VERSION ""

NS_ :

BS_:

BU_: EOCM2B_IMX6_HS EOCM2A_IMX6_HS EOCM2B_K2_HS EOCM2A_K2_HS TTPM_HS AMM_HS EBOOST_OBD_HS CGM_HS BSM_HS HCP_B_HS AVM_HS PFAF_HS LVMPC_HS DCDC_HS DEFC_HS VPM_HS IPC_HS V2V_HS TCP_HS CSM_HS EOCM2B_K1_HS EOCM2A_K1_HS TRCM_HS ESCM_SP_HS ICCM_B_HS AMP_HS FICM_HS ARS_HS MCP_B_HS MCP_A_HS ICCM_OBD_HS SAS_HS ACCM_HS VLBS_HS EBCM_OBD_HS HCP_T_HS EDI_HS PLCM_HS VITM_OBD_HS VICM_HS HCP_HS APPS_HS ICCM_HS EOCM_F_HS GPCM_HS VCM_HS HMIM_HS VES_HS Dummy_HS MCP_C_HS ONSTAR_HS EPS_HS TestTool_HS MCP_HS BCP_HS ALC_HS AHL_AFL_HS SADS_HS EPB_HS FCM_HS TCCM_HS RDCM_HS PTO_HS EBCM_HS ACC_HS BCM_HS TCM_HS ECM_HS

BO_ 1323 Tire_Temperature_Sensors_HS: 4 BCM_HS
 SG_ TireLRTmpV : 31|1@0+ (1,0) [0|1] ""  CGM_HS,LVMPC_HS,EDI_HS,EBCM_OBD_HS,EBCM_HS,ICCM_B_HS,ICCM_OBD_HS,ICCM_HS,RDCM_HS
 SG_ TireLRTmp : 30|7@0+ (1,-20) [-20|107] "deg C"  CGM_HS,LVMPC_HS,EDI_HS,EBCM_OBD_HS,EBCM_HS,ICCM_B_HS,ICCM_OBD_HS,ICCM_HS,RDCM_HS
 SG_ TireLFTmpV : 23|1@0+ (1,0) [0|1] ""  CGM_HS,LVMPC_HS,EDI_HS,EBCM_OBD_HS,EBCM_HS,ICCM_B_HS,ICCM_OBD_HS,ICCM_HS,RDCM_HS
 SG_ TireLFTmp : 22|7@0+ (1,-20) [-20|107] "deg C"  CGM_HS,LVMPC_HS,EDI_HS,EBCM_OBD_HS,EBCM_HS,ICCM_B_HS,ICCM_OBD_HS,ICCM_HS,RDCM_HS
 SG_ TireRRTmpV : 15|1@0+ (1,0) [0|1] ""  CGM_HS,LVMPC_HS,EDI_HS,EBCM_OBD_HS,EBCM_HS,ICCM_B_HS,ICCM_OBD_HS,ICCM_HS,RDCM_HS
 SG_ TireRRTmp : 14|7@0+ (1,-20) [-20|107] "deg C"  CGM_HS,LVMPC_HS,EDI_HS,EBCM_OBD_HS,EBCM_HS,ICCM_B_HS,ICCM_OBD_HS,ICCM_HS,RDCM_HS
 SG_ TireRFTmpV : 7|1@0+ (1,0) [0|1] ""  CGM_HS,LVMPC_HS,EDI_HS,EBCM_OBD_HS,EBCM_HS,ICCM_B_HS,ICCM_OBD_HS,ICCM_HS,RDCM_HS
 SG_ TireRFTmp : 6|7@0+ (1,-20) [-20|107] "deg C"  CGM_HS,LVMPC_HS,EDI_HS,EBCM_OBD_HS,EBCM_HS,ICCM_B_HS,ICCM_OBD_HS,ICCM_HS,RDCM_HS

BO_ 1247 PPEI_Chassis_Sys_General_Stat_2: 2 ICCM_HS
 SG_ RrPTCoolFanStatV : 7|1@0+ (1,0) [0|1] ""  CGM_HS,TCM_HS
 SG_ RrPTCoolFanStat : 6|1@0+ (1,0) [0|1] ""  CGM_HS,TCM_HS
 SG_ RrPTCoolFanSpPctCmd : 15|8@0+ (0.392157,0) [0|100.000035] "%"  CGM_HS,TCM_HS

BO_ 723 Prfrmnc_Trctn_Cntrl_Eng_Stat_HS: 4 ECM_HS
 SG_ TachEngSpd : 20|13@0+ (1,0) [0|8191] "rpm"  CGM_HS,BCM_HS
 SG_ PerfTrcEngSpdRqStat : 10|3@0+ (1,0) [0|7] ""  CGM_HS,EBCM_OBD_HS,EBCM_HS
 SG_ PerfTrcEngSpdLmtStat : 12|2@0+ (1,0) [0|3] ""  CGM_HS,EBCM_OBD_HS,EBCM_HS
 SG_ PerfTrcTrqRqStat : 2|3@0+ (1,0) [0|7] ""  CGM_HS,EBCM_OBD_HS,EBCM_HS
 SG_ PerfTrcTrqLmtStat : 4|2@0+ (1,0) [0|3] ""  CGM_HS,EBCM_OBD_HS,EBCM_HS

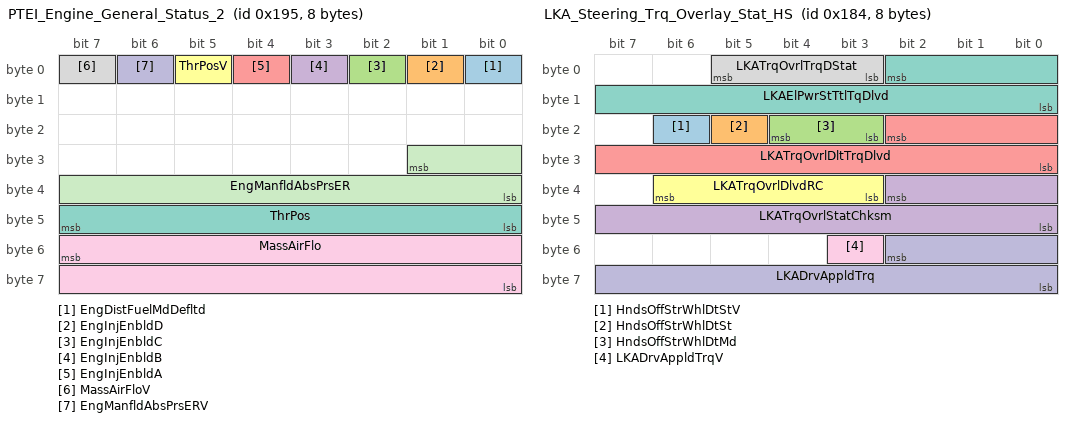
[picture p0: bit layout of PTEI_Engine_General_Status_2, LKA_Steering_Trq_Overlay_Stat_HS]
BO_ 405 PTEI_Engine_General_Status_2: 8 ECM_HS
 SG_ EngDistFuelMdDefltd : 0|1@0+ (1,0) [0|1] ""  CGM_HS,FICM_HS
 SG_ EngInjEnbldD : 1|1@0+ (1,0) [0|1] ""  CGM_HS,FICM_HS
 SG_ EngInjEnbldC : 2|1@0+ (1,0) [0|1] ""  CGM_HS,FICM_HS
 SG_ EngInjEnbldB : 3|1@0+ (1,0) [0|1] ""  CGM_HS,FICM_HS
 SG_ EngInjEnbldA : 4|1@0+ (1,0) [0|1] ""  CGM_HS,FICM_HS
 SG_ ThrPosV : 5|1@0+ (1,0) [0|1] ""  CGM_HS,FICM_HS
 SG_ ThrPos : 47|8@0+ (0.392157,0) [0|100.000035] "%"  CGM_HS,FICM_HS
 SG_ MassAirFloV : 7|1@0+ (1,0) [0|1] ""  CGM_HS,VCM_HS,FICM_HS
 SG_ MassAirFlo : 55|16@0+ (0.01,0) [0|655.35] "grams/s"  CGM_HS,VCM_HS,FICM_HS
 SG_ EngManfldAbsPrsERV : 6|1@0+ (1,0) [0|1] ""  CGM_HS,FICM_HS
 SG_ EngManfldAbsPrsER : 25|10@0+ (0.5,0) [0|511.5] "kPa"  CGM_HS,FICM_HS

BO_ 419 PTEI_Engine_Common_Use_1: 1 ECM_HS
 SG_ ClrCGMLgsDgInf : 6|1@0+ (1,0) [0|1] ""  CGM_HS
 SG_ EngRunng : 7|1@0+ (1,0) [0|1] ""  CGM_HS,TCP_HS,ONSTAR_HS,HCP_B_HS,HCP_T_HS,BCM_HS,DCDC_HS,TCCM_HS,EBCM_OBD_HS,EBCM_HS,MCP_C_HS,MCP_B_HS,MCP_A_HS,FICM_HS,TCM_HS,HCP_HS,BCP_HS

BO_ 289 ADASIS_RawData_Multiplexed_HS: 8 HMIM_HS
 SG_ ARDM_RawData : 4|61@0+ (1,0) [0|2.3058430092e+18] ""  CGM_HS,FCM_HS,EOCM_F_HS,V2V_HS
 SG_ ARDM_MsgType : 7|3@0+ (1,0) [0|7] ""  CGM_HS,FCM_HS,EOCM_F_HS,V2V_HS

BO_ 1268 PPEI_Engine_General_Status_9: 2 ECM_HS
 SG_ EngAirFltLfRmn : 14|7@0+ (1,0) [0|127] "%"  CGM_HS,BCM_HS
 SG_ EngAirFltMonSt : 2|3@0+ (1,0) [0|7] ""  CGM_HS,BCM_HS

BO_ 800 CIB_Autonomous_Braking_Req_HS: 6 FCM_HS
 SG_ FCACtrlBrkSysCmdPrtVl : 27|20@0+ (1,0) [0|1048575] ""  EOCM2A_K1_HS,EBCM_OBD_HS,EBCM_HS
 SG_ FCACBSC_CtrlAcc : 11|12@0- (0.01,0) [-20.48|20.47] "m/s^2"  EOCM2A_K1_HS,EBCM_OBD_HS,EBCM_HS
 SG_ FCACBSC_AutBrkRpRt : 14|3@0+ (1,0) [0|7] ""  EOCM2A_K1_HS,EBCM_OBD_HS,EBCM_HS
 SG_ FCACBSC_AutBrkRqTp : 2|4@0+ (1,0) [0|15] ""  EOCM2A_K1_HS,EBCM_OBD_HS,EBCM_HS
 SG_ FCACBSC_AutBrkRqd : 3|1@0+ (1,0) [0|1] ""  EOCM2A_K1_HS,EBCM_OBD_HS,EBCM_HS
 SG_ FCACtrlBrkSysCmdRC : 5|2@0+ (1,0) [0|3] ""  EBCM_OBD_HS,EBCM_HS,EOCM2A_K1_HS

BO_ 388 LKA_Steering_Trq_Overlay_Stat_HS: 8 EPS_HS
 SG_ HndsOffStrWhlDtStV : 22|1@0+ (1,0) [0|1] ""  CGM_HS,EOCM_F_HS,FCM_HS
 SG_ HndsOffStrWhlDtSt : 21|1@0+ (1,0) [0|1] ""  CGM_HS,EOCM_F_HS,FCM_HS
 SG_ HndsOffStrWhlDtMd : 20|2@0+ (1,0) [0|3] ""  CGM_HS,EOCM_F_HS,FCM_HS
 SG_ LKATrqOvrlStatChksm : 34|11@0+ (1,0) [0|2047] ""  CGM_HS,EOCM_F_HS,FCM_HS
 SG_ LKATrqOvrlDltTrqDlvd : 18|11@0- (0.01,0) [-10.24|10.23] "Nm"  CGM_HS,EOCM_F_HS,FCM_HS
 SG_ LKATrqOvrlDlvdRC : 38|4@0+ (1,0) [0|15] ""  CGM_HS,EOCM_F_HS,FCM_HS
 SG_ LKAElPwrStTtlTqDlvd : 2|11@0- (0.01,0) [-10.24|10.23] "Nm"  CGM_HS,EOCM_F_HS,FCM_HS
 SG_ LKATrqOvrlTrqDStat : 5|3@0+ (1,0) [0|7] ""  CGM_HS,EOCM_F_HS,FCM_HS
 SG_ LKADrvAppldTrqV : 51|1@0+ (1,0) [0|1] ""  CGM_HS,EOCM_F_HS,FCM_HS
 SG_ LKADrvAppldTrq : 50|11@0- (0.01,0) [-10.24|10.23] "Nm"  CGM_HS,EOCM_F_HS,FCM_HS

BO_ 384 LKA_Steering_Torque_Cmd_HS: 4 FCM_HS
 SG_ LKATqOvrDltCmdPrtVl : 19|12@0+ (1,0) [0|4095] ""  EPS_HS
 SG_ LKATqOvrDltCmdRC : 5|2@0+ (1,0) [0|3] ""  EPS_HS
 SG_ LKATODC_TrqVl : 2|11@0- (0.01,0) [-10.24|10.23] "Nm"  BCM_HS,EPS_HS
 SG_ LKATODC_TrqRqAct : 3|1@0+ (1,0) [0|1] ""  BCM_HS,EPS_HS

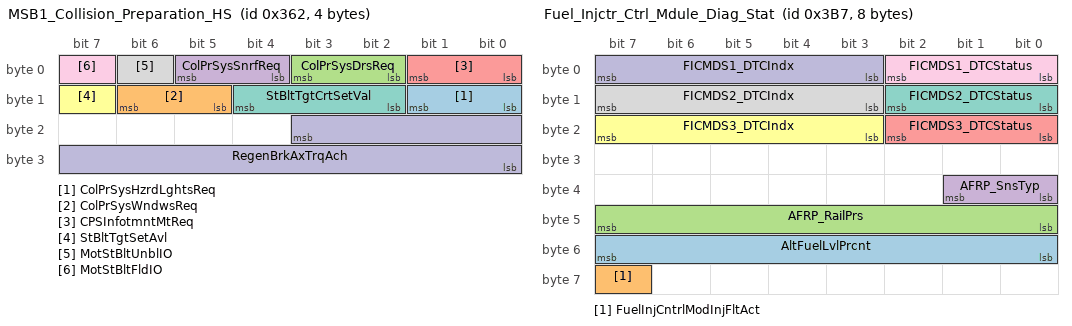
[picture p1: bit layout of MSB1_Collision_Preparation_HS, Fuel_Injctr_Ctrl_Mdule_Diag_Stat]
BO_ 866 MSB1_Collision_Preparation_HS: 4 EBCM_HS
 SG_ ColPrSysHzrdLghtsReq : 9|2@0+ (1,0) [0|3] ""  CGM_HS,BCM_HS
 SG_ ColPrSysWndwsReq : 14|2@0+ (1,0) [0|3] ""  CGM_HS,BCM_HS
 SG_ ColPrSysDrsReq : 3|2@0+ (1,0) [0|3] ""  CGM_HS,BCM_HS
 SG_ ColPrSysSnrfReq : 5|2@0+ (1,0) [0|3] ""  CGM_HS,BCM_HS
 SG_ CPSInfotmntMtReq : 1|2@0+ (1,0) [0|3] ""  CGM_HS,BCM_HS
 SG_ StBltTgtSetAvl : 15|1@0+ (1,0) [0|1] ""  CGM_HS,BCM_HS
 SG_ StBltTgtCrtSetVal : 12|3@0+ (1,0) [0|7] ""  CGM_HS,BCM_HS
 SG_ MotStBltUnblIO : 6|1@0+ (1,0) [0|1] ""  CGM_HS,BCM_HS
 SG_ MotStBltFldIO : 7|1@0+ (1,0) [0|1] ""  CGM_HS,BCM_HS
 SG_ RegenBrkAxTrqAch : 19|12@0+ (2,0) [0|8190] "Nm"  CGM_HS,BSM_HS,VICM_HS

BO_ 951 Fuel_Injctr_Ctrl_Mdule_Diag_Stat: 8 FICM_HS
 SG_ AltFuelLvlPrcnt : 55|8@0+ (0.392157,0) [0|100.000035] "%"  CGM_HS,ECM_HS
 SG_ FuelInjCntrlModInjFltAct : 63|1@0+ (1,0) [0|1] ""  CGM_HS,ECM_HS
 SG_ AFRP_RailPrs : 47|8@0+ (3,0) [0|765] "kPa"  CGM_HS,ECM_HS
 SG_ AFRP_SnsTyp : 33|2@0+ (1,0) [0|3] ""  CGM_HS,ECM_HS
 SG_ FICMDS3_DTCStatus : 18|3@0+ (1,0) [0|7] ""  CGM_HS,ECM_HS
 SG_ FICMDS3_DTCIndx : 23|5@0+ (1,0) [0|31] ""  CGM_HS,ECM_HS
 SG_ FICMDS2_DTCStatus : 10|3@0+ (1,0) [0|7] ""  CGM_HS,ECM_HS
 SG_ FICMDS2_DTCIndx : 15|5@0+ (1,0) [0|31] ""  CGM_HS,ECM_HS
 SG_ FICMDS1_DTCStatus : 2|3@0+ (1,0) [0|7] ""  CGM_HS,ECM_HS
 SG_ FICMDS1_DTCIndx : 7|5@0+ (1,0) [0|31] ""  CGM_HS,ECM_HS

BO_ 949 FICM_BiFuel_Control_Requests: 8 FICM_HS
 SG_ AltFuelRFuelTrmLmtOff : 61|6@0- (0.01,0) [-0.32|0.31] ""  CGM_HS,ECM_HS
 SG_ AltFuelLnFuelTrmLmtOff : 53|6@0- (0.01,0) [-0.32|0.31] ""  CGM_HS,ECM_HS
 SG_ AltFuelInjMinPlsOffst : 39|8@0- (0.0313725,0) [-4.01568|3.9843075] "grams/s"  CGM_HS,ECM_HS
 SG_ AltFuelInjOpnOffst : 31|8@0- (0.0313725,0) [-4.01568|3.9843075] "grams/s"  CGM_HS,ECM_HS
 SG_ AltFuelInjFlwOffst : 23|8@0- (0.0313725,0) [-4.01568|3.9843075] "grams/s"  CGM_HS,ECM_HS
 SG_ AltFuelEqvlntRatBsOffst : 15|8@0- (0.000392157,0) [-0.050196096|0.049803939] ""  CGM_HS,ECM_HS
 SG_ AltFuelPst02BsOffst : 7|8@0- (4,0) [-512|508] "mVolts"  CGM_HS,ECM_HS

BO_ 1223 PPEI_Propulsion_Sys_Gen_Status: 3 ECM_HS
 SG_ PropSysOffTmeV : 5|1@0+ (1,0) [0|1] ""  CGM_HS,HCP_B_HS,HCP_T_HS,EBCM_OBD_HS,EBCM_HS,MCP_C_HS,TCM_HS,HCP_HS,BCP_HS,MCP_B_HS,MCP_A_HS,BSM_HS,VICM_HS
 SG_ PropSysOffTmeM : 4|1@0+ (1,0) [0|1] ""  CGM_HS,HCP_B_HS,BSM_HS,HCP_T_HS,EBCM_OBD_HS,EBCM_HS,MCP_C_HS,TCM_HS,HCP_HS,BCP_HS,MCP_B_HS,MCP_A_HS,VICM_HS
 SG_ PropSysOffTme : 3|12@0+ (0.5,0) [0|2047.5] "min"  CGM_HS,HCP_B_HS,BSM_HS,HCP_T_HS,EBCM_OBD_HS,EBCM_HS,MCP_C_HS,TCM_HS,HCP_HS,BCP_HS,MCP_B_HS,MCP_A_HS,VICM_HS

BO_ 1227 PPEI_Charging_System_Gen_Status: 4 VICM_HS
 SG_ BattThrmlCondOffTmeV : 21|1@0+ (1,0) [0|1] ""  CGM_HS,HCP_T_HS,TCM_HS,HCP_HS,ECM_HS
 SG_ BattThrmlCondOffTmeM : 20|1@0+ (1,0) [0|1] ""  CGM_HS,HCP_T_HS,TCM_HS,HCP_HS,ECM_HS
 SG_ BattThrmlCondOffTme : 19|12@0+ (0.5,0) [0|2047.5] "min"  CGM_HS,HCP_T_HS,TCM_HS,HCP_HS,ECM_HS
 SG_ OffBrdChrgOffTmeV : 5|1@0+ (1,0) [0|1] ""  CGM_HS,HCP_T_HS,TCM_HS,HCP_HS,ECM_HS
 SG_ OffBrdChrgOffTmeM : 4|1@0+ (1,0) [0|1] ""  CGM_HS,HCP_T_HS,TCM_HS,HCP_HS,ECM_HS
 SG_ OffBrdChrgOffTme : 3|12@0+ (0.5,0) [0|2047.5] "min"  CGM_HS,HCP_T_HS,TCM_HS,HCP_HS,ECM_HS

BO_ 543 PTO_Customization_Request_HS: 3 BCM_HS
 SG_ HdStV : 3|1@0+ (1,0) [0|1] ""  CGM_HS,PTO_HS
 SG_ HdSt : 5|2@0+ (1,0) [0|3] ""  CGM_HS,PTO_HS
 SG_ PTOTpStpSpdCsStReq : 2|3@0+ (1,0) [0|7] ""  CGM_HS,PTO_HS
 SG_ PTOStdbySpdCsStReq : 14|3@0+ (1,0) [0|7] ""  CGM_HS,PTO_HS
 SG_ PTOEngRnTmrCsStRq : 11|4@0+ (1,0) [0|15] ""  CGM_HS,PTO_HS
 SG_ PTOSet2SpdCsStReq : 23|4@0+ (1,0) [0|15] ""  CGM_HS,PTO_HS
 SG_ PTOSet1SpdCsStReq : 19|4@0+ (1,0) [0|15] ""  CGM_HS,PTO_HS

BO_ 544 PTO_Status_HS: 5 PTO_HS
 SG_ PTOMobModTrnsInGrIO : 31|1@0+ (1,0) [0|1] ""  CGM_HS,BCM_HS
 SG_ PTOManTransInGrIO : 21|1@0+ (1,0) [0|1] ""  CGM_HS,BCM_HS
 SG_ PTOServIndOn : 20|1@0+ (1,0) [0|1] ""  CGM_HS,BCM_HS
 SG_ PTOEngUpnBrkRelIO : 23|1@0+ (1,0) [0|1] ""  CGM_HS,BCM_HS
 SG_ PTOAccelUpnBrkRelIO : 22|1@0+ (1,0) [0|1] ""  CGM_HS,BCM_HS
 SG_ PTOAudExtAlertReq : 19|1@0+ (1,0) [0|1] ""  CGM_HS,BCM_HS
 SG_ PTOTransInGearIO : 13|1@0+ (1,0) [0|1] ""  CGM_HS,BCM_HS
 SG_ PTOTpStpSpdCsStAvl : 10|1@0+ (1,0) [0|1] ""  CGM_HS,BCM_HS
 SG_ PTOTpStSpdCsCrStVal : 26|3@0+ (1,0) [0|7] ""  CGM_HS,BCM_HS
 SG_ PTOStdbySpdCsStAvl : 12|1@0+ (1,0) [0|1] ""  CGM_HS,BCM_HS
 SG_ PTOStdbSpdCsCrStVal : 18|3@0+ (1,0) [0|7] ""  CGM_HS,BCM_HS
 SG_ PTOSetPrkBrkIO : 14|1@0+ (1,0) [0|1] ""  CGM_HS,BCM_HS
 SG_ PTOSet2SpdCsStAvl : 9|1@0+ (1,0) [0|1] ""  CGM_HS,BCM_HS
 SG_ PTOSet2SpdCsCrStVal : 39|4@0+ (1,0) [0|15] ""  CGM_HS,BCM_HS
 SG_ PTOSet1SpdCsStAvl : 8|1@0+ (1,0) [0|1] ""  CGM_HS,BCM_HS
 SG_ PTOSet1SpdCsCrStVal : 35|4@0+ (1,0) [0|15] ""  CGM_HS,BCM_HS
 SG_ PTORelCltPedIO : 15|1@0+ (1,0) [0|1] ""  CGM_HS,BCM_HS
 SG_ PTORelBrkPedIO : 0|1@0+ (1,0) [0|1] ""  CGM_HS,BCM_HS
 SG_ PTORelAccPedIO : 1|1@0+ (1,0) [0|1] ""  CGM_HS,BCM_HS
 SG_ PTORedEngSpdIO : 2|1@0+ (1,0) [0|1] ""  CGM_HS,BCM_HS
 SG_ PTOPrsRelCltPedIO : 3|1@0+ (1,0) [0|1] ""  CGM_HS,BCM_HS
 SG_ PTOPrsRelBrkPedIO : 4|1@0+ (1,0) [0|1] ""  CGM_HS,BCM_HS
 SG_ PTOEngRnTmrCsStAvl : 11|1@0+ (1,0) [0|1] ""  CGM_HS,BCM_HS
 SG_ PTOEnRnTmCsCrStVal : 30|4@0+ (1,0) [0|15] ""  CGM_HS,BCM_HS
 SG_ PTOEngmntStatInd : 6|2@0+ (1,0) [0|3] ""  CGM_HS,BCM_HS
 SG_ PTODisengCrsCntlIO : 7|1@0+ (1,0) [0|1] ""  CGM_HS,BCM_HS

BO_ 901 PTEI_Hybrid_Trans_Status_3: 3 TCM_HS
 SG_ TrnsMtrBCoolFlwEst : 15|8@0+ (0.05,0) [0|12.75] "l/min"  CGM_HS,HCP_HS
 SG_ TrnsMtrACoolFlwEst : 7|8@0+ (0.05,0) [0|12.75] "l/min"  CGM_HS,HCP_HS
 SG_ TrnsLubeFlwEst : 23|8@0+ (0.0625,0) [0|15.9375] "l/min"  CGM_HS,HCP_HS

BO_ 1032 LGT_ControlHighBeamGlare_HS: 2 FCM_HS
 SG_ RdTyp : 5|3@0+ (1,0) [0|7] ""  CGM_HS,EOCM2B_K1_HS,AHL_AFL_HS
 SG_ FwdCamSysOpStat : 10|3@0+ (1,0) [0|7] ""  CGM_HS,EOCM2B_K1_HS,AHL_AFL_HS
 SG_ EnvIllum : 2|3@0+ (1,0) [0|7] ""  CGM_HS,EOCM2B_K1_HS,AHL_AFL_HS
 SG_ AutoHgBmSts : 7|2@0+ (1,0) [0|3] ""  CGM_HS,EOCM2B_K1_HS,AHL_AFL_HS

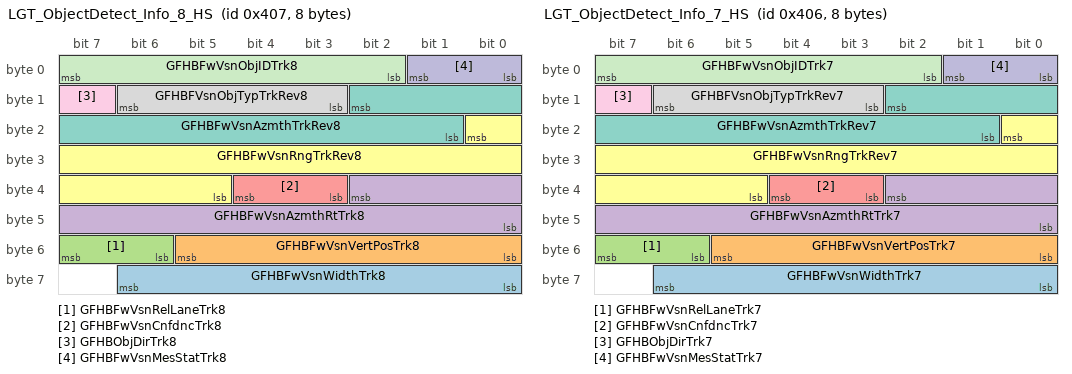
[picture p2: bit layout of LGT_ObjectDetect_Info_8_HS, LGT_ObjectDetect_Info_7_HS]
BO_ 1031 LGT_ObjectDetect_Info_8_HS: 8 EOCM_F_HS
 SG_ GFHBFwVsnWidthTrk8 : 62|7@0+ (0.1,0) [0|12.7] "deg"  CGM_HS,EOCM2B_K1_HS,AHL_AFL_HS
 SG_ GFHBFwVsnVertPosTrk8 : 53|6@0+ (0.25,-3) [-3|12.75] "deg"  CGM_HS,EOCM2B_K1_HS,AHL_AFL_HS
 SG_ GFHBFwVsnRelLaneTrk8 : 55|2@0+ (1,0) [0|3] ""  CGM_HS,EOCM2B_K1_HS,AHL_AFL_HS
 SG_ GFHBFwVsnAzmthRtTrk8 : 34|11@0- (0.125,0) [-128|127.875] "deg/s"  CGM_HS,EOCM2B_K1_HS,AHL_AFL_HS
 SG_ GFHBFwVsnCnfdncTrk8 : 36|2@0+ (1,0) [0|3] ""  CGM_HS,EOCM2B_K1_HS,AHL_AFL_HS
 SG_ GFHBFwVsnRngTrkRev8 : 16|12@0+ (0.2,0) [0|819] "m"  CGM_HS,EOCM2B_K1_HS,AHL_AFL_HS
 SG_ GFHBFwVsnAzmthTrkRev8 : 10|10@0- (0.05,0) [-25.6|25.55] "deg"  CGM_HS,EOCM2B_K1_HS,AHL_AFL_HS
 SG_ GFHBFVsnObjTypTrkRev8 : 14|4@0+ (1,0) [0|15] ""  CGM_HS,EOCM2B_K1_HS,AHL_AFL_HS
 SG_ GFHBObjDirTrk8 : 15|1@0+ (1,0) [0|1] ""  CGM_HS,EOCM2B_K1_HS,AHL_AFL_HS
 SG_ GFHBFwVsnMesStatTrk8 : 1|2@0+ (1,0) [0|3] ""  CGM_HS,EOCM2B_K1_HS,AHL_AFL_HS
 SG_ GFHBFwVsnObjIDTrk8 : 7|6@0+ (1,0) [0|63] ""  CGM_HS,EOCM2B_K1_HS,AHL_AFL_HS

BO_ 1030 LGT_ObjectDetect_Info_7_HS: 8 EOCM_F_HS
 SG_ GFHBFwVsnWidthTrk7 : 62|7@0+ (0.1,0) [0|12.7] "deg"  CGM_HS,EOCM2B_K1_HS,AHL_AFL_HS
 SG_ GFHBFwVsnVertPosTrk7 : 53|6@0+ (0.25,-3) [-3|12.75] "deg"  CGM_HS,EOCM2B_K1_HS,AHL_AFL_HS
 SG_ GFHBFwVsnRelLaneTrk7 : 55|2@0+ (1,0) [0|3] ""  CGM_HS,EOCM2B_K1_HS,AHL_AFL_HS
 SG_ GFHBFwVsnAzmthRtTrk7 : 34|11@0- (0.125,0) [-128|127.875] "deg/s"  CGM_HS,EOCM2B_K1_HS,AHL_AFL_HS
 SG_ GFHBFwVsnCnfdncTrk7 : 36|2@0+ (1,0) [0|3] ""  CGM_HS,EOCM2B_K1_HS,AHL_AFL_HS
 SG_ GFHBFwVsnRngTrkRev7 : 16|12@0+ (0.2,0) [0|819] "m"  CGM_HS,EOCM2B_K1_HS,AHL_AFL_HS
 SG_ GFHBFwVsnAzmthTrkRev7 : 10|10@0- (0.05,0) [-25.6|25.55] "deg"  CGM_HS,EOCM2B_K1_HS,AHL_AFL_HS
 SG_ GFHBFVsnObjTypTrkRev7 : 14|4@0+ (1,0) [0|15] ""  CGM_HS,EOCM2B_K1_HS,AHL_AFL_HS
 SG_ GFHBObjDirTrk7 : 15|1@0+ (1,0) [0|1] ""  CGM_HS,EOCM2B_K1_HS,AHL_AFL_HS
 SG_ GFHBFwVsnMesStatTrk7 : 1|2@0+ (1,0) [0|3] ""  CGM_HS,EOCM2B_K1_HS,AHL_AFL_HS
 SG_ GFHBFwVsnObjIDTrk7 : 7|6@0+ (1,0) [0|63] ""  CGM_HS,EOCM2B_K1_HS,AHL_AFL_HS

BO_ 479 PPEI_Propulsion_Gen_Stat_1_HS: 3 HCP_HS
 SG_ PTAVHEnbld : 4|1@0+ (1,0) [0|1] ""  CGM_HS,EBCM_OBD_HS,EBCM_HS
 SG_ PTAVHActv : 3|1@0+ (1,0) [0|1] ""  CGM_HS,EBCM_OBD_HS,EBCM_HS
 SG_ EngAutoStpNotProb : 2|1@0+ (1,0) [0|1] ""  CGM_HS,TCM_HS,ECM_HS,BCM_HS
 SG_ EASSI_UnsdRsrvd2 : 8|1@0+ (1,0) [0|1] ""  TCP_HS,ONSTAR_HS,FCM_HS,EOCM_F_HS,ESCM_SP_HS,CGM_HS,TCM_HS,ECM_HS,BCM_HS,EBCM_OBD_HS,EBCM_HS,TCCM_HS
 SG_ EASSI_StlDetd : 10|1@0+ (1,0) [0|1] ""  TCP_HS,ONSTAR_HS,FCM_HS,EOCM_F_HS,ESCM_SP_HS,CGM_HS,TCM_HS,ECM_HS,BCM_HS,EBCM_OBD_HS,EBCM_HS,TCCM_HS
 SG_ EASSI_TrqDetd : 11|1@0+ (1,0) [0|1] ""  TCP_HS,ONSTAR_HS,FCM_HS,EOCM_F_HS,ESCM_SP_HS,CGM_HS,TCM_HS,ECM_HS,BCM_HS,EBCM_OBD_HS,EBCM_HS,TCCM_HS
 SG_ EASSI_FuelReqOn : 12|1@0+ (1,0) [0|1] ""  TCP_HS,ONSTAR_HS,FCM_HS,EOCM_F_HS,ESCM_SP_HS,CGM_HS,TCM_HS,ECM_HS,BCM_HS,EBCM_OBD_HS,EBCM_HS,TCCM_HS
 SG_ EASSI_StrtTyp : 15|3@0+ (1,0) [0|7] ""  TCP_HS,ONSTAR_HS,FCM_HS,EOCM_F_HS,ESCM_SP_HS,CGM_HS,TCM_HS,ECM_HS,BCM_HS,EBCM_OBD_HS,EBCM_HS,TCCM_HS
 SG_ EASSI_StrtStpSt : 1|2@0+ (1,0) [0|3] ""  TCP_HS,ONSTAR_HS,FCM_HS,EOCM_F_HS,ESCM_SP_HS,CGM_HS,TCM_HS,ECM_HS,BCM_HS,EBCM_OBD_HS,EBCM_HS,TCCM_HS
 SG_ EASSI_TorqDetdIndet : 9|1@0+ (1,0) [0|1] ""  TCP_HS,ONSTAR_HS,FCM_HS,EOCM_F_HS,ESCM_SP_HS,CGM_HS,TCM_HS,ECM_HS,BCM_HS,EBCM_OBD_HS,EBCM_HS,TCCM_HS
 SG_ ASIRI_Indication08 : 16|1@0+ (1,0) [0|1] ""  CGM_HS,BCM_HS
 SG_ ASIRI_Indication07 : 17|1@0+ (1,0) [0|1] ""  CGM_HS,BCM_HS
 SG_ ASIRI_Indication06 : 18|1@0+ (1,0) [0|1] ""  CGM_HS,BCM_HS
 SG_ ASIRI_Indication05 : 19|1@0+ (1,0) [0|1] ""  CGM_HS,BCM_HS
 SG_ ASIRI_Indication04 : 20|1@0+ (1,0) [0|1] ""  CGM_HS,BCM_HS
 SG_ ASIRI_Indication03 : 21|1@0+ (1,0) [0|1] ""  CGM_HS,BCM_HS
 SG_ ASIRI_Indication02 : 22|1@0+ (1,0) [0|1] ""  CGM_HS,BCM_HS
 SG_ ASIRI_Indication01 : 23|1@0+ (1,0) [0|1] ""  CGM_HS,BCM_HS
 SG_ PTWrmgWtToShftIO : 5|1@0+ (1,0) [0|1] ""  CGM_HS,BCM_HS
 SG_ PrplsnSysAtv : 7|1@0+ (1,0) [0|1] ""  TCP_HS,ONSTAR_HS,RDCM_HS,FCM_HS,EOCM_F_HS,V2V_HS,ESCM_SP_HS,EBOOST_OBD_HS,CGM_HS,HCP_T_HS,TRCM_HS,EPB_HS,TCM_HS,ECM_HS,TCCM_HS,BSM_HS,VICM_HS,ICCM_B_HS,ICCM_OBD_HS,ICCM_HS,EBCM_OBD_HS,EBCM_HS,VITM_OBD_HS
 SG_ PTShftLvrLckRqd : 6|1@0+ (1,0) [0|1] ""  CGM_HS,BCM_HS

BO_ 211 PPEI_Hybrid_General_Status_3_HS: 2 HCP_HS
 SG_ ActAxleTrqV : 7|1@0+ (1,0) [0|1] ""  EOCM2B_K2_HS,EOCM2B_K1_HS,EOCM2A_K2_HS,EOCM2A_K1_HS,CSM_HS,HMIM_HS,AMP_HS,CGM_HS,HCP_T_HS,FCM_HS,SADS_HS,ICCM_B_HS,ICCM_OBD_HS,ICCM_HS,TCM_HS,ECM_HS,EPS_HS,EBCM_OBD_HS,EBCM_HS,BCP_HS,BSM_HS,VICM_HS,TCCM_HS,ACC_HS
 SG_ ActAxleTrq : 6|15@0+ (2,-22534) [-22534|43000] "Nm"  EOCM2B_K2_HS,EOCM2B_K1_HS,EOCM2A_K2_HS,EOCM2A_K1_HS,CSM_HS,HMIM_HS,AMP_HS,CGM_HS,HCP_T_HS,FCM_HS,SADS_HS,ICCM_B_HS,ICCM_OBD_HS,ICCM_HS,EBCM_OBD_HS,EBCM_HS,TCM_HS,ECM_HS,BCP_HS,EPS_HS,TCCM_HS,BSM_HS,VICM_HS,ACC_HS

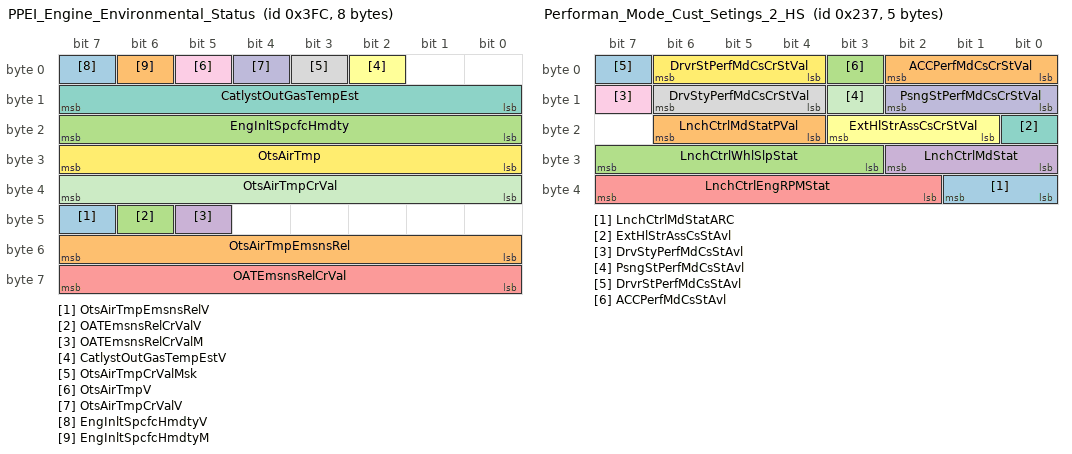
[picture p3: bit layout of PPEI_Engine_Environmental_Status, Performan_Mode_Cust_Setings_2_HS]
BO_ 1020 PPEI_Engine_Environmental_Status: 8 ECM_HS
 SG_ OtsAirTmpEmsnsRelV : 47|1@0+ (1,0) [0|1] ""  CGM_HS,BSM_HS,VICM_HS,HCP_B_HS
 SG_ OtsAirTmpEmsnsRel : 55|8@0+ (0.5,-40) [-40|87.5] "deg C"  CGM_HS,BSM_HS,VICM_HS,HCP_B_HS
 SG_ OATEmsnsRelCrValV : 46|1@0+ (1,0) [0|1] ""  CGM_HS,BSM_HS,VICM_HS,HCP_B_HS
 SG_ OATEmsnsRelCrValM : 45|1@0+ (1,0) [0|1] ""  CGM_HS,BSM_HS,VICM_HS,HCP_B_HS
 SG_ OATEmsnsRelCrVal : 63|8@0+ (0.5,-40) [-40|87.5] "deg C"  CGM_HS,BSM_HS,VICM_HS,HCP_B_HS
 SG_ CatlystOutGasTempEstV : 2|1@0+ (1,0) [0|1] ""  CGM_HS,BSM_HS,VICM_HS
 SG_ CatlystOutGasTempEst : 15|8@0+ (5,-40) [-40|1235] "deg C"  CGM_HS,BSM_HS,VICM_HS
 SG_ OtsAirTmpCrValMsk : 3|1@0+ (1,0) [0|1] ""  EOCM2A_K1_HS,V2V_HS,TCM_HS,EPB_HS,BSM_HS,VICM_HS,BCM_HS
 SG_ OtsAirTmpV : 5|1@0+ (1,0) [0|1] ""  EOCM2A_K1_HS,CGM_HS,EPB_HS,BSM_HS,VICM_HS,PFAF_HS,BCM_HS
 SG_ OtsAirTmpCrValV : 4|1@0+ (1,0) [0|1] ""  EOCM2A_K1_HS,V2V_HS,TCM_HS,EPB_HS,BSM_HS,VICM_HS,BCM_HS
 SG_ OtsAirTmpCrVal : 39|8@0+ (0.5,-40) [-40|87.5] "deg C"  EOCM2A_K1_HS,V2V_HS,TCM_HS,EPB_HS,BSM_HS,VICM_HS,BCM_HS
 SG_ OtsAirTmp : 31|8@0+ (0.5,-40) [-40|87.5] "deg C"  EOCM2A_K1_HS,CGM_HS,EPB_HS,BSM_HS,VICM_HS,PFAF_HS,BCM_HS
 SG_ EngInltSpcfcHmdtyV : 7|1@0+ (1,0) [0|1] ""  CGM_HS,BSM_HS,VICM_HS,BCM_HS,EBCM_OBD_HS,EBCM_HS
 SG_ EngInltSpcfcHmdtyM : 6|1@0+ (1,0) [0|1] ""  CGM_HS,BSM_HS,VICM_HS,BCM_HS,EBCM_OBD_HS,EBCM_HS
 SG_ EngInltSpcfcHmdty : 23|8@0+ (0.0196078,0) [0|4.999989] "% water"  CGM_HS,BSM_HS,VICM_HS,BCM_HS,EBCM_OBD_HS,EBCM_HS

BO_ 567 Performan_Mode_Cust_Setings_2_HS: 5 EBCM_HS
 SG_ LnchCtrlMdStatARC : 33|2@0+ (1,0) [0|3] ""  CGM_HS,ECM_HS
 SG_ LnchCtrlMdStatPVal : 22|3@0+ (1,0) [0|7] ""  CGM_HS,ECM_HS
 SG_ LnchCtrlWhlSlpStat : 31|5@0+ (1,0) [0|31] ""  CGM_HS,BCM_HS
 SG_ LnchCtrlMdStat : 26|3@0+ (1,0) [0|7] ""  CGM_HS,ECM_HS,BCM_HS
 SG_ LnchCtrlEngRPMStat : 39|6@0+ (1,0) [0|63] ""  CGM_HS,BCM_HS
 SG_ ExtHlStrAssCsCrStVal : 19|3@0+ (1,0) [0|7] ""  CGM_HS,BCM_HS
 SG_ ExtHlStrAssCsStAvl : 16|1@0+ (1,0) [0|1] ""  CGM_HS,BCM_HS
 SG_ DrvStyPerfMdCsCrStVal : 14|3@0+ (1,0) [0|7] ""  CGM_HS,BCM_HS
 SG_ DrvStyPerfMdCsStAvl : 15|1@0+ (1,0) [0|1] ""  CGM_HS,BCM_HS
 SG_ PsngStPerfMdCsCrStVal : 10|3@0+ (1,0) [0|7] ""  CGM_HS,BCM_HS
 SG_ PsngStPerfMdCsStAvl : 11|1@0+ (1,0) [0|1] ""  CGM_HS,BCM_HS
 SG_ DrvrStPerfMdCsCrStVal : 6|3@0+ (1,0) [0|7] ""  CGM_HS,BCM_HS
 SG_ DrvrStPerfMdCsStAvl : 7|1@0+ (1,0) [0|1] ""  CGM_HS,BCM_HS
 SG_ ACCPerfMdCsCrStVal : 2|3@0+ (1,0) [0|7] ""  CGM_HS,BCM_HS
 SG_ ACCPerfMdCsStAvl : 3|1@0+ (1,0) [0|1] ""  CGM_HS,BCM_HS

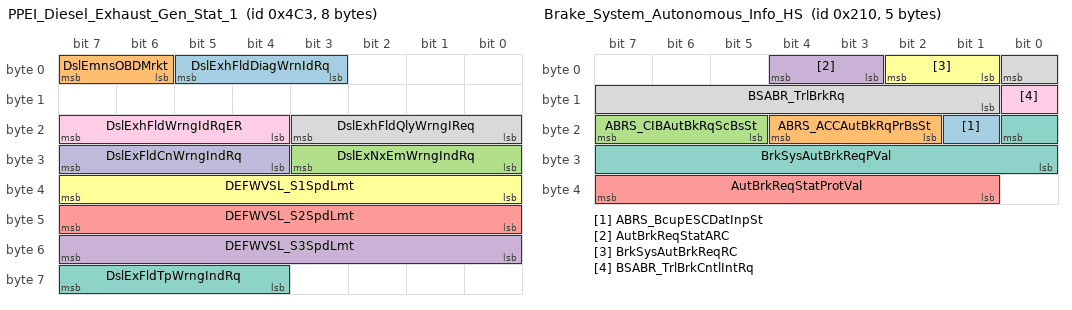
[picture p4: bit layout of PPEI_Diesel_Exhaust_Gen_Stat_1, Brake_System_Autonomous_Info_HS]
BO_ 1219 PPEI_Diesel_Exhaust_Gen_Stat_1: 8 ECM_HS
 SG_ DslExhFldDiagWrnIdRq : 5|3@0+ (1,0) [0|7] ""  CGM_HS,BCM_HS
 SG_ DslEmnsOBDMrkt : 7|2@0+ (1,0) [0|3] ""  CGM_HS,BCM_HS
 SG_ DslExNxEmWrngIndRq : 27|4@0+ (1,0) [0|15] ""  CGM_HS,BCM_HS
 SG_ DEFWVSL_S3SpdLmt : 55|8@0+ (1,0) [0|255] "km / h"  CGM_HS,BCM_HS
 SG_ DEFWVSL_S2SpdLmt : 47|8@0+ (1,0) [0|255] "km / h"  CGM_HS,BCM_HS
 SG_ DEFWVSL_S1SpdLmt : 39|8@0+ (1,0) [0|255] "km / h"  CGM_HS,BCM_HS
 SG_ DslExFldTpWrngIndRq : 63|4@0+ (1,0) [0|15] ""  CGM_HS,BCM_HS
 SG_ DslExhFldQlyWrngIReq : 19|4@0+ (1,0) [0|15] ""  CGM_HS,BCM_HS
 SG_ DslExhFldWrngIdRqER : 23|4@0+ (1,0) [0|15] ""  CGM_HS,BCM_HS,TCP_HS,ONSTAR_HS
 SG_ DslExFldCnWrngIndRq : 31|4@0+ (1,0) [0|15] ""  CGM_HS,BCM_HS

BO_ 372 Active_Rear_Steer_Fail_Indctn_HS: 5 EBCM_HS
 SG_ ARSOpStat : 5|3@0+ (1,0) [0|7] ""  CGM_HS,EOCM2B_K1_HS,EOCM2A_K1_HS,FCM_HS
 SG_ ARSAlgmtCmplt : 1|1@0+ (1,0) [0|1] ""  CGM_HS,FCM_HS,EOCM2B_K1_HS,EOCM2A_K1_HS
 SG_ ARSActAnglV : 2|1@0+ (1,0) [0|1] ""  CGM_HS,FCM_HS,EOCM2B_K1_HS,EOCM2A_K1_HS
 SG_ ARSActAngl : 10|11@0- (0.01,0) [-10.24|10.23] "deg"  CGM_HS,FCM_HS,EOCM2B_K1_HS,EOCM2A_K1_HS
 SG_ ARSActAngStsRegtChksm : 26|11@0+ (1,0) [0|2047] ""  CGM_HS,FCM_HS,EOCM2B_K1_HS,EOCM2A_K1_HS
 SG_ ARSActAngRegtARC : 7|2@0+ (1,0) [0|3] ""  CGM_HS,FCM_HS,EOCM2B_K1_HS,EOCM2A_K1_HS
 SG_ ARSFlrIO : 0|1@0+ (1,0) [0|1] ""  CGM_HS,EOCM2B_K1_HS,EOCM2A_K1_HS,FCM_HS,BCM_HS

BO_ 528 Brake_System_Autonomous_Info_HS: 5 EBCM_HS
 SG_ ABRS_BcupESCDatInpSt : 17|1@0+ (1,0) [0|1] ""  CGM_HS,EOCM2B_K1_HS,EOCM2A_K1_HS
 SG_ ABRS_ACCAutBkRqPrBsSt : 20|3@0+ (1,0) [0|7] ""  CGM_HS,EOCM2B_K1_HS,EOCM2A_K1_HS
 SG_ ABRS_CIBAutBkRqScBsSt : 23|3@0+ (1,0) [0|7] ""  CGM_HS,EOCM2B_K1_HS,EOCM2A_K1_HS
 SG_ AutBrkReqStatARC : 4|2@0+ (1,0) [0|3] ""  CGM_HS,EOCM2B_K1_HS,EOCM2A_K1_HS
 SG_ AutBrkReqStatProtVal : 39|7@0+ (1,0) [0|127] ""  CGM_HS,EOCM2B_K1_HS,EOCM2A_K1_HS
 SG_ BrkSysAutBrkReqRC : 2|2@0+ (1,0) [0|3] ""  CGM_HS,ICCM_B_HS,ICCM_OBD_HS,ICCM_HS
 SG_ BrkSysAutBrkReqPVal : 16|9@0+ (1,0) [0|511] ""  CGM_HS,ICCM_B_HS,ICCM_OBD_HS,ICCM_HS
 SG_ BSABR_TrlBrkRq : 0|8@0+ (0.392157,0) [0|100.000035] "%"  CGM_HS,ICCM_B_HS,ICCM_OBD_HS,ICCM_HS
 SG_ BSABR_TrlBrkCntlIntRq : 8|1@0+ (1,0) [0|1] ""  CGM_HS,ICCM_B_HS,ICCM_OBD_HS,ICCM_HS

BO_ 442 PTEI_Engine_Torque_Status_2: 8 ECM_HS
 SG_ CrksftTqMinImCapV : 5|1@0+ (1,0) [0|1] ""  CGM_HS,TCM_HS
 SG_ CrksftTqMinImCap : 27|12@0+ (0.5,-848) [-848|1199.5] "Nm"  CGM_HS,TCM_HS
 SG_ DrvIntndCrksftTrqRw : 3|12@0+ (0.5,-848) [-848|1199.5] "Nm"  CGM_HS,TCM_HS
 SG_ DrvIntndCrksftTrqMin : 23|12@0+ (0.5,-848) [-848|1199.5] "Nm"  CGM_HS,TCM_HS
 SG_ DrvIntndCrksftTrq : 47|12@0+ (0.5,-848) [-848|1199.5] "Nm"  CGM_HS,TCM_HS
 SG_ CrksftMaxTrqLmtV : 4|1@0+ (1,0) [0|1] ""  CGM_HS,TCM_HS
 SG_ CrksftMaxTrqLmt : 51|12@0+ (0.5,-848) [-848|1199.5] "Nm"  CGM_HS,TCM_HS

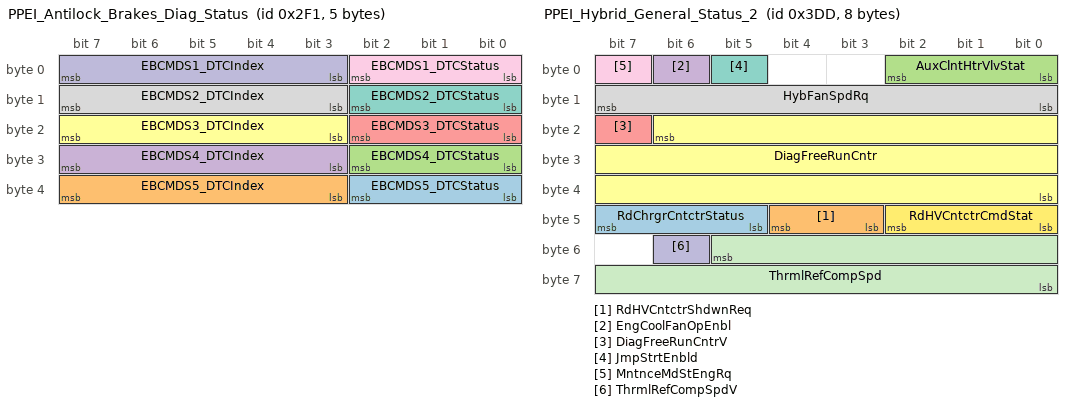
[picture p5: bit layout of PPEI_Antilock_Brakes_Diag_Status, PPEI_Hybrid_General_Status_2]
BO_ 753 PPEI_Antilock_Brakes_Diag_Status: 5 EBCM_HS
 SG_ EBCMDS5_DTCStatus : 34|3@0+ (1,0) [0|7] ""  CGM_HS,EOCM2B_K1_HS,EOCM2A_K1_HS,ECM_HS
 SG_ EBCMDS5_DTCIndex : 39|5@0+ (1,0) [0|31] ""  CGM_HS,EOCM2B_K1_HS,EOCM2A_K1_HS,ECM_HS
 SG_ EBCMDS4_DTCStatus : 26|3@0+ (1,0) [0|7] ""  CGM_HS,EOCM2B_K1_HS,EOCM2A_K1_HS,ECM_HS
 SG_ EBCMDS4_DTCIndex : 31|5@0+ (1,0) [0|31] ""  CGM_HS,EOCM2B_K1_HS,EOCM2A_K1_HS,ECM_HS
 SG_ EBCMDS3_DTCStatus : 18|3@0+ (1,0) [0|7] ""  CGM_HS,EOCM2B_K1_HS,EOCM2A_K1_HS,ECM_HS
 SG_ EBCMDS3_DTCIndex : 23|5@0+ (1,0) [0|31] ""  CGM_HS,EOCM2B_K1_HS,EOCM2A_K1_HS,ECM_HS
 SG_ EBCMDS2_DTCStatus : 10|3@0+ (1,0) [0|7] ""  CGM_HS,EOCM2B_K1_HS,EOCM2A_K1_HS,ECM_HS
 SG_ EBCMDS2_DTCIndex : 15|5@0+ (1,0) [0|31] ""  CGM_HS,EOCM2B_K1_HS,EOCM2A_K1_HS,ECM_HS
 SG_ EBCMDS1_DTCStatus : 2|3@0+ (1,0) [0|7] ""  CGM_HS,EOCM2B_K1_HS,EOCM2A_K1_HS,ECM_HS
 SG_ EBCMDS1_DTCIndex : 7|5@0+ (1,0) [0|31] ""  CGM_HS,EOCM2B_K1_HS,EOCM2A_K1_HS,ECM_HS

BO_ 989 PPEI_Hybrid_General_Status_2: 8 VICM_HS
 SG_ RdChrgrCntctrStatus : 47|3@0+ (1,0) [0|7] ""  CGM_HS,HCP_T_HS,HCP_HS
 SG_ RdHVCntctrShdwnReq : 44|2@0+ (1,0) [0|3] ""  CGM_HS,HCP_T_HS,HCP_HS,HCP_B_HS
 SG_ AuxClntHtrVlvStat : 2|3@0+ (1,0) [0|7] ""  CGM_HS,ECM_HS
 SG_ EngCoolFanOpEnbl : 6|1@0+ (1,0) [0|1] ""  CGM_HS,ECM_HS
 SG_ DiagFreeRunCntrV : 23|1@0+ (1,0) [0|1] ""  CGM_HS,ECM_HS
 SG_ DiagFreeRunCntr : 22|23@0+ (1,0) [0|8388607] "min"  CGM_HS,ECM_HS
 SG_ JmpStrtEnbld : 5|1@0+ (1,0) [0|1] ""  CGM_HS,HCP_B_HS
 SG_ HybFanSpdRq : 15|8@0+ (0.392157,0) [0|100.000035] "%"  CGM_HS,ECM_HS
 SG_ MntnceMdStEngRq : 7|1@0+ (1,0) [0|1] ""  CGM_HS,ECM_HS
 SG_ ThrmlRefCompSpdV : 54|1@0+ (1,0) [0|1] ""  CGM_HS,ECM_HS
 SG_ ThrmlRefCompSpd : 53|14@0+ (1,0) [0|16383] "rpm"  CGM_HS,ECM_HS
 SG_ RdHVCntctrCmdStat : 42|3@0+ (1,0) [0|7] ""  CGM_HS,HCP_T_HS,HCP_HS,HCP_B_HS

BO_ 550 Air_Cmpresor_Ctrl_Calib_Idnt_HS: 8 ACCM_HS
 SG_ ACCMCII_DtBtG : 63|8@0+ (1,0) [0|0] ""  CGM_HS,BSM_HS,VICM_HS
 SG_ ACCMCII_DtBtF : 55|8@0+ (1,0) [0|0] ""  CGM_HS,BSM_HS,VICM_HS
 SG_ ACCMCII_DtBtE : 47|8@0+ (1,0) [0|0] ""  CGM_HS,BSM_HS,VICM_HS
 SG_ ACCMCII_DtBtD : 39|8@0+ (1,0) [0|0] ""  CGM_HS,BSM_HS,VICM_HS
 SG_ ACCMCII_DtBtC : 31|8@0+ (1,0) [0|0] ""  CGM_HS,BSM_HS,VICM_HS
 SG_ ACCMCII_DtBtB : 23|8@0+ (1,0) [0|0] ""  CGM_HS,BSM_HS,VICM_HS
 SG_ ACCMCII_DtBtA : 15|8@0+ (1,0) [0|0] ""  CGM_HS,BSM_HS,VICM_HS
 SG_ ACCMCII_SeqNum : 1|2@0+ (1,0) [0|3] ""  CGM_HS,BSM_HS,VICM_HS
 SG_ ACCMCII_Index : 7|4@0+ (1,0) [0|15] ""  CGM_HS,BSM_HS,VICM_HS
 SG_ ACCMCII_DatStat : 3|2@0+ (1,0) [0|3] ""  CGM_HS,BSM_HS,VICM_HS

BO_ 988 PPEI_Powertrain_HVAC_PTC_Gen_Sta: 6 ECM_HS
 SG_ EGHRInhbtRqstd : 7|1@0+ (1,0) [0|1] ""  CGM_HS,BSM_HS
 SG_ AccPwrModMinCoolRq : 20|3@0+ (1,0) [0|7] ""  CGM_HS,BSM_HS,VICM_HS
 SG_ A6ERRAlrmTime : 31|24@0+ (1,0) [0|16777215] "min"  CGM_HS,BSM_HS,VICM_HS
 SG_ A6ERRAlrmReq : 17|2@0+ (1,0) [0|3] ""  CGM_HS,BSM_HS,VICM_HS
 SG_ EngMntncePrcntCpl : 15|8@0+ (0.392157,0) [0|100.000035] "%"  CGM_HS,VICM_HS
 SG_ MntnceMdDsplyRq : 4|4@0+ (1,0) [0|15] ""  CGM_HS,VICM_HS
 SG_ EngMntnceMdAct : 6|1@0+ (1,0) [0|1] ""  CGM_HS,VICM_HS
 SG_ HVPropChgrUnbl : 5|1@0+ (1,0) [0|1] ""  CGM_HS,HCP_T_HS,HCP_HS,BSM_HS,VICM_HS
 SG_ EngHtrValvBpasCmd : 0|1@0+ (1,0) [0|1] ""  CGM_HS,VICM_HS

BO_ 565 Performan_Mode_Cust_Setings_1_HS: 5 EBCM_HS
 SG_ PerfMdMainMenuType : 2|3@0+ (1,0) [0|7] ""  EOCM2B_K1_HS,CGM_HS,BCM_HS,EOCM2A_K1_HS
 SG_ PSPMCA_PsngStPrfMd6Avl : 24|1@0+ (1,0) [0|1] ""  EOCM2B_K1_HS,CGM_HS,BCM_HS,EOCM2A_K1_HS
 SG_ PSPMCA_PsngStPrfMd5Avl : 25|1@0+ (1,0) [0|1] ""  EOCM2B_K1_HS,CGM_HS,BCM_HS,EOCM2A_K1_HS
 SG_ PSPMCA_PsngStPrfMd4Avl : 26|1@0+ (1,0) [0|1] ""  EOCM2B_K1_HS,CGM_HS,BCM_HS,EOCM2A_K1_HS
 SG_ PSPMCA_PsngStPrfMd3Avl : 27|1@0+ (1,0) [0|1] ""  EOCM2B_K1_HS,CGM_HS,BCM_HS,EOCM2A_K1_HS
 SG_ PSPMCA_PsngStPrfMd2Avl : 28|1@0+ (1,0) [0|1] ""  EOCM2B_K1_HS,CGM_HS,BCM_HS,EOCM2A_K1_HS
 SG_ PSPMCA_PsngStPrfMd1Avl : 29|1@0+ (1,0) [0|1] ""  EOCM2B_K1_HS,CGM_HS,BCM_HS,EOCM2A_K1_HS
 SG_ DSPMCA_DrvStyPrfMd7Avl : 32|1@0+ (1,0) [0|1] ""  EOCM2B_K1_HS,CGM_HS,BCM_HS,EOCM2A_K1_HS
 SG_ DSPMCA_DrvStyPrfMd6Avl : 33|1@0+ (1,0) [0|1] ""  EOCM2B_K1_HS,CGM_HS,BCM_HS,EOCM2A_K1_HS
 SG_ DSPMCA_DrvStyPrfMd5Avl : 34|1@0+ (1,0) [0|1] ""  EOCM2B_K1_HS,CGM_HS,BCM_HS,EOCM2A_K1_HS
 SG_ DSPMCA_DrvStyPrfMd4Avl : 35|1@0+ (1,0) [0|1] ""  EOCM2B_K1_HS,CGM_HS,BCM_HS,EOCM2A_K1_HS
 SG_ DSPMCA_DrvStyPrfMd3Avl : 36|1@0+ (1,0) [0|1] ""  EOCM2B_K1_HS,CGM_HS,BCM_HS,EOCM2A_K1_HS
 SG_ DSPMCA_DrvStyPrfMd2Avl : 37|1@0+ (1,0) [0|1] ""  EOCM2B_K1_HS,CGM_HS,BCM_HS,EOCM2A_K1_HS
 SG_ DSPMCA_DrvStyPrfMd1Avl : 38|1@0+ (1,0) [0|1] ""  EOCM2B_K1_HS,CGM_HS,BCM_HS,EOCM2A_K1_HS
 SG_ DSPMCA_DrvrStPrfMd6Avl : 16|1@0+ (1,0) [0|1] ""  EOCM2B_K1_HS,CGM_HS,BCM_HS,EOCM2A_K1_HS
 SG_ DSPMCA_DrvrStPrfMd5Avl : 17|1@0+ (1,0) [0|1] ""  EOCM2B_K1_HS,CGM_HS,BCM_HS,EOCM2A_K1_HS
 SG_ DSPMCA_DrvrStPrfMd4Avl : 18|1@0+ (1,0) [0|1] ""  EOCM2B_K1_HS,CGM_HS,BCM_HS,EOCM2A_K1_HS
 SG_ DSPMCA_DrvrStPrfMd3Avl : 19|1@0+ (1,0) [0|1] ""  EOCM2B_K1_HS,CGM_HS,BCM_HS,EOCM2A_K1_HS
 SG_ DSPMCA_DrvrStPrfMd2Avl : 20|1@0+ (1,0) [0|1] ""  EOCM2B_K1_HS,CGM_HS,BCM_HS,EOCM2A_K1_HS
 SG_ DSPMCA_DrvrStPrfMd1Avl : 21|1@0+ (1,0) [0|1] ""  EOCM2B_K1_HS,CGM_HS,BCM_HS,EOCM2A_K1_HS
 SG_ ACCPMCA_ACCPrfMd6Avl : 8|1@0+ (1,0) [0|1] ""  EOCM2B_K1_HS,CGM_HS,BCM_HS,EOCM2A_K1_HS
 SG_ ACCPMCA_ACCPrfMd5Avl : 9|1@0+ (1,0) [0|1] ""  EOCM2B_K1_HS,CGM_HS,BCM_HS,EOCM2A_K1_HS
 SG_ ACCPMCA_ACCPrfMd4Avl : 10|1@0+ (1,0) [0|1] ""  EOCM2B_K1_HS,CGM_HS,BCM_HS,EOCM2A_K1_HS
 SG_ ACCPMCA_ACCPrfMd3Avl : 11|1@0+ (1,0) [0|1] ""  EOCM2B_K1_HS,CGM_HS,BCM_HS,EOCM2A_K1_HS
 SG_ ACCPMCA_ACCPrfMd2Avl : 12|1@0+ (1,0) [0|1] ""  EOCM2B_K1_HS,CGM_HS,BCM_HS,EOCM2A_K1_HS
 SG_ ACCPMCA_ACCPrfMd1Avl : 13|1@0+ (1,0) [0|1] ""  EOCM2B_K1_HS,CGM_HS,BCM_HS,EOCM2A_K1_HS

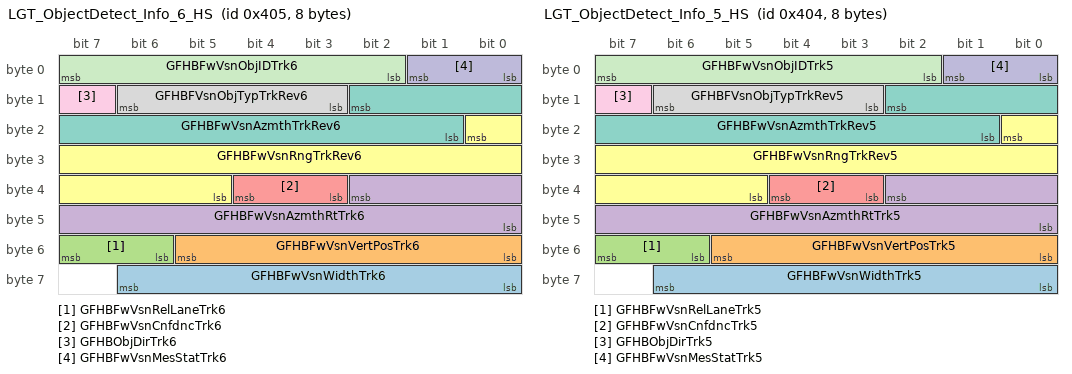
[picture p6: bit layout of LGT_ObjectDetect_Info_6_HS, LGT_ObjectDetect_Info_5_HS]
BO_ 1029 LGT_ObjectDetect_Info_6_HS: 8 EOCM_F_HS
 SG_ GFHBFwVsnWidthTrk6 : 62|7@0+ (0.1,0) [0|12.7] "deg"  CGM_HS,EOCM2B_K1_HS,AHL_AFL_HS
 SG_ GFHBFwVsnVertPosTrk6 : 53|6@0+ (0.25,-3) [-3|12.75] "deg"  CGM_HS,EOCM2B_K1_HS,AHL_AFL_HS
 SG_ GFHBFwVsnRelLaneTrk6 : 55|2@0+ (1,0) [0|3] ""  CGM_HS,EOCM2B_K1_HS,AHL_AFL_HS
 SG_ GFHBFwVsnAzmthRtTrk6 : 34|11@0- (0.125,0) [-128|127.875] "deg/s"  CGM_HS,EOCM2B_K1_HS,AHL_AFL_HS
 SG_ GFHBFwVsnCnfdncTrk6 : 36|2@0+ (1,0) [0|3] ""  CGM_HS,EOCM2B_K1_HS,AHL_AFL_HS
 SG_ GFHBFwVsnRngTrkRev6 : 16|12@0+ (0.2,0) [0|819] "m"  CGM_HS,EOCM2B_K1_HS,AHL_AFL_HS
 SG_ GFHBFwVsnAzmthTrkRev6 : 10|10@0- (0.05,0) [-25.6|25.55] "deg"  CGM_HS,EOCM2B_K1_HS,AHL_AFL_HS
 SG_ GFHBFVsnObjTypTrkRev6 : 14|4@0+ (1,0) [0|15] ""  CGM_HS,EOCM2B_K1_HS,AHL_AFL_HS
 SG_ GFHBObjDirTrk6 : 15|1@0+ (1,0) [0|1] ""  CGM_HS,EOCM2B_K1_HS,AHL_AFL_HS
 SG_ GFHBFwVsnMesStatTrk6 : 1|2@0+ (1,0) [0|3] ""  CGM_HS,EOCM2B_K1_HS,AHL_AFL_HS
 SG_ GFHBFwVsnObjIDTrk6 : 7|6@0+ (1,0) [0|63] ""  CGM_HS,EOCM2B_K1_HS,AHL_AFL_HS

BO_ 1028 LGT_ObjectDetect_Info_5_HS: 8 EOCM_F_HS
 SG_ GFHBFwVsnWidthTrk5 : 62|7@0+ (0.1,0) [0|12.7] "deg"  CGM_HS,EOCM2B_K1_HS,AHL_AFL_HS
 SG_ GFHBFwVsnVertPosTrk5 : 53|6@0+ (0.25,-3) [-3|12.75] "deg"  CGM_HS,EOCM2B_K1_HS,AHL_AFL_HS
 SG_ GFHBFwVsnRelLaneTrk5 : 55|2@0+ (1,0) [0|3] ""  CGM_HS,EOCM2B_K1_HS,AHL_AFL_HS
 SG_ GFHBFwVsnAzmthRtTrk5 : 34|11@0- (0.125,0) [-128|127.875] "deg/s"  CGM_HS,EOCM2B_K1_HS,AHL_AFL_HS
 SG_ GFHBFwVsnCnfdncTrk5 : 36|2@0+ (1,0) [0|3] ""  CGM_HS,EOCM2B_K1_HS,AHL_AFL_HS
 SG_ GFHBFwVsnRngTrkRev5 : 16|12@0+ (0.2,0) [0|819] "m"  CGM_HS,EOCM2B_K1_HS,AHL_AFL_HS
 SG_ GFHBFwVsnAzmthTrkRev5 : 10|10@0- (0.05,0) [-25.6|25.55] "deg"  CGM_HS,EOCM2B_K1_HS,AHL_AFL_HS
 SG_ GFHBFVsnObjTypTrkRev5 : 14|4@0+ (1,0) [0|15] ""  CGM_HS,EOCM2B_K1_HS,AHL_AFL_HS
 SG_ GFHBObjDirTrk5 : 15|1@0+ (1,0) [0|1] ""  CGM_HS,EOCM2B_K1_HS,AHL_AFL_HS
 SG_ GFHBFwVsnMesStatTrk5 : 1|2@0+ (1,0) [0|3] ""  CGM_HS,EOCM2B_K1_HS,AHL_AFL_HS
 SG_ GFHBFwVsnObjIDTrk5 : 7|6@0+ (1,0) [0|63] ""  CGM_HS,EOCM2B_K1_HS,AHL_AFL_HS

BO_ 500 PPEI_Drv_Pref_Mode_Switch_Status: 6 ECM_HS
 SG_ AutoVehMdSelctIntrStat : 46|2@0+ (1,0) [0|3] ""  CSM_HS,HMIM_HS,CGM_HS
 SG_ EnhDrvMdSwChUseAct : 40|1@0+ (1,0) [0|1] ""  CGM_HS,EBCM_OBD_HS,EBCM_HS
 SG_ EnhDrvSelMdSwStat : 42|2@0+ (1,0) [0|3] ""  CGM_HS,EBCM_OBD_HS,EBCM_HS
 SG_ DrvSelMd8Stat : 17|1@0+ (1,0) [0|1] ""  LVMPC_HS,CGM_HS,AHL_AFL_HS,EBCM_OBD_HS,EBCM_HS,RDCM_HS,SADS_HS,BCM_HS
 SG_ DrvSelMd8ReqDnd : 16|1@0+ (1,0) [0|1] ""  CGM_HS,RDCM_HS,BCM_HS
 SG_ DrvSelMd7Stat : 19|1@0+ (1,0) [0|1] ""  LVMPC_HS,CGM_HS,AHL_AFL_HS,RDCM_HS,EBCM_OBD_HS,EBCM_HS,SADS_HS,BCM_HS
 SG_ DrvSelMd7ReqDnd : 18|1@0+ (1,0) [0|1] ""  CGM_HS,RDCM_HS,BCM_HS
 SG_ DrvSelMd6Stat : 21|1@0+ (1,0) [0|1] ""  LVMPC_HS,CGM_HS,AHL_AFL_HS,RDCM_HS,SADS_HS,EBCM_OBD_HS,EBCM_HS,BCM_HS
 SG_ DrvSelMd6ReqDnd : 20|1@0+ (1,0) [0|1] ""  CGM_HS,RDCM_HS,BCM_HS
 SG_ DrvSelMd5Stat : 23|1@0+ (1,0) [0|1] ""  LVMPC_HS,CGM_HS,AHL_AFL_HS,RDCM_HS,SADS_HS,EBCM_OBD_HS,EBCM_HS,BCM_HS
 SG_ DrvSelMd5ReqDnd : 22|1@0+ (1,0) [0|1] ""  CGM_HS,RDCM_HS,BCM_HS
 SG_ DrvSelMd4Stat : 9|1@0+ (1,0) [0|1] ""  LVMPC_HS,CGM_HS,AHL_AFL_HS,RDCM_HS,SADS_HS,EBCM_OBD_HS,EBCM_HS,BCM_HS
 SG_ DrvSelMd4ReqDnd : 8|1@0+ (1,0) [0|1] ""  CGM_HS,RDCM_HS,BCM_HS
 SG_ DrvSelMd3Stat : 11|1@0+ (1,0) [0|1] ""  LVMPC_HS,CGM_HS,AHL_AFL_HS,RDCM_HS,SADS_HS,EBCM_OBD_HS,EBCM_HS,BCM_HS
 SG_ DrvSelMd3ReqDnd : 10|1@0+ (1,0) [0|1] ""  EBCM_OBD_HS,EBCM_HS,CGM_HS,RDCM_HS,BCM_HS
 SG_ DrvSelMd2Stat : 13|1@0+ (1,0) [0|1] ""  LVMPC_HS,CGM_HS,AHL_AFL_HS,RDCM_HS,SADS_HS,EBCM_OBD_HS,EBCM_HS,BCM_HS
 SG_ DrvSelMd2ReqDnd : 12|1@0+ (1,0) [0|1] ""  CGM_HS,RDCM_HS,BCM_HS
 SG_ DSMSS_DrvSelMd0Pn : 47|1@0+ (1,0) [0|1] ""  CGM_HS,EBCM_OBD_HS,EBCM_HS,RDCM_HS,BCM_HS
 SG_ DSMSS_DrvSelMd8Pn : 32|1@0+ (1,0) [0|1] ""  CGM_HS,EBCM_OBD_HS,EBCM_HS,RDCM_HS,BCM_HS
 SG_ DSMSS_DrvSelMd7Pn : 33|1@0+ (1,0) [0|1] ""  CGM_HS,EBCM_OBD_HS,EBCM_HS,RDCM_HS,BCM_HS
 SG_ DSMSS_DrvSelMd6Pn : 34|1@0+ (1,0) [0|1] ""  CGM_HS,EBCM_OBD_HS,EBCM_HS,RDCM_HS,BCM_HS
 SG_ DSMSS_DrvSelMd5Pn : 35|1@0+ (1,0) [0|1] ""  CGM_HS,EBCM_OBD_HS,EBCM_HS,RDCM_HS,BCM_HS
 SG_ DSMSS_DrvSelMd4Pn : 36|1@0+ (1,0) [0|1] ""  CGM_HS,EBCM_OBD_HS,EBCM_HS,RDCM_HS,BCM_HS
 SG_ DSMSS_DrvSelMd3Pn : 37|1@0+ (1,0) [0|1] ""  CGM_HS,EBCM_OBD_HS,EBCM_HS,RDCM_HS,BCM_HS
 SG_ DSMSS_DrvSelMd2Pn : 38|1@0+ (1,0) [0|1] ""  CGM_HS,EBCM_OBD_HS,EBCM_HS,RDCM_HS,BCM_HS
 SG_ DSMSS_DrvSelMd1Pn : 39|1@0+ (1,0) [0|1] ""  CGM_HS,EBCM_OBD_HS,EBCM_HS,RDCM_HS,BCM_HS
 SG_ DSMSS_DrvSelMd8Un : 24|1@0+ (1,0) [0|1] ""  CGM_HS,EBCM_OBD_HS,EBCM_HS,RDCM_HS,BCM_HS
 SG_ DSMSS_DrvSelMd7Un : 25|1@0+ (1,0) [0|1] ""  CGM_HS,EBCM_OBD_HS,EBCM_HS,RDCM_HS,BCM_HS
 SG_ DSMSS_DrvSelMd6Un : 26|1@0+ (1,0) [0|1] ""  CGM_HS,EBCM_OBD_HS,EBCM_HS,RDCM_HS,BCM_HS
 SG_ DSMSS_DrvSelMd5Un : 27|1@0+ (1,0) [0|1] ""  CGM_HS,EBCM_OBD_HS,EBCM_HS,RDCM_HS,BCM_HS
 SG_ DSMSS_DrvSelMd4Un : 28|1@0+ (1,0) [0|1] ""  CGM_HS,EBCM_OBD_HS,EBCM_HS,RDCM_HS,BCM_HS
 SG_ DSMSS_DrvSelMd3Un : 29|1@0+ (1,0) [0|1] ""  CGM_HS,EBCM_OBD_HS,EBCM_HS,RDCM_HS,BCM_HS
 SG_ DSMSS_DrvSelMd2Un : 30|1@0+ (1,0) [0|1] ""  CGM_HS,EBCM_OBD_HS,EBCM_HS,RDCM_HS,BCM_HS
 SG_ DSMSS_DrvSelMd1Un : 31|1@0+ (1,0) [0|1] ""  CGM_HS,EBCM_OBD_HS,EBCM_HS,RDCM_HS,BCM_HS
 SG_ DrvSelMd1ReqDnd : 14|1@0+ (1,0) [0|1] ""  CGM_HS,RDCM_HS,VICM_HS,BCM_HS
 SG_ DrvSelMd1Stat : 15|1@0+ (1,0) [0|1] ""  LVMPC_HS,CGM_HS,AHL_AFL_HS,RDCM_HS,SADS_HS,EBCM_OBD_HS,EBCM_HS,BCM_HS

BO_ 1417 ETEI_Engine_Torque_Capability: 8 ECM_HS
 SG_ PrplsnTrqRelCap : 63|8@0+ (0.5,0) [0|127.5] "%"  CGM_HS,TCM_HS
 SG_ ETC_MinTorq : 47|12@0+ (0.5,-848) [-848|1199.5] "Nm"  CGM_HS,HCP_B_HS,HCP_T_HS,TCM_HS,HCP_HS,BCP_HS
 SG_ ETC_MinRunTorq : 27|12@0+ (0.5,-848) [-848|1199.5] "Nm"  CGM_HS,HCP_B_HS,HCP_T_HS,TCM_HS,HCP_HS,BCP_HS
 SG_ ETC_MaxTorq : 23|12@0+ (0.5,-848) [-848|1199.5] "Nm"  CGM_HS,HCP_B_HS,HCP_T_HS,TCM_HS,HCP_HS,BCP_HS
 SG_ ETC_RefEngSpd : 15|8@0+ (32,0) [0|8160] "rpm"  CGM_HS,HCP_B_HS,HCP_T_HS,TCM_HS,HCP_HS,BCP_HS
 SG_ ETC_UnsdRsrvd : 2|3@0+ (1,0) [0|7] ""  CGM_HS,HCP_B_HS,HCP_T_HS,TCM_HS,HCP_HS,BCP_HS
 SG_ ETC_FrmCntr : 6|4@0+ (1,0) [0|15] ""  CGM_HS,HCP_B_HS,HCP_T_HS,TCM_HS,HCP_HS,BCP_HS
 SG_ ETC_EngOpMd : 7|1@0+ (1,0) [0|1] ""  CGM_HS,HCP_B_HS,HCP_T_HS,TCM_HS,HCP_HS,BCP_HS

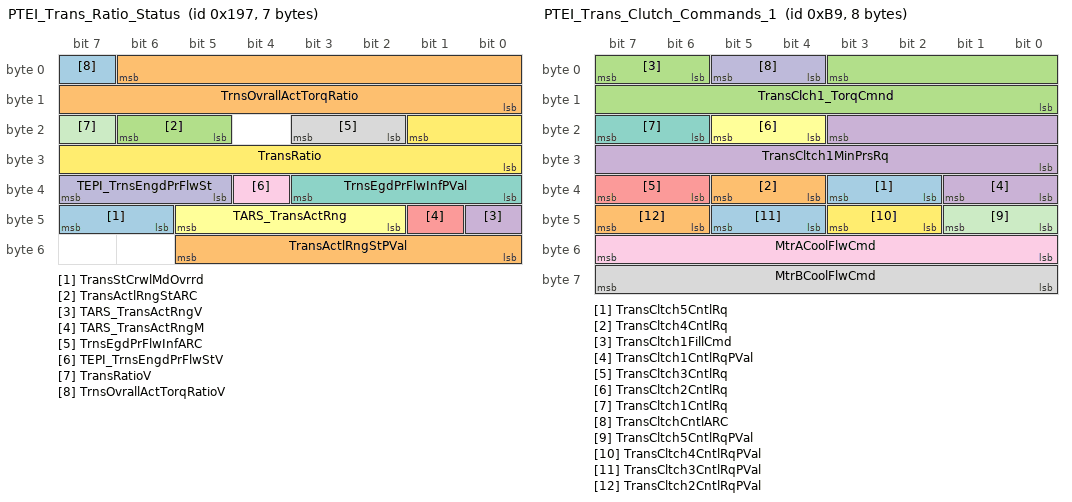
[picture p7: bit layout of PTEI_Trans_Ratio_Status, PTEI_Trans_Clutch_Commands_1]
BO_ 407 PTEI_Trans_Ratio_Status: 7 TCM_HS
 SG_ TransStCrwlMdOvrrd : 47|2@0+ (1,0) [0|3] ""  CGM_HS,ECM_HS
 SG_ TransActlRngStPVal : 53|6@0+ (1,0) [0|63] ""  CGM_HS,ECM_HS,ICCM_HS,HCP_B_HS,BSM_HS,VICM_HS
 SG_ TransActlRngStARC : 22|2@0+ (1,0) [0|3] ""  HCP_B_HS,CGM_HS,ECM_HS,ICCM_HS,BSM_HS,VICM_HS
 SG_ TARS_TransActRngV : 40|1@0+ (1,0) [0|1] ""  HCP_B_HS,CGM_HS,ECM_HS,ICCM_HS,BCM_HS,BSM_HS,VICM_HS
 SG_ TARS_TransActRngM : 41|1@0+ (1,0) [0|1] ""  HCP_B_HS,CGM_HS,ECM_HS,ICCM_HS,BCM_HS,BSM_HS,VICM_HS
 SG_ TARS_TransActRng : 45|4@0+ (1,0) [0|15] ""  HCP_B_HS,CGM_HS,ECM_HS,ICCM_HS,BCM_HS,BSM_HS,VICM_HS
 SG_ TrnsEgdPrFlwInfPVal : 35|4@0+ (1,0) [0|15] ""  CGM_HS,ECM_HS,ICCM_HS
 SG_ TrnsEgdPrFlwInfARC : 19|2@0+ (1,0) [0|3] ""  CGM_HS,ECM_HS,ICCM_HS
 SG_ TEPI_TrnsEngdPrFlwStV : 36|1@0+ (1,0) [0|1] ""  CGM_HS,ECM_HS,ICCM_HS
 SG_ TEPI_TrnsEngdPrFlwSt : 39|3@0+ (1,0) [0|7] ""  CGM_HS,ECM_HS,ICCM_HS
 SG_ TransRatioV : 23|1@0+ (1,0) [0|1] ""  CGM_HS,ECM_HS
 SG_ TransRatio : 17|10@0+ (0.03125,0) [0|31.96875] ""  CGM_HS,ECM_HS
 SG_ TrnsOvrallActTorqRatioV : 7|1@0+ (1,0) [0|1] ""  CGM_HS,ECM_HS
 SG_ TrnsOvrallActTorqRatio : 6|15@0- (0.00390625,0) [-64|63.99609375] ""  CGM_HS,ECM_HS

BO_ 189 PTEI_Trans_Clutch_Status_4: 7 TCM_HS
 SG_ TransOilPmpOfRqd : 6|1@0+ (1,0) [0|1] ""  CGM_HS,HCP_HS
 SG_ HybDisengCruzCmnd : 5|1@0+ (1,0) [0|1] ""  FCM_HS,CGM_HS,EOCM_F_HS,ACC_HS,ECM_HS
 SG_ TransVehTopSpdLim : 55|8@0+ (2,0) [0|510] "km / h"  CGM_HS,ECM_HS
 SG_ TransMinVoltReq : 47|8@0+ (0.07843,0) [0|19.99965] "volts"  CGM_HS,ECM_HS
 SG_ TrnsRtoCntlSysFlt : 4|1@0+ (1,0) [0|1] ""  CGM_HS,ECM_HS
 SG_ TransMnPressEstmd : 27|12@0+ (0.5,0) [0|2047.5] "kPa"  CGM_HS,HCP_HS
 SG_ TrnsInpMinSpdRq : 31|4@0+ (1,0) [0|15] ""  CGM_HS,HCP_HS
 SG_ TrnsHydPrsDsrd : 3|12@0+ (0.5,0) [0|2047.5] "kPa"  CGM_HS,HCP_HS
 SG_ TransAuxPumpSpdDsrd : 23|8@0+ (0.392157,0) [0|100.000035] "%"  CGM_HS,HCP_HS

BO_ 187 PTEI_Trans_Clutch_Commands_3: 8 HCP_HS
 SG_ TransClch5_TorqCmnd : 35|12@0+ (0.5,-5) [-5|2042.5] "Nm"  CGM_HS,TCM_HS
 SG_ TransCltch5MinPrsRq : 51|12@0+ (0.5,0) [0|2047.5] "kPa"  CGM_HS,TCM_HS
 SG_ TransCltch5FillCmd : 39|2@0+ (1,0) [0|3] ""  CGM_HS,TCM_HS
 SG_ TransClch4_TorqCmnd : 3|12@0+ (0.5,-5) [-5|2042.5] "Nm"  CGM_HS,TCM_HS
 SG_ TransCltch4MinPrsRq : 19|12@0+ (0.5,0) [0|2047.5] "kPa"  CGM_HS,TCM_HS
 SG_ TransCltch4FillCmd : 7|2@0+ (1,0) [0|3] ""  CGM_HS,TCM_HS

BO_ 185 PTEI_Trans_Clutch_Commands_1: 8 HCP_HS
 SG_ TransCltch5CntlRq : 35|2@0+ (1,0) [0|3] ""  CGM_HS,TCM_HS
 SG_ TransCltch4CntlRq : 37|2@0+ (1,0) [0|3] ""  CGM_HS,TCM_HS
 SG_ TransCltch1FillCmd : 7|2@0+ (1,0) [0|3] ""  CGM_HS,TCM_HS
 SG_ TransCltch1CntlRqPVal : 33|2@0+ (1,0) [0|3] ""  CGM_HS,TCM_HS
 SG_ TransCltch3CntlRq : 39|2@0+ (1,0) [0|3] ""  CGM_HS,TCM_HS
 SG_ TransCltch2CntlRq : 21|2@0+ (1,0) [0|3] ""  CGM_HS,TCM_HS
 SG_ TransCltch1CntlRq : 23|2@0+ (1,0) [0|3] ""  CGM_HS,TCM_HS
 SG_ MtrBCoolFlwCmd : 63|8@0+ (0.05,0) [0|12.75] "l/min"  CGM_HS,TCM_HS
 SG_ MtrACoolFlwCmd : 55|8@0+ (0.05,0) [0|12.75] "l/min"  CGM_HS,TCM_HS
 SG_ TransCltchCntlARC : 5|2@0+ (1,0) [0|3] ""  CGM_HS,TCM_HS
 SG_ TransCltch5CntlRqPVal : 41|2@0+ (1,0) [0|3] ""  CGM_HS,TCM_HS
 SG_ TransCltch4CntlRqPVal : 43|2@0+ (1,0) [0|3] ""  CGM_HS,TCM_HS
 SG_ TransCltch3CntlRqPVal : 45|2@0+ (1,0) [0|3] ""  CGM_HS,TCM_HS
 SG_ TransCltch2CntlRqPVal : 47|2@0+ (1,0) [0|3] ""  CGM_HS,TCM_HS
 SG_ TransClch1_TorqCmnd : 3|12@0+ (0.5,-5) [-5|2042.5] "Nm"  CGM_HS,TCM_HS
 SG_ TransCltch1MinPrsRq : 19|12@0+ (0.5,0) [0|2047.5] "kPa"  CGM_HS,TCM_HS

BO_ 186 PTEI_Trans_Clutch_Commands_2: 8 HCP_HS
 SG_ TransClch3_TorqCmnd : 35|12@0+ (0.5,-5) [-5|2042.5] "Nm"  CGM_HS,TCM_HS
 SG_ TransCltch3MinPrsRq : 51|12@0+ (0.5,0) [0|2047.5] "kPa"  CGM_HS,TCM_HS
 SG_ TransCltch3FillCmd : 39|2@0+ (1,0) [0|3] ""  CGM_HS,TCM_HS
 SG_ TransClch2_TorqCmnd : 3|12@0+ (0.5,-5) [-5|2042.5] "Nm"  CGM_HS,TCM_HS
 SG_ TransCltch2MinPrsRq : 19|12@0+ (0.5,0) [0|2047.5] "kPa"  CGM_HS,TCM_HS
 SG_ TransCltch2FillCmd : 7|2@0+ (1,0) [0|3] ""  CGM_HS,TCM_HS
 SG_ TransAuxPmpPresDetcd : 5|1@0+ (1,0) [0|1] ""  CGM_HS,TCM_HS

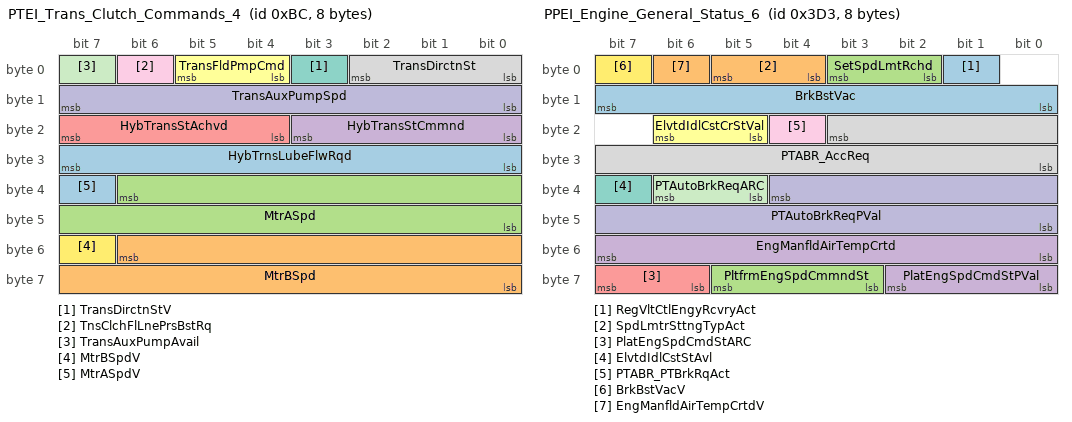
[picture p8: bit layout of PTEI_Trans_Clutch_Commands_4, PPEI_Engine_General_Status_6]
BO_ 188 PTEI_Trans_Clutch_Commands_4: 8 HCP_HS
 SG_ HybTrnsLubeFlwRqd : 31|8@0+ (0.0625,0) [0|15.9375] "l/min"  CGM_HS,TCM_HS
 SG_ MtrBSpd : 54|15@0- (1,0) [-16384|16383] "rpm"  CGM_HS,TCP_HS,ONSTAR_HS,TCM_HS
 SG_ MtrASpd : 38|15@0- (1,0) [-16384|16383] "rpm"  CGM_HS,TCP_HS,ONSTAR_HS,TCM_HS
 SG_ HybTransStCmmnd : 19|4@0+ (1,0) [0|15] ""  CGM_HS,TCM_HS
 SG_ HybTransStAchvd : 23|4@0+ (1,0) [0|15] ""  CGM_HS,TCM_HS
 SG_ TransFldPmpCmd : 5|2@0+ (1,0) [0|3] ""  CGM_HS,TCM_HS
 SG_ TransDirctnStV : 3|1@0+ (1,0) [0|1] ""  CGM_HS,TCM_HS,ECM_HS
 SG_ TransDirctnSt : 2|3@0+ (1,0) [0|7] ""  CGM_HS,TCM_HS,ECM_HS
 SG_ TnsClchFlLnePrsBstRq : 6|1@0+ (1,0) [0|1] ""  CGM_HS,TCM_HS
 SG_ TransAuxPumpSpd : 15|8@0+ (0.392157,0) [0|100.000035] "%"  CGM_HS,TCM_HS
 SG_ TransAuxPumpAvail : 7|1@0+ (1,0) [0|1] ""  CGM_HS,TCM_HS
 SG_ MtrBSpdV : 55|1@0+ (1,0) [0|1] ""  CGM_HS,TCP_HS,ONSTAR_HS,TCM_HS
 SG_ MtrASpdV : 39|1@0+ (1,0) [0|1] ""  CGM_HS,TCP_HS,ONSTAR_HS,TCM_HS

BO_ 170 PTEI_Axle_Torque_Command: 8 ECM_HS
 SG_ EngCommFlrRedPwrCm : 7|1@0+ (1,0) [0|1] ""  CGM_HS,HCP_T_HS,HCP_HS
 SG_ CmndAxlTrqARC : 34|2@0+ (1,0) [0|3] ""  CGM_HS,HCP_B_HS,HCP_T_HS,HCP_HS,EBCM_OBD_HS,EBCM_HS
 SG_ CmndAxlTrqRespTyp : 39|2@0+ (1,0) [0|3] ""  CGM_HS,HCP_T_HS,HCP_HS
 SG_ CmndAxlTrqImm : 6|15@0+ (2,-22534) [-22534|43000] "Nm"  CGM_HS,HCP_T_HS,HCP_HS
 SG_ AccPos : 63|8@0+ (0.392157,0) [0|100.000035] "%"  HCP_B_HS,HCP_T_HS,HCP_HS,TCM_HS
 SG_ CmndAxlTrqPredct : 22|15@0+ (2,-22534) [-22534|43000] "Nm"  CGM_HS,HCP_B_HS,HCP_T_HS,EBCM_OBD_HS,EBCM_HS,HCP_HS
 SG_ CmndAxlTrqPredctProtVal : 46|15@0+ (1,0) [0|32767] ""  CGM_HS,HCP_B_HS,HCP_T_HS,EBCM_OBD_HS,EBCM_HS,HCP_HS

BO_ 1221 PPEI_Platform_Eng_Cntrl_Req_2: 5 BCM_HS
 SG_ CCClntCrcFlwRtReqVDA : 1|1@0+ (1,0) [0|1] ""  CGM_HS,ECM_HS
 SG_ PTExPrtclFltManRgnRqd : 0|1@0+ (1,0) [0|1] ""  CGM_HS,ECM_HS
 SG_ SpdLmtVsnFsdSpdUnt : 39|1@0+ (1,0) [0|1] ""  EOCM_F_HS,CGM_HS,ACC_HS,ECM_HS
 SG_ SpdLmtVnFsSpdNwDet : 37|1@0+ (1,0) [0|1] ""  EOCM_F_HS,CGM_HS,ACC_HS,ECM_HS
 SG_ SpdLmtVsnFsdSpdM : 38|1@0+ (1,0) [0|1] ""  EOCM_F_HS,CGM_HS,ACC_HS,ECM_HS
 SG_ SpdLmtVsnFsdSpd : 31|8@0+ (1,0) [0|255] ""  EOCM_F_HS,CGM_HS,ACC_HS,ECM_HS
 SG_ CCClntCrcFlwRtReq : 23|8@0+ (0.392157,0) [0|100.000035] "%"  CGM_HS,ECM_HS

BO_ 1243 PPEI_Chassis_Sys_General_Status: 3 ICCM_HS
 SG_ CSERDTC_CdNum : 11|12@0+ (1,0) [0|4095] ""  CGM_HS,ECM_HS
 SG_ CSERDTC_SysDes : 15|4@0+ (1,0) [0|15] ""  CGM_HS,ECM_HS
 SG_ ChsSysEmmRelMalfAct : 7|1@0+ (1,0) [0|1] ""  CGM_HS,ECM_HS

BO_ 979 PPEI_Engine_General_Status_6: 8 ECM_HS
 SG_ RegVltCtlEngyRcvryAct : 1|1@0+ (1,0) [0|1] ""  CGM_HS,BCM_HS
 SG_ SpdLmtrSttngTypAct : 5|2@0+ (1,0) [0|3] ""  CGM_HS,BCM_HS
 SG_ SetSpdLmtRchd : 3|2@0+ (1,0) [0|3] ""  CGM_HS,BCM_HS
 SG_ PlatEngSpdCmdStPVal : 58|3@0+ (1,0) [0|7] ""  CGM_HS,PTO_HS
 SG_ PlatEngSpdCmdStARC : 63|2@0+ (1,0) [0|3] ""  CGM_HS,PTO_HS
 SG_ ElvtdIdlCstCrStVal : 22|2@0+ (1,0) [0|3] ""  CGM_HS,BCM_HS
 SG_ ElvtdIdlCstStAvl : 39|1@0+ (1,0) [0|1] ""  CGM_HS,BCM_HS
 SG_ PTABR_AccReq : 19|12@0- (0.01,0) [-20.48|20.47] "m/s^2"  CGM_HS,EBCM_OBD_HS,EBCM_HS
 SG_ PTABR_PTBrkRqAct : 20|1@0+ (1,0) [0|1] ""  CGM_HS,EBCM_OBD_HS,EBCM_HS
 SG_ PTAutoBrkReqPVal : 36|13@0+ (1,0) [0|8191] ""  CGM_HS,EBCM_OBD_HS,EBCM_HS
 SG_ PTAutoBrkReqARC : 38|2@0+ (1,0) [0|3] ""  CGM_HS,EBCM_OBD_HS,EBCM_HS
 SG_ BrkBstVacV : 7|1@0+ (1,0) [0|1] ""  CGM_HS,EBCM_OBD_HS,EBCM_HS
 SG_ BrkBstVac : 15|8@0+ (0.5,0) [0|127.5] "kPa"  CGM_HS,EBCM_OBD_HS,EBCM_HS
 SG_ EngManfldAirTempCrtdV : 6|1@0+ (1,0) [0|1] ""  CGM_HS,BCM_HS
 SG_ PltfrmEngSpdCmmndSt : 61|3@0+ (1,0) [0|7] ""  CGM_HS,PTO_HS
 SG_ EngManfldAirTempCrtd : 55|8@0+ (1,-40) [-40|215] "deg C"  CGM_HS,BCM_HS

BO_ 546 Thrml_Ref_Compressor_Status_HS: 7 ACCM_HS
 SG_ ThrmlRefCmpIGBTTmp : 55|8@0+ (1,-40) [-40|215] "deg C"  CGM_HS,BSM_HS,VICM_HS
 SG_ CmpSnsrDataARC : 23|2@0+ (1,0) [0|3] "N/A"  CGM_HS,BSM_HS,VICM_HS
 SG_ ThrmlRefCmpCPUHtSkTmp : 47|8@0+ (1,-40) [-40|215] "deg C"  CGM_HS,BSM_HS,VICM_HS
 SG_ ThrmlRefCmpHVInHRsln : 15|8@0+ (2.5,0) [0|637.5] "V"  CGM_HS,BSM_HS,VICM_HS
 SG_ ThrmlRfCmprElctrCrnt : 39|8@0+ (0.2,0) [0|51] "A"  CGM_HS,BSM_HS,VICM_HS
 SG_ ThrmlRefCompSpdFdbck : 21|14@0+ (1,0) [0|16383] "rpm"  BCM_HS,CGM_HS,BSM_HS,VICM_HS
 SG_ ThrmlRefCompStatFdbck : 6|4@0+ (1,0) [0|15] " "  BCM_HS,CGM_HS,BSM_HS,VICM_HS

BO_ 530 Veh_Theft_Notify_Reset_Req_HS: 1 VLBS_HS
 SG_ RstVTDTmprDtctd : 0|1@0+ (1,0) [0|1] ""  BCM_HS
 SG_ RstIllDrIdDevDtctd : 1|1@0+ (1,0) [0|1] ""  BCM_HS
 SG_ RstDrIdDevLrnd : 2|1@0+ (1,0) [0|1] ""  BCM_HS

BO_ 1239 PPEI_IBS_Battery_Status_2: 5 BCM_HS
 SG_ IBSBatSOC : 39|8@0+ (0.392157,0) [0|100.000035] "%"  CGM_HS,EOCM2B_K1_HS,EOCM2A_K1_HS,ECM_HS
 SG_ BattTemp : 15|8@0+ (1,-40) [-40|215] "deg C"  CGM_HS,EOCM2B_K1_HS,EOCM2A_K1_HS,ECM_HS
 SG_ BatSOH : 31|8@0+ (0.392157,0) [0|100.000035] "%"  CGM_HS,EOCM2B_K1_HS,EOCM2A_K1_HS,ECM_HS
 SG_ BatSOFVolt : 23|8@0+ (0.05,0) [0|12.75] "volts"  CGM_HS,EOCM2B_K1_HS,EOCM2A_K1_HS,ECM_HS
 SG_ BattSOXStat : 0|1@0+ (1,0) [0|1] ""  CGM_HS,EOCM2B_K1_HS,EOCM2A_K1_HS,ECM_HS
 SG_ BattTempV : 1|1@0+ (1,0) [0|1] ""  CGM_HS,EOCM2B_K1_HS,EOCM2A_K1_HS,ECM_HS

BO_ 1610 USDT_Resp_From_SAS_HS: 8 SAS_HS
 SG_ DgnInf : 7|64@0+ (1,0) [0|1.8446744074e+19] ""  HMIM_HS,CSM_HS,CGM_HS,TCP_HS,ONSTAR_HS,TestTool_HS

BO_ 1022 PPEI_Chassis_Command_1: 1 ICCM_HS
 SG_ PTRelReqdOnPVal : 2|2@0+ (1,0) [0|3] ""  CGM_HS,ECM_HS
 SG_ PTRelReqdOnARC : 4|2@0+ (1,0) [0|3] ""  CGM_HS,ECM_HS
 SG_ PTRelReqdOn : 0|1@0+ (1,0) [0|1] ""  CGM_HS,ECM_HS

BO_ 967 PPEI_Engine_General_Status_7: 4 ECM_HS
 SG_ PTRlyStatProtVal : 19|12@0+ (1,0) [0|4095] ""  HCP_B_HS,CGM_HS,ICCM_HS
 SG_ PTRlyStatARC : 5|2@0+ (1,0) [0|3] ""  HCP_B_HS,CGM_HS,ICCM_HS
 SG_ PRS_PTRlyFdbkCktVlt : 15|8@0+ (0.1,0) [0|25.5] "V"  HCP_B_HS,CGM_HS,ICCM_HS
 SG_ PRS_PTRlyFdbkCtVtNtIR : 0|1@0+ (1,0) [0|1] ""  HCP_B_HS,CGM_HS,ICCM_HS
 SG_ PRS_PTRlyFdbkCktFAct : 1|1@0+ (1,0) [0|1] ""  HCP_B_HS,CGM_HS,ICCM_HS
 SG_ PRS_PTRlyCntrlCktFAct : 2|1@0+ (1,0) [0|1] ""  HCP_B_HS,CGM_HS,ICCM_HS
 SG_ PRS_PTRlyCmdSt : 3|1@0+ (1,0) [0|1] ""  HCP_B_HS,CGM_HS,ICCM_HS

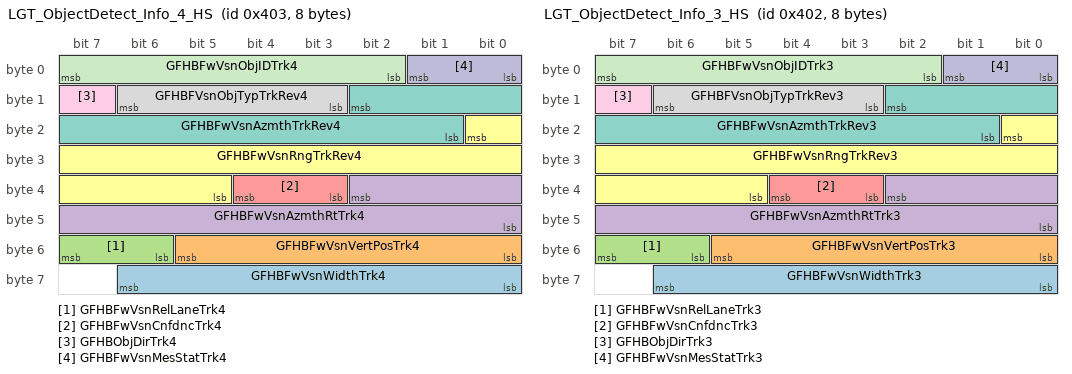
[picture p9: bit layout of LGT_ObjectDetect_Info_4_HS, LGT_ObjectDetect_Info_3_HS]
BO_ 1027 LGT_ObjectDetect_Info_4_HS: 8 EOCM_F_HS
 SG_ GFHBFwVsnWidthTrk4 : 62|7@0+ (0.1,0) [0|12.7] "deg"  CGM_HS,EOCM2B_K1_HS,AHL_AFL_HS
 SG_ GFHBFwVsnVertPosTrk4 : 53|6@0+ (0.25,-3) [-3|12.75] "deg"  CGM_HS,EOCM2B_K1_HS,AHL_AFL_HS
 SG_ GFHBFwVsnRelLaneTrk4 : 55|2@0+ (1,0) [0|3] ""  CGM_HS,EOCM2B_K1_HS,AHL_AFL_HS
 SG_ GFHBFwVsnAzmthRtTrk4 : 34|11@0- (0.125,0) [-128|127.875] "deg/s"  CGM_HS,EOCM2B_K1_HS,AHL_AFL_HS
 SG_ GFHBFwVsnCnfdncTrk4 : 36|2@0+ (1,0) [0|3] ""  CGM_HS,EOCM2B_K1_HS,AHL_AFL_HS
 SG_ GFHBFwVsnRngTrkRev4 : 16|12@0+ (0.2,0) [0|819] "m"  CGM_HS,EOCM2B_K1_HS,AHL_AFL_HS
 SG_ GFHBFwVsnAzmthTrkRev4 : 10|10@0- (0.05,0) [-25.6|25.55] "deg"  CGM_HS,EOCM2B_K1_HS,AHL_AFL_HS
 SG_ GFHBFVsnObjTypTrkRev4 : 14|4@0+ (1,0) [0|15] ""  CGM_HS,EOCM2B_K1_HS,AHL_AFL_HS
 SG_ GFHBObjDirTrk4 : 15|1@0+ (1,0) [0|1] ""  CGM_HS,EOCM2B_K1_HS,AHL_AFL_HS
 SG_ GFHBFwVsnMesStatTrk4 : 1|2@0+ (1,0) [0|3] ""  CGM_HS,EOCM2B_K1_HS,AHL_AFL_HS
 SG_ GFHBFwVsnObjIDTrk4 : 7|6@0+ (1,0) [0|63] ""  CGM_HS,EOCM2B_K1_HS,AHL_AFL_HS

BO_ 1026 LGT_ObjectDetect_Info_3_HS: 8 EOCM_F_HS
 SG_ GFHBFwVsnWidthTrk3 : 62|7@0+ (0.1,0) [0|12.7] "deg"  CGM_HS,EOCM2B_K1_HS,AHL_AFL_HS
 SG_ GFHBFwVsnVertPosTrk3 : 53|6@0+ (0.25,-3) [-3|12.75] "deg"  CGM_HS,EOCM2B_K1_HS,AHL_AFL_HS
 SG_ GFHBFwVsnRelLaneTrk3 : 55|2@0+ (1,0) [0|3] ""  CGM_HS,EOCM2B_K1_HS,AHL_AFL_HS
 SG_ GFHBFwVsnAzmthRtTrk3 : 34|11@0- (0.125,0) [-128|127.875] "deg/s"  CGM_HS,EOCM2B_K1_HS,AHL_AFL_HS
 SG_ GFHBFwVsnCnfdncTrk3 : 36|2@0+ (1,0) [0|3] ""  CGM_HS,EOCM2B_K1_HS,AHL_AFL_HS
 SG_ GFHBFwVsnRngTrkRev3 : 16|12@0+ (0.2,0) [0|819] "m"  CGM_HS,EOCM2B_K1_HS,AHL_AFL_HS
 SG_ GFHBFwVsnAzmthTrkRev3 : 10|10@0- (0.05,0) [-25.6|25.55] "deg"  CGM_HS,EOCM2B_K1_HS,AHL_AFL_HS
 SG_ GFHBFVsnObjTypTrkRev3 : 14|4@0+ (1,0) [0|15] ""  CGM_HS,EOCM2B_K1_HS,AHL_AFL_HS
 SG_ GFHBObjDirTrk3 : 15|1@0+ (1,0) [0|1] ""  CGM_HS,EOCM2B_K1_HS,AHL_AFL_HS
 SG_ GFHBFwVsnMesStatTrk3 : 1|2@0+ (1,0) [0|3] ""  CGM_HS,EOCM2B_K1_HS,AHL_AFL_HS
 SG_ GFHBFwVsnObjIDTrk3 : 7|6@0+ (1,0) [0|63] ""  CGM_HS,EOCM2B_K1_HS,AHL_AFL_HS

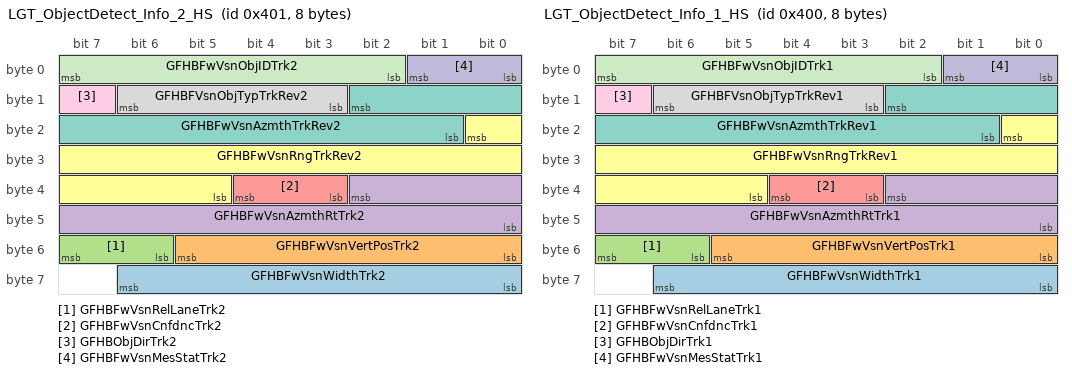
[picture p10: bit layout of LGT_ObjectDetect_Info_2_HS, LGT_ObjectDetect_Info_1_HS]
BO_ 1025 LGT_ObjectDetect_Info_2_HS: 8 EOCM_F_HS
 SG_ GFHBFwVsnWidthTrk2 : 62|7@0+ (0.1,0) [0|12.7] "deg"  CGM_HS,EOCM2B_K1_HS,AHL_AFL_HS
 SG_ GFHBFwVsnVertPosTrk2 : 53|6@0+ (0.25,-3) [-3|12.75] "deg"  CGM_HS,EOCM2B_K1_HS,AHL_AFL_HS
 SG_ GFHBFwVsnRelLaneTrk2 : 55|2@0+ (1,0) [0|3] ""  CGM_HS,EOCM2B_K1_HS,AHL_AFL_HS
 SG_ GFHBFwVsnAzmthRtTrk2 : 34|11@0- (0.125,0) [-128|127.875] "deg/s"  CGM_HS,EOCM2B_K1_HS,AHL_AFL_HS
 SG_ GFHBFwVsnCnfdncTrk2 : 36|2@0+ (1,0) [0|3] ""  CGM_HS,EOCM2B_K1_HS,AHL_AFL_HS
 SG_ GFHBFwVsnRngTrkRev2 : 16|12@0+ (0.2,0) [0|819] "m"  CGM_HS,EOCM2B_K1_HS,AHL_AFL_HS
 SG_ GFHBFwVsnAzmthTrkRev2 : 10|10@0- (0.05,0) [-25.6|25.55] "deg"  CGM_HS,EOCM2B_K1_HS,AHL_AFL_HS
 SG_ GFHBFVsnObjTypTrkRev2 : 14|4@0+ (1,0) [0|15] ""  CGM_HS,EOCM2B_K1_HS,AHL_AFL_HS
 SG_ GFHBObjDirTrk2 : 15|1@0+ (1,0) [0|1] ""  CGM_HS,EOCM2B_K1_HS,AHL_AFL_HS
 SG_ GFHBFwVsnMesStatTrk2 : 1|2@0+ (1,0) [0|3] ""  CGM_HS,EOCM2B_K1_HS,AHL_AFL_HS
 SG_ GFHBFwVsnObjIDTrk2 : 7|6@0+ (1,0) [0|63] ""  CGM_HS,EOCM2B_K1_HS,AHL_AFL_HS

BO_ 1024 LGT_ObjectDetect_Info_1_HS: 8 EOCM_F_HS
 SG_ GFHBFwVsnWidthTrk1 : 62|7@0+ (0.1,0) [0|12.7] "deg"  CGM_HS,EOCM2B_K1_HS,AHL_AFL_HS
 SG_ GFHBFwVsnVertPosTrk1 : 53|6@0+ (0.25,-3) [-3|12.75] "deg"  CGM_HS,EOCM2B_K1_HS,AHL_AFL_HS
 SG_ GFHBFwVsnRelLaneTrk1 : 55|2@0+ (1,0) [0|3] ""  CGM_HS,EOCM2B_K1_HS,AHL_AFL_HS
 SG_ GFHBFwVsnAzmthRtTrk1 : 34|11@0- (0.125,0) [-128|127.875] "deg/s"  CGM_HS,EOCM2B_K1_HS,AHL_AFL_HS
 SG_ GFHBFwVsnCnfdncTrk1 : 36|2@0+ (1,0) [0|3] ""  CGM_HS,EOCM2B_K1_HS,AHL_AFL_HS
 SG_ GFHBFwVsnRngTrkRev1 : 16|12@0+ (0.2,0) [0|819] "m"  CGM_HS,EOCM2B_K1_HS,AHL_AFL_HS
 SG_ GFHBFwVsnAzmthTrkRev1 : 10|10@0- (0.05,0) [-25.6|25.55] "deg"  CGM_HS,EOCM2B_K1_HS,AHL_AFL_HS
 SG_ GFHBFVsnObjTypTrkRev1 : 14|4@0+ (1,0) [0|15] ""  CGM_HS,EOCM2B_K1_HS,AHL_AFL_HS
 SG_ GFHBObjDirTrk1 : 15|1@0+ (1,0) [0|1] ""  CGM_HS,EOCM2B_K1_HS,AHL_AFL_HS
 SG_ GFHBFwVsnMesStatTrk1 : 1|2@0+ (1,0) [0|3] ""  CGM_HS,EOCM2B_K1_HS,AHL_AFL_HS
 SG_ GFHBFwVsnObjIDTrk1 : 7|6@0+ (1,0) [0|63] ""  CGM_HS,EOCM2B_K1_HS,AHL_AFL_HS

BO_ 508 PPEI_Long_Lat_Sensor_Data_HS: 8 EBCM_HS
 SG_ LonLatAccSnsChk : 50|11@0+ (1,0) [0|2047] ""  CGM_HS,HCP_HS,ECM_HS,ICCM_B_HS,ICCM_OBD_HS,ICCM_HS,TCM_HS
 SG_ LonLatAccSnsValARC : 55|2@0+ (1,0) [0|3] ""  CGM_HS,HCP_HS,ECM_HS,ICCM_B_HS,ICCM_OBD_HS,ICCM_HS,TCM_HS
 SG_ LatAccSnsVal : 23|16@0- (0.00012207,0) [-3.99998976|3.99986769] "g"  CGM_HS,HCP_HS,ECM_HS,ICCM_B_HS,ICCM_OBD_HS,ICCM_HS,TCM_HS
 SG_ LonAccSnsVal : 7|16@0- (0.00012207,0) [-3.99998976|3.99986769] "g"  CGM_HS,HCP_HS,ECM_HS,ICCM_B_HS,ICCM_OBD_HS,ICCM_HS,TCM_HS
 SG_ ChsSysTtlBkAxlTqStARC : 53|2@0+ (1,0) [0|3] ""  CGM_HS,ECM_HS
 SG_ CSTBATS_TrqVl : 37|14@0+ (2,0) [0|32766] "Nm"  CGM_HS,HCP_B_HS,SADS_HS,TCCM_HS,ECM_HS,ICCM_B_HS,ICCM_OBD_HS,ICCM_HS,HCP_T_HS,TCM_HS
 SG_ CSTBATS_TrqVlV : 38|1@0+ (1,0) [0|1] ""  CGM_HS,HCP_B_HS,SADS_HS,TCCM_HS,ECM_HS,ICCM_B_HS,ICCM_OBD_HS,ICCM_HS,HCP_T_HS,TCM_HS

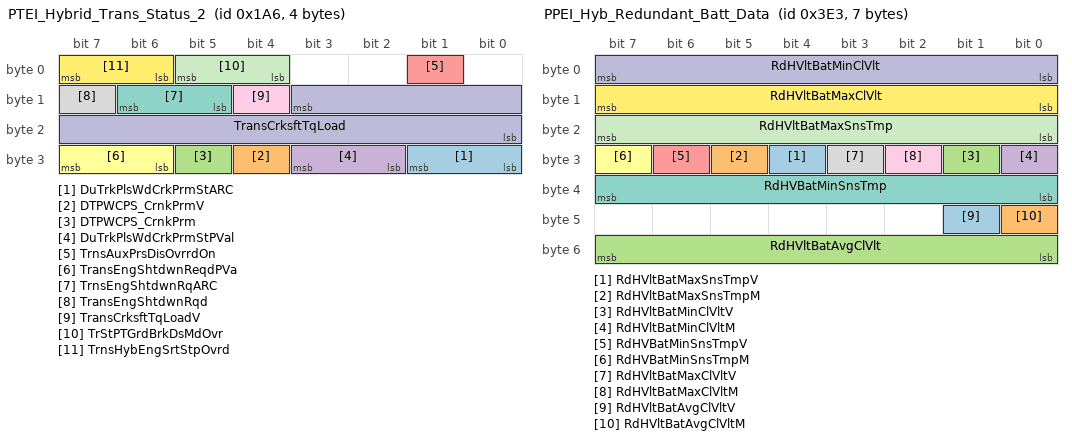
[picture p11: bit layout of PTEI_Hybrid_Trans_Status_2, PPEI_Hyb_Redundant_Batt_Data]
BO_ 422 PTEI_Hybrid_Trans_Status_2: 4 TCM_HS
 SG_ DuTrkPlsWdCrkPrmStARC : 25|2@0+ (1,0) [0|3] ""  CGM_HS,ECM_HS
 SG_ DTPWCPS_CrnkPrmV : 28|1@0+ (1,0) [0|1] ""  CGM_HS,ECM_HS
 SG_ DTPWCPS_CrnkPrm : 29|1@0+ (1,0) [0|1] ""  CGM_HS,ECM_HS
 SG_ DuTrkPlsWdCrkPrmStPVal : 27|2@0+ (1,0) [0|3] ""  CGM_HS,ECM_HS
 SG_ TrnsAuxPrsDisOvrrdOn : 1|1@0+ (1,0) [0|1] ""  CGM_HS,HCP_B_HS,ECM_HS
 SG_ TransEngShtdwnReqdPVa : 31|2@0+ (1,0) [0|3] ""  CGM_HS,ECM_HS
 SG_ TrnsEngShtdwnRqARC : 14|2@0+ (1,0) [0|3] ""  CGM_HS,ECM_HS
 SG_ TransEngShtdwnRqd : 15|1@0+ (1,0) [0|1] ""  CGM_HS,ECM_HS
 SG_ TransCrksftTqLoadV : 12|1@0+ (1,0) [0|1] ""  CGM_HS,ECM_HS
 SG_ TransCrksftTqLoad : 11|12@0+ (0.5,-848) [-848|1199.5] "Nm"  CGM_HS,ECM_HS
 SG_ TrStPTGrdBrkDsMdOvr : 5|2@0+ (1,0) [0|3] ""  CGM_HS,ECM_HS
 SG_ TrnsHybEngSrtStpOvrd : 7|2@0+ (1,0) [0|3] ""  CGM_HS,HCP_B_HS,ECM_HS,BCP_HS

BO_ 647 PTEI_Transfer_Case_Supplemental: 6 ECM_HS
 SG_ DrvCrwlModeCmnd : 31|1@0+ (1,0) [0|1] ""  CGM_HS,TCM_HS
 SG_ EngCntDtIntRSnsPsWdtV : 29|1@0+ (1,0) [0|1] ""  CGM_HS,TCM_HS
 SG_ CrnksftTqModRspMxCapV : 28|1@0+ (1,0) [0|1] ""  CGM_HS,TCM_HS
 SG_ CrnksftTqModRspMxCap : 27|12@0+ (0.5,-848) [-848|1199.5] "Nm"  CGM_HS,TCM_HS
 SG_ EngDetPndTrnCsRngShfV : 21|1@0+ (1,0) [0|1] ""  CGM_HS,TCM_HS
 SG_ EngDetPndTrnCsRngShf : 20|2@0+ (1,0) [0|3] ""  CGM_HS,TCM_HS
 SG_ EngCntDtIntRSnsPsWdt : 47|8@0+ (0.392157,0) [0|100.000035] "%"  CGM_HS,TCM_HS
 SG_ CrpCstCrvCmd : 18|3@0+ (1,0) [0|7] ""  CGM_HS,TCM_HS,HCP_T_HS
 SG_ DrvMntnMdCmnd : 11|1@0+ (1,0) [0|1] ""  CGM_HS,HCP_T_HS,HCP_HS
 SG_ DrvHldMdCmnd : 12|1@0+ (1,0) [0|1] ""  CGM_HS,HCP_T_HS,HCP_HS
 SG_ DrPTGrdBrkDsbMdCmd : 22|1@0+ (1,0) [0|1] ""  CGM_HS,HCP_T_HS,TCM_HS,HCP_HS
 SG_ DrvWntrMdCmd : 13|1@0+ (1,0) [0|1] ""  CGM_HS,TCM_HS
 SG_ DrvTwHaulMdCmd : 14|1@0+ (1,0) [0|1] ""  CGM_HS,HCP_T_HS,HCP_HS,TCM_HS,HCP_B_HS
 SG_ DrvSprtMdCmd : 15|1@0+ (1,0) [0|1] ""  CGM_HS,HCP_T_HS,TCM_HS,HCP_HS
 SG_ DrvEconMdCmd : 5|1@0+ (1,0) [0|1] ""  CGM_HS,TCM_HS
 SG_ EngCntrlDtrmdTrfCRngV : 10|1@0+ (1,0) [0|1] ""  CGM_HS,ICCM_B_HS,ICCM_OBD_HS,ICCM_HS,TCM_HS,FICM_HS
 SG_ EngCntrlDtrmdTrfCRng : 9|2@0+ (1,0) [0|3] ""  CGM_HS,ICCM_B_HS,ICCM_OBD_HS,ICCM_HS,TCM_HS,FICM_HS
 SG_ EngCtrlUtldTrnCRgPVal : 1|2@0+ (1,0) [0|3] ""  CGM_HS,HCP_T_HS,EBCM_OBD_HS,EBCM_HS,HCP_HS
 SG_ EngCntrlUtldTrnCsRng : 3|2@0+ (1,0) [0|3] ""  CGM_HS,HCP_T_HS,EBCM_OBD_HS,EBCM_HS,BCP_HS,HCP_HS
 SG_ EngCntrlUtldTrnCsRgIn : 4|1@0+ (1,0) [0|1] ""  CGM_HS,HCP_T_HS,EBCM_OBD_HS,EBCM_HS,HCP_HS
 SG_ EngCtrlUtldTrnCRgARC : 7|2@0+ (1,0) [0|3] ""  CGM_HS,HCP_T_HS,EBCM_OBD_HS,EBCM_HS,HCP_HS

BO_ 368 Environment_Id_Resp_5_HS: 3 ONSTAR_HS
 SG_ EnvIdRspSt5 : 17|2@0+ (1,0) [0|3] ""  BCM_HS
 SG_ EnvIdRsp5 : 7|16@0+ (1,0) [0|65535] ""  BCM_HS

BO_ 995 PPEI_Hyb_Redundant_Batt_Data: 7 VITM_OBD_HS
 SG_ RdHVltBatMaxSnsTmpV : 28|1@0+ (1,0) [0|1] ""  CGM_HS,VICM_HS
 SG_ RdHVltBatMaxSnsTmpM : 29|1@0+ (1,0) [0|1] ""  CGM_HS,VICM_HS
 SG_ RdHVltBatMinClVltV : 25|1@0+ (1,0) [0|1] ""  CGM_HS,VICM_HS
 SG_ RdHVltBatMinClVltM : 24|1@0+ (1,0) [0|1] ""  CGM_HS,VICM_HS
 SG_ RdHVBatMinSnsTmpV : 30|1@0+ (1,0) [0|1] ""  CGM_HS,VICM_HS
 SG_ RdHVBatMinSnsTmpM : 31|1@0+ (1,0) [0|1] ""  CGM_HS,VICM_HS
 SG_ RdHVBatMinSnsTmp : 39|8@0+ (0.5,-40) [-40|87.5] "deg C"  CGM_HS,VICM_HS
 SG_ RdHVltBatMaxClVltV : 27|1@0+ (1,0) [0|1] ""  CGM_HS,VICM_HS
 SG_ RdHVltBatMaxClVltM : 26|1@0+ (1,0) [0|1] ""  CGM_HS,VICM_HS
 SG_ RdHVltBatMinClVlt : 7|8@0+ (0.02,0) [0|5.1] "V"  CGM_HS,VICM_HS
 SG_ RdHVltBatMaxSnsTmp : 23|8@0+ (0.5,-40) [-40|87.5] "deg C"  CGM_HS,VICM_HS
 SG_ RdHVltBatMaxClVlt : 15|8@0+ (0.02,0) [0|5.1] "V"  CGM_HS,VICM_HS
 SG_ RdHVltBatAvgClVltV : 41|1@0+ (1,0) [0|1] ""  CGM_HS,VICM_HS
 SG_ RdHVltBatAvgClVltM : 40|1@0+ (1,0) [0|1] ""  CGM_HS,VICM_HS
 SG_ RdHVltBatAvgClVlt : 55|8@0+ (0.02,0) [0|5.1] "volts"  CGM_HS,VICM_HS

BO_ 971 PPEI_IBS_Battery_Status_1: 6 BCM_HS
 SG_ BatVltHiResV : 7|1@0+ (1,0) [0|1] ""  CGM_HS,EOCM2B_K1_HS,EOCM2A_K1_HS,ECM_HS
 SG_ BatVltHiRes : 6|15@0+ (0.001,0) [0|32.767] "volts"  CGM_HS,EOCM2B_K1_HS,EOCM2A_K1_HS,ECM_HS
 SG_ BCHR_BattCrntRwVal : 37|14@0+ (0.001,-8.192) [-8.192|8.191] ""  CGM_HS,EOCM2B_K1_HS,EOCM2A_K1_HS,ECM_HS
 SG_ BCHR_BattCrntRwVlMu : 39|2@0+ (1,0) [0|3] ""  CGM_HS,EOCM2B_K1_HS,EOCM2A_K1_HS,ECM_HS
 SG_ BCHR_BattCrntRwValV : 24|1@0+ (1,0) [0|1] ""  CGM_HS,EOCM2B_K1_HS,EOCM2A_K1_HS,ECM_HS

BO_ 209 PPEI_Driver_Command_Brake_Status: 7 EBCM_HS
 SG_ BrkModMinVoltReqARC : 54|2@0+ (1,0) [0|3] ""  ECM_HS,CGM_HS
 SG_ BrkModMinVoltReq : 52|5@0+ (0.625,0) [0|19.375] ""  ECM_HS,CGM_HS
 SG_ ChsBrkPdlPsERltdV : 55|1@0+ (1,0) [0|1] ""  CGM_HS,EOCM2B_K1_HS,EOCM2A_K1_HS,ECM_HS
 SG_ ChsBrkPdlPsERltdPVal : 47|8@0+ (1,0) [0|255] ""  CGM_HS,EOCM2B_K1_HS,EOCM2A_K1_HS,ECM_HS
 SG_ ChsBrkPdlPsERltdARC : 23|2@0+ (1,0) [0|3] ""  CGM_HS,EOCM2B_K1_HS,EOCM2A_K1_HS,ECM_HS
 SG_ ChsBrkPdlPsERltd : 39|8@0+ (0.392157,0) [0|100.000035] "%"  CGM_HS,EOCM2B_K1_HS,EOCM2A_K1_HS,ECM_HS
 SG_ DrvIntndTtlBrkTrqPVal : 21|14@0+ (1,0) [0|16383] ""  CGM_HS,EOCM2B_K1_HS,EOCM2A_K1_HS,ECM_HS
 SG_ DrvIntndTtlBrkTrqARC : 7|2@0+ (1,0) [0|3] ""  CGM_HS,EOCM2B_K1_HS,EOCM2A_K1_HS,ECM_HS
 SG_ DrvIntndTtlBrkTrq : 5|14@0+ (2,0) [0|32766] "Nm"  CGM_HS,EOCM2B_K1_HS,EOCM2A_K1_HS,ECM_HS,HCP_T_HS,HCP_HS,BSM_HS,VICM_HS

BO_ 454 PPEI_Chassis_Sys_Axl_Torque_Req: 8 EBCM_HS
 SG_ APAAxlTrqRdctnAct : 7|1@0+ (1,0) [0|1] ""  CGM_HS,ECM_HS
 SG_ ChsSysPrdAxlTqRqPV : 41|18@0+ (1,0) [0|262143] ""  CGM_HS,ECM_HS
 SG_ CSPATR_TrqIntrvnTyp : 39|2@0+ (1,0) [0|3] ""  CGM_HS,ECM_HS
 SG_ CSPATR_PrdTrqRqVal : 22|15@0+ (2,-22534) [-22534|43000] "Nm"  CGM_HS,ECM_HS
 SG_ CSPATR_TrqRqTyp : 23|1@0+ (1,0) [0|1] ""  CGM_HS,ECM_HS
 SG_ ChsSysImmAxlTqRqVal : 6|15@0+ (2,-22534) [-22534|43000] "Nm"  CGM_HS,ECM_HS
 SG_ ChsSysAxlTqRqRspTyp : 37|3@0+ (1,0) [0|7] ""  CGM_HS,ECM_HS
 SG_ ChsSysPrdAxlTqRqARC : 47|2@0+ (1,0) [0|3] ""  CGM_HS,ECM_HS

BO_ 1189 PTEI_Trans_General_Status_3_HS: 1 TCM_HS
 SG_ TransAirFlwPrcntRq : 7|6@0+ (1.5873015873,0) [0|100] "%"  CGM_HS,ECM_HS

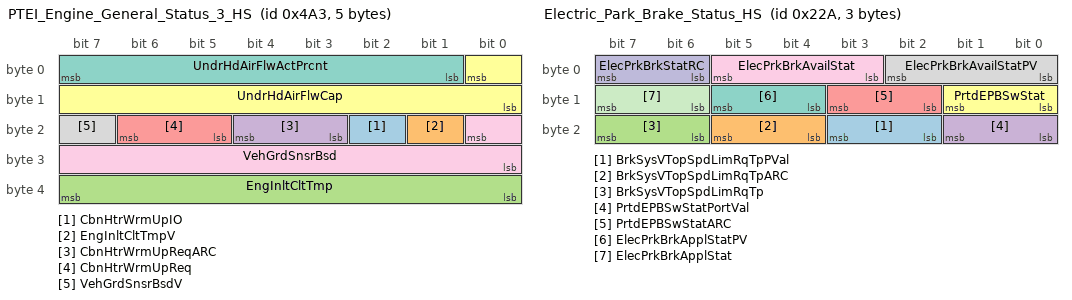
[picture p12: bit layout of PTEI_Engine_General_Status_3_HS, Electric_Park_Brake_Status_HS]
BO_ 1187 PTEI_Engine_General_Status_3_HS: 5 ECM_HS
 SG_ CbnHtrWrmUpIO : 18|1@0+ (1,0) [0|1] ""  CGM_HS,BCM_HS
 SG_ EngInltCltTmpV : 17|1@0+ (1,0) [0|1] ""  CGM_HS,TCM_HS
 SG_ EngInltCltTmp : 39|8@0+ (1,-40) [-40|215] "deg C"  CGM_HS,TCM_HS
 SG_ CbnHtrWrmUpReqARC : 20|2@0+ (1,0) [0|3] ""  TCM_HS,CGM_HS
 SG_ CbnHtrWrmUpReq : 22|2@0+ (1,0) [0|3] ""  TCM_HS,CGM_HS
 SG_ UndrHdAirFlwCap : 0|9@0+ (2,0) [0|1022] "m^3/min"  CGM_HS,HCP_T_HS,TCM_HS,BSM_HS,VICM_HS,HCP_B_HS
 SG_ UndrHdAirFlwActPrcnt : 7|7@0+ (0.787402,0) [0|100.000054] "%"  CGM_HS,HCP_T_HS,TCM_HS,BSM_HS,VICM_HS,HCP_B_HS
 SG_ VehGrdSnsrBsdV : 23|1@0+ (1,0) [0|1] ""  CGM_HS,FICM_HS,HCP_T_HS,TCM_HS,HCP_B_HS,HCP_HS
 SG_ VehGrdSnsrBsd : 16|9@0- (0.1945,0) [-49.792|49.5975] "%"  CGM_HS,FICM_HS,HCP_T_HS,TCM_HS,HCP_B_HS,HCP_HS

BO_ 554 Electric_Park_Brake_Status_HS: 3 EPB_HS
 SG_ BrkSysVTopSpdLimRqTpPVal : 19|2@0+ (1,0) [0|3] ""  ECM_HS,CGM_HS
 SG_ BrkSysVTopSpdLimRqTpARC : 21|2@0+ (1,0) [0|3] ""  CGM_HS,ECM_HS
 SG_ BrkSysVTopSpdLimRqTp : 23|2@0+ (1,0) [0|3] ""  CGM_HS,ECM_HS
 SG_ PrtdEPBSwStatPortVal : 17|2@0+ (1,0) [0|3] "Counts"  CGM_HS,EBCM_OBD_HS,EBCM_HS
 SG_ PrtdEPBSwStatARC : 11|2@0+ (1,0) [0|3] "Counts"  CGM_HS,EBCM_OBD_HS,EBCM_HS
 SG_ PrtdEPBSwStat : 9|2@0+ (1,0) [0|3] ""  CGM_HS,EBCM_OBD_HS,EBCM_HS
 SG_ ElecPrkBrkApplStatPV : 13|2@0+ (1,0) [0|3] ""  CGM_HS,HCP_T_HS,TCCM_HS,ECM_HS,ICCM_HS,VICM_HS,EBCM_OBD_HS,EBCM_HS
 SG_ ElecPrkBrkAvailStatPV : 2|3@0+ (1,0) [0|7] ""  CGM_HS,HCP_T_HS,ECM_HS,ICCM_HS,TCCM_HS,VICM_HS,EBCM_OBD_HS,EBCM_HS
 SG_ ElecPrkBrkAvailStat : 5|3@0+ (1,0) [0|7] ""  CGM_HS,HCP_T_HS,TCM_HS,ECM_HS,ICCM_HS,TCCM_HS,VICM_HS,EBCM_OBD_HS,EBCM_HS
 SG_ ElecPrkBrkStatRC : 7|2@0+ (1,0) [0|3] ""  CGM_HS,HCP_T_HS,ECM_HS,ICCM_HS,TCCM_HS,VICM_HS,EBCM_OBD_HS,EBCM_HS
 SG_ ElecPrkBrkApplStat : 15|2@0+ (1,0) [0|3] ""  TCCM_HS,CGM_HS,HCP_T_HS,TCM_HS,ECM_HS,ICCM_HS,VICM_HS,EBCM_OBD_HS,EBCM_HS

BO_ 487 PPEI_Fuel_System_Request_3: 8 ECM_HS
 SG_ CmmndAirFuelRatio : 55|16@0+ (0.000488281,0) [0|31.999495335] ""  CGM_HS,ICCM_B_HS,ICCM_OBD_HS,ICCM_HS
 SG_ InstFuelFlowEst : 23|16@0+ (0.000976562,0) [0|63.99899067] "grams/s"  CGM_HS,ICCM_B_HS,ICCM_OBD_HS,ICCM_HS
 SG_ FuelDelPressRqd : 1|10@0+ (1,0) [0|1023] "kPa"  CGM_HS,ICCM_B_HS,ICCM_OBD_HS,ICCM_HS
 SG_ EngRunng : 5|1@0+ (1,0) [0|1] ""  ICCM_B_HS,ICCM_OBD_HS,ICCM_HS
 SG_ FlPmpEDscOtptCmdSta : 6|1@0+ (1,0) [0|1] ""  CGM_HS,ICCM_B_HS,ICCM_OBD_HS,ICCM_HS
 SG_ FuelCntlSysFltPrsnt : 7|1@0+ (1,0) [0|1] ""  CGM_HS,ICCM_B_HS,ICCM_OBD_HS,ICCM_HS
 SG_ HiPresFuelPmpDelDur : 33|10@0+ (1,0) [0|1023] "deg"  CGM_HS,ICCM_B_HS,ICCM_OBD_HS,ICCM_HS
 SG_ HiPresFuelPmpCntMd : 39|4@0+ (1,0) [0|15] ""  CGM_HS,ICCM_B_HS,ICCM_OBD_HS,ICCM_HS

BO_ 566 VICM_Status_HS: 7 VICM_HS
 SG_ RdDCChrgCntctrStat : 49|2@0+ (1,0) [0|3] ""  HCP_HS,HCP_B_HS,HCP_T_HS,CGM_HS,MCP_B_HS,MCP_A_HS
 SG_ RdHVBatHtrCntctrStat : 51|2@0+ (1,0) [0|3] ""  HCP_HS,HCP_B_HS,HCP_T_HS,CGM_HS,MCP_B_HS,MCP_A_HS
 SG_ RHVBCCS_InvtrCaptrChrgAct : 52|1@0+ (1,0) [0|1] ""  HCP_HS,HCP_B_HS,HCP_T_HS,CGM_HS,MCP_B_HS,MCP_A_HS
 SG_ RHVBCCS_DCChrgrCntCmd : 53|1@0+ (1,0) [0|1] ""  HCP_HS,HCP_B_HS,HCP_T_HS,CGM_HS,MCP_B_HS,MCP_A_HS
 SG_ RHVBCCS_InvtrCntCmd : 54|1@0+ (1,0) [0|1] ""  HCP_HS,HCP_B_HS,HCP_T_HS,CGM_HS,MCP_B_HS,MCP_A_HS
 SG_ RHVBCCS_ACChrgrCntCmd : 55|1@0+ (1,0) [0|1] ""  HCP_HS,HCP_B_HS,HCP_T_HS,CGM_HS,MCP_B_HS,MCP_A_HS
 SG_ RdHVCntctrShdwnCmd : 47|3@0+ (1,0) [0|7] ""  CGM_HS,HCP_T_HS,HCP_HS
 SG_ ChrgSysShftPrkReqPval : 44|2@0+ (1,0) [0|3] ""  ECM_HS,CGM_HS,ICCM_HS
 SG_ ChrgSysShftPrkReqARC : 42|2@0+ (1,0) [0|3] ""  ECM_HS,CGM_HS,ICCM_HS
 SG_ ChrgSysShftPrkReq : 40|1@0+ (1,0) [0|1] ""  ECM_HS,CGM_HS,ICCM_HS
 SG_ ChrgSysAudblIndRq : 39|3@0+ (1,0) [0|7] ""  BCM_HS,PFAF_HS,CGM_HS
 SG_ HVBatChrgCrdAlrtReq : 7|2@0+ (1,0) [0|3] ""  CGM_HS,PFAF_HS
 SG_ RdHVBatLwParMdReq : 32|1@0+ (1,0) [0|1] ""  CGM_HS,VITM_OBD_HS
 SG_ RdHVBtClOVFFTstRq : 31|1@0+ (1,0) [0|1] ""  CGM_HS,VITM_OBD_HS
 SG_ RdHVBtClOVFFTstIdx : 30|7@0+ (1,0) [0|127] ""  CGM_HS,VITM_OBD_HS
 SG_ ClimCtrlHVDvcShtdwnCmd : 23|1@0+ (1,0) [0|1] ""  CGM_HS,ACCM_HS
 SG_ ThrmlRefCompSpdReqARC : 36|2@0+ (1,0) [0|3] " "  CGM_HS,ACCM_HS
 SG_ VICMHVEnMgCmEnTrS : 22|1@0+ (1,0) [0|1] ""  CGM_HS,VITM_OBD_HS
 SG_ ChrgSysPrkBrkAnmsBrkReqPVal : 20|2@0+ (1,0) [0|3] ""  CGM_HS,EBCM_OBD_HS,EBCM_HS,EPB_HS
 SG_ ChrgSysPrkBrkAnmsBrkReqARC : 18|2@0+ (1,0) [0|3] ""  CGM_HS,EBCM_OBD_HS,EBCM_HS,EPB_HS
 SG_ ChrgSysPrkBrkAnmsBrkReq : 16|1@0+ (1,0) [0|1] ""  CGM_HS,EBCM_OBD_HS,EBCM_HS,EPB_HS
 SG_ HybVehHiVltSysDisbld_236 : 21|1@0+ (1,0) [0|1] ""  CGM_HS,TCP_HS,ONSTAR_HS
 SG_ ThrmlRefCompSpdReq : 5|14@0+ (1,0) [0|16383] "rpm"  CGM_HS,ACCM_HS

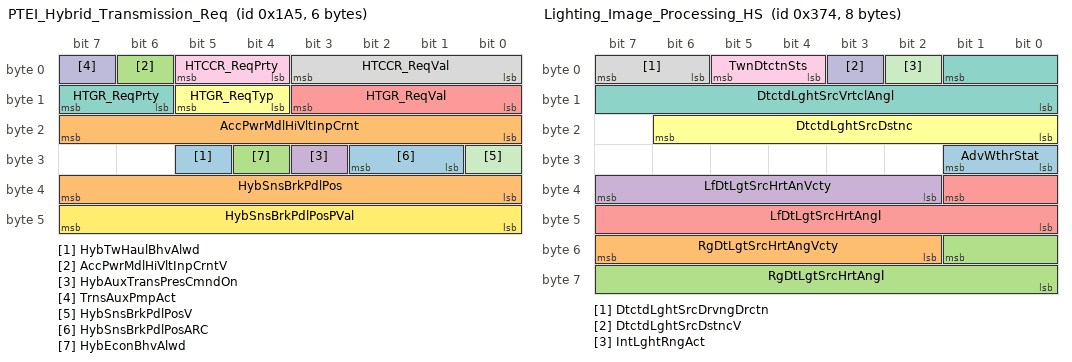
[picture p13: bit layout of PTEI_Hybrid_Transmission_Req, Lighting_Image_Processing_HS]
BO_ 421 PTEI_Hybrid_Transmission_Req: 6 BCP_HS
 SG_ HybTwHaulBhvAlwd : 29|1@0+ (1,0) [0|1] ""  CGM_HS,TCM_HS
 SG_ AccPwrMdlHiVltInpCrnt : 23|8@0+ (0.1,0) [0|25.5] "amps"  CGM_HS,MCP_A_HS
 SG_ AccPwrMdlHiVltInpCrntV : 6|1@0+ (1,0) [0|1] ""  CGM_HS,MCP_A_HS
 SG_ HybAuxTransPresCmndOn : 27|1@0+ (1,0) [0|1] ""  CGM_HS,TCM_HS
 SG_ HTGR_ReqVal : 11|4@0+ (1,0) [0|15] ""  CGM_HS,TCM_HS
 SG_ HTGR_ReqTyp : 13|2@0+ (1,0) [0|3] ""  CGM_HS,TCM_HS
 SG_ HTGR_ReqPrty : 15|2@0+ (1,0) [0|3] ""  CGM_HS,TCM_HS
 SG_ HTCCR_ReqVal : 3|4@0+ (1,0) [0|15] ""  CGM_HS,TCM_HS
 SG_ HTCCR_ReqPrty : 5|2@0+ (1,0) [0|3] ""  CGM_HS,TCM_HS
 SG_ TrnsAuxPmpAct : 7|1@0+ (1,0) [0|1] ""  TCM_HS
 SG_ HybSnsBrkPdlPosV : 24|1@0+ (1,0) [0|1] ""  CGM_HS,EBCM_OBD_HS,EBCM_HS,ICCM_B_HS,ICCM_OBD_HS,ICCM_HS,TCM_HS,ECM_HS
 SG_ HybSnsBrkPdlPosPVal : 47|8@0+ (1,0) [0|255] ""  CGM_HS,EBCM_OBD_HS,EBCM_HS,ICCM_B_HS,ICCM_OBD_HS,ICCM_HS,TCM_HS,ECM_HS
 SG_ HybSnsBrkPdlPosARC : 26|2@0+ (1,0) [0|3] ""  CGM_HS,EBCM_OBD_HS,EBCM_HS,ICCM_B_HS,ICCM_OBD_HS,ICCM_HS,TCM_HS,ECM_HS
 SG_ HybSnsBrkPdlPos : 39|8@0+ (0.392157,0) [0|100.000035] "%"  CGM_HS,EBCM_OBD_HS,EBCM_HS,ICCM_B_HS,ICCM_OBD_HS,ICCM_HS,TCM_HS,ECM_HS
 SG_ HybEconBhvAlwd : 28|1@0+ (1,0) [0|1] ""  CGM_HS,TCM_HS

BO_ 456 PPEI_Trans_General_Status_4: 8 EBCM_HS
 SG_ PerfTrcEngSpdReqProt : 53|14@0+ (1,0) [0|16383] ""  CGM_HS,ECM_HS
 SG_ PTESR_EngSpdRqVal : 1|10@0+ (8,0) [0|8184] "rpm"  CGM_HS,ECM_HS,LVMPC_HS
 SG_ PTESR_EngSpdCntlRs : 3|2@0+ (1,0) [0|3] ""  CGM_HS,ECM_HS,LVMPC_HS
 SG_ PTESR_EngSpdIntTyp : 5|2@0+ (1,0) [0|3] ""  CGM_HS,ECM_HS,LVMPC_HS
 SG_ PerfTrcTrqRqProt : 39|16@0+ (1,0) [0|65535] ""  CGM_HS,ECM_HS
 SG_ PTTR_TrqReqVal : 19|12@0+ (0.5,-848) [-848|1199.5] "Nm"  CGM_HS,ICCM_B_HS,ICCM_OBD_HS,ICCM_HS,ECM_HS
 SG_ PTTR_TrqRedRlzSugg : 21|2@0+ (1,0) [0|3] ""  CGM_HS,ICCM_B_HS,ICCM_OBD_HS,ICCM_HS,ECM_HS
 SG_ PTTR_TrqInvTyp : 23|2@0+ (1,0) [0|3] ""  CGM_HS,ICCM_B_HS,ICCM_OBD_HS,ICCM_HS,ECM_HS
 SG_ PerfTrcARC : 7|2@0+ (1,0) [0|3] ""  CGM_HS,ECM_HS

BO_ 884 Lighting_Image_Processing_HS: 8 FCM_HS
 SG_ AdvWthrStat : 25|2@0+ (1,0) [0|3] ""  V2V_HS,EOCM2B_K1_HS,CGM_HS,EDI_HS,AHL_AFL_HS
 SG_ RgDtLgtSrcHrtAngVcty : 55|6@0- (1,0) [-32|31] "deg/sec"  EOCM2B_K1_HS,CGM_HS,AHL_AFL_HS
 SG_ RgDtLgtSrcHrtAngl : 49|10@0- (0.04,0) [-20.48|20.44] "deg"  EOCM2B_K1_HS,CGM_HS,AHL_AFL_HS
 SG_ LfDtLgtSrcHrtAnVcty : 39|6@0- (1,0) [-32|31] "deg/sec"  EOCM2B_K1_HS,CGM_HS,AHL_AFL_HS
 SG_ LfDtLgtSrcHrtAngl : 33|10@0- (0.04,0) [-20.48|20.44] "deg"  EOCM2B_K1_HS,CGM_HS,AHL_AFL_HS
 SG_ DtctdLghtSrcDstnc : 22|7@0+ (10,0) [0|1270] "m"  EOCM2B_K1_HS,CGM_HS,AHL_AFL_HS
 SG_ DtctdLghtSrcVrtclAngl : 1|10@0- (0.04,0) [-20.48|20.44] "deg"  EOCM2B_K1_HS,CGM_HS,AHL_AFL_HS
 SG_ DtctdLghtSrcDrvngDrctn : 7|2@0+ (1,0) [0|3] ""  EOCM2B_K1_HS,CGM_HS,AHL_AFL_HS
 SG_ TwnDtctnSts : 5|2@0+ (1,0) [0|3] ""  EOCM2B_K1_HS,CGM_HS,AHL_AFL_HS
 SG_ DtctdLghtSrcDstncV : 3|1@0+ (1,0) [0|1] ""  EOCM2B_K1_HS,CGM_HS,AHL_AFL_HS
 SG_ IntLghtRngAct : 2|1@0+ (1,0) [0|1] ""  EOCM2B_K1_HS,CGM_HS,AHL_AFL_HS

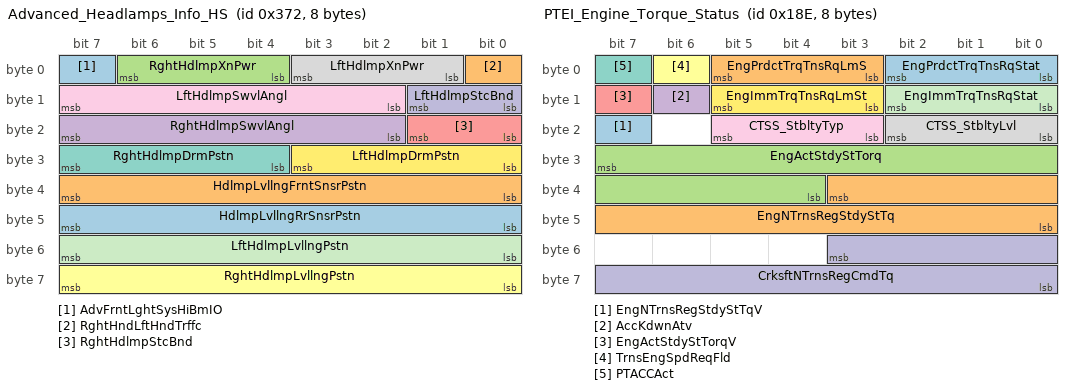
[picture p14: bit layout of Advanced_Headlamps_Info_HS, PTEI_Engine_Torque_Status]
BO_ 882 Advanced_Headlamps_Info_HS: 8 AHL_AFL_HS
 SG_ AdvFrntLghtSysHiBmIO : 7|1@0+ (1,0) [0|1] ""  EOCM2B_IMX6_HS,EOCM2A_IMX6_HS,CGM_HS,EOCM2B_K1_HS,EOCM2A_K1_HS,BCM_HS,FCM_HS
 SG_ RghtHndLftHndTrffc : 0|1@0+ (1,0) [0|1] ""  EOCM2B_IMX6_HS,EOCM2A_IMX6_HS,CGM_HS,EOCM2B_K1_HS,EOCM2A_K1_HS,FCM_HS
 SG_ RghtHdlmpXnPwr : 6|3@0+ (1,32) [32|39] "Watt"  EOCM2B_IMX6_HS,EOCM2A_IMX6_HS,CGM_HS,EOCM2B_K1_HS,EOCM2A_K1_HS,FCM_HS
 SG_ RghtHdlmpSwvlAngl : 23|6@0- (0.5,0) [-16|15.5] "deg"  EOCM2B_IMX6_HS,EOCM2A_IMX6_HS,CGM_HS,EOCM2B_K1_HS,EOCM2A_K1_HS,FCM_HS
 SG_ RghtHdlmpStcBnd : 17|2@0+ (25,25) [25|100] "%"  EOCM2B_IMX6_HS,EOCM2A_IMX6_HS,CGM_HS,EOCM2B_K1_HS,EOCM2A_K1_HS,FCM_HS
 SG_ RghtHdlmpLvllngPstn : 63|8@0- (0.05,0) [-6.4|6.35] "%"  EOCM2B_IMX6_HS,EOCM2A_IMX6_HS,CGM_HS,EOCM2B_K1_HS,EOCM2A_K1_HS,FCM_HS
 SG_ RghtHdlmpDrmPstn : 31|4@0+ (1,1) [1|16] ""  EOCM2B_IMX6_HS,EOCM2A_IMX6_HS,CGM_HS,EOCM2B_K1_HS,EOCM2A_K1_HS,FCM_HS
 SG_ LftHdlmpXnPwr : 3|3@0+ (1,32) [32|39] "Watt"  EOCM2B_IMX6_HS,EOCM2A_IMX6_HS,CGM_HS,EOCM2B_K1_HS,EOCM2A_K1_HS,FCM_HS
 SG_ LftHdlmpSwvlAngl : 15|6@0- (0.5,0) [-16|15.5] "deg"  EOCM2B_IMX6_HS,EOCM2A_IMX6_HS,CGM_HS,EOCM2B_K1_HS,EOCM2A_K1_HS,FCM_HS
 SG_ LftHdlmpStcBnd : 9|2@0+ (25,25) [25|100] "%"  EOCM2B_IMX6_HS,EOCM2A_IMX6_HS,CGM_HS,EOCM2B_K1_HS,EOCM2A_K1_HS,FCM_HS
 SG_ LftHdlmpLvllngPstn : 55|8@0- (0.05,0) [-6.4|6.35] "%"  EOCM2B_IMX6_HS,EOCM2A_IMX6_HS,CGM_HS,EOCM2B_K1_HS,EOCM2A_K1_HS,FCM_HS
 SG_ LftHdlmpDrmPstn : 27|4@0+ (1,1) [1|16] ""  EOCM2B_IMX6_HS,EOCM2A_IMX6_HS,CGM_HS,EOCM2B_K1_HS,EOCM2A_K1_HS,FCM_HS
 SG_ HdlmpLvllngRrSnsrPstn : 47|8@0- (1,0) [-128|127] "mm"  EOCM2B_IMX6_HS,EOCM2A_IMX6_HS,CGM_HS,EOCM2B_K1_HS,EOCM2A_K1_HS,FCM_HS
 SG_ HdlmpLvllngFrntSnsrPstn : 39|8@0- (1,0) [-128|127] "mm"  EOCM2B_IMX6_HS,EOCM2A_IMX6_HS,CGM_HS,EOCM2B_K1_HS,EOCM2A_K1_HS,FCM_HS

BO_ 393 PTEI_Transmission_Torque_Request: 7 TCM_HS
 SG_ TrnsTrqCap : 55|8@0+ (4,0) [0|1020] "Nm"  CGM_HS,ECM_HS
 SG_ TIDCTR_TrqIntvTyp : 23|2@0+ (1,0) [0|3] ""  CGM_HS,ECM_HS
 SG_ TIDCTR_TrqReqVal : 3|12@0+ (0.5,-848) [-848|1199.5] "Nm"  CGM_HS,ECM_HS
 SG_ TIDCTR_TrqRespTyp : 5|2@0+ (1,0) [0|3] ""  CGM_HS,ECM_HS
 SG_ TrnsPdCrkshftTqRqPVa : 37|14@0+ (1,0) [0|16383] ""  CGM_HS,ECM_HS
 SG_ TPCTR_TorqReqVal : 19|12@0+ (0.5,-848) [-848|1199.5] "Nm"  CGM_HS,ECM_HS
 SG_ TPCTR_TrqIntrvnTyp : 21|2@0+ (1,0) [0|3] ""  CGM_HS,ECM_HS
 SG_ TrnsTrqRqALC : 7|2@0+ (1,0) [0|3] ""  CGM_HS,ECM_HS

BO_ 199 PPEI_Transmission_Otpt_Rot_Stat: 4 HCP_T_HS
 SG_ TORSTimestamp : 23|16@0+ (1,0) [0|65535] "counts"  CGM_HS,HCP_B_HS,ECM_HS,ICCM_B_HS,ICCM_OBD_HS,ICCM_HS,TCCM_HS,BCP_HS,FICM_HS,EBCM_OBD_HS,EBCM_HS
 SG_ TORSPulsCntr : 1|10@0+ (1,0) [0|1023] "counts"  CGM_HS,HCP_B_HS,ECM_HS,ICCM_B_HS,ICCM_OBD_HS,ICCM_HS,TCCM_HS,BCP_HS,FICM_HS,EBCM_OBD_HS,EBCM_HS
 SG_ TORSValidity : 2|1@0+ (1,0) [0|1] ""  CGM_HS,HCP_B_HS,ECM_HS,ICCM_B_HS,ICCM_OBD_HS,ICCM_HS,TCCM_HS,BCP_HS,FICM_HS,EBCM_OBD_HS,EBCM_HS
 SG_ TORSRstOcrd : 3|1@0+ (1,0) [0|1] ""  CGM_HS,HCP_B_HS,ECM_HS,ICCM_B_HS,ICCM_OBD_HS,ICCM_HS,TCCM_HS,BCP_HS,FICM_HS,EBCM_OBD_HS,EBCM_HS
 SG_ TORSLstTransType : 5|2@0+ (1,0) [0|3] ""  CGM_HS,HCP_B_HS,ECM_HS,ICCM_B_HS,ICCM_OBD_HS,ICCM_HS,TCCM_HS,BCP_HS,FICM_HS,EBCM_OBD_HS,EBCM_HS
 SG_ TORSRotDir : 7|2@0+ (1,0) [0|3] ""  CGM_HS,HCP_B_HS,ECM_HS,ICCM_B_HS,ICCM_OBD_HS,ICCM_HS,TCCM_HS,BCP_HS,FICM_HS,EBCM_OBD_HS,EBCM_HS

BO_ 398 PTEI_Engine_Torque_Status: 8 ECM_HS
 SG_ EngNTrnsRegStdyStTqV : 23|1@0+ (1,0) [0|1] ""  CGM_HS,TCM_HS
 SG_ EngNTrnsRegStdyStTq : 35|12@0+ (0.5,-848) [-848|1199.5] "Nm"  CGM_HS,TCM_HS
 SG_ EngActStdyStTorq : 31|12@0+ (0.5,-848) [-848|1199.5] "Nm"  CGM_HS,TCCM_HS,TCM_HS
 SG_ AccKdwnAtv : 14|1@0+ (1,0) [0|1] ""  CGM_HS,TCM_HS,TCCM_HS
 SG_ EngActStdyStTorqV : 15|1@0+ (1,0) [0|1] ""  CGM_HS,TCM_HS,TCCM_HS
 SG_ TrnsEngSpdReqFld : 6|1@0+ (1,0) [0|1] ""  CGM_HS,TCM_HS,TCCM_HS
 SG_ PTACCAct : 7|1@0+ (1,0) [0|1] ""  CGM_HS,HCP_B_HS,HCP_T_HS,HCP_HS,BCP_HS,TCM_HS
 SG_ CTSS_StbltyLvl : 18|3@0+ (1,0) [0|7] ""  CGM_HS,TCM_HS
 SG_ CTSS_StbltyTyp : 21|3@0+ (1,0) [0|7] ""  CGM_HS,TCM_HS
 SG_ CrksftNTrnsRegCmdTq : 51|12@0+ (0.5,-848) [-848|1199.5] "Nm"  CGM_HS,TCM_HS
 SG_ EngImmTrqTnsRqStat : 10|3@0+ (1,0) [0|7] ""  CGM_HS,TCM_HS
 SG_ EngImmTrqTnsRqLmSt : 13|3@0+ (1,0) [0|7] ""  CGM_HS,TCM_HS
 SG_ EngPrdctTrqTnsRqStat : 2|3@0+ (1,0) [0|7] ""  CGM_HS,TCM_HS
 SG_ EngPrdctTrqTnsRqLmS : 5|3@0+ (1,0) [0|7] ""  CGM_HS,TCM_HS

BO_ 464 PPEI_Front_Axle_Status: 4 TCCM_HS
 SG_ FrtAxlOpeMod : 31|3@0+ (1,0) [0|7] ""  CGM_HS,EBCM_OBD_HS,EBCM_HS

BO_ 390 PTEI_Hybrid_Status_1: 7 HCP_HS
 SG_ HybCrpCstCrvRq : 43|3@0+ (1,0) [0|7] ""  CGM_HS,ECM_HS
 SG_ TransFldPmpMtrDrtd : 26|1@0+ (1,0) [0|1] ""  CGM_HS,TCM_HS
 SG_ RdHVInvRatVltV : 7|1@0+ (1,0) [0|1] ""  CGM_HS,BSM_HS,VICM_HS
 SG_ RdHVInvRatVlt : 40|9@0+ (1,0) [0|511] "volts"  CGM_HS,BSM_HS,VICM_HS
 SG_ EngActDmpgDsblReq : 27|1@0+ (1,0) [0|1] ""  CGM_HS,ECM_HS
 SG_ HybRdcdTrqCapMd1Cmnd : 5|1@0+ (1,0) [0|1] ""  CGM_HS,ECM_HS
 SG_ HybExtndDcFuelCORq : 31|1@0+ (1,0) [0|1] ""  CGM_HS,ECM_HS
 SG_ EstMtrPwrLossV : 30|1@0+ (1,0) [0|1] ""  CGM_HS,TCM_HS
 SG_ EstMtrPwrLoss : 39|8@0+ (0.25,0) [0|63.75] "kW"  CGM_HS,TCM_HS
 SG_ HybCmmFailRdPwrCmd : 4|1@0+ (1,0) [0|1] ""  CGM_HS,ECM_HS
 SG_ HybCmmdEngTrqLmtd : 23|8@0+ (0.75,-90) [-90|101.25] "Nm"  CGM_HS,ECM_HS
 SG_ HybACCompRq : 29|2@0+ (1,0) [0|3] ""  CGM_HS,ECM_HS
 SG_ HybGrdBrkgAct : 25|1@0+ (1,0) [0|1] ""  CGM_HS,TCM_HS
 SG_ HESSI_EngStrtTyp : 11|4@0+ (1,0) [0|15] ""  CGM_HS,BSM_HS,VICM_HS,ECM_HS
 SG_ HESSI_EngStrtStpMd : 15|4@0+ (1,0) [0|15] ""  CGM_HS,BSM_HS,VICM_HS,ECM_HS
 SG_ HybCrnkAbrtd : 0|1@0+ (1,0) [0|1] ""  CGM_HS,ECM_HS
 SG_ CnvntlEngStrtEnbld : 1|1@0+ (1,0) [0|1] ""  CGM_HS,ECM_HS
 SG_ HybDFCOReq : 6|1@0+ (1,0) [0|1] ""  CGM_HS,ECM_HS
 SG_ RdPTHVCntrReq : 3|2@0+ (1,0) [0|3] ""  CGM_HS,BSM_HS,VICM_HS

BO_ 817 Rear_Axle_General_Information_HS: 3 RDCM_HS
 SG_ RrAxlELSDCplLwResV : 2|1@0+ (1,0) [0|1] ""  CGM_HS,BCM_HS
 SG_ RrAxlELSDCplLwRes : 23|8@0+ (10,0) [0|2550] "Nm"  CGM_HS,BCM_HS
 SG_ RrDrvlnSysVehTpSpdLmVal : 15|8@0+ (2,0) [0|510] "km/h"  CGM_HS,BCM_HS
 SG_ RrAxlTmpInhIO : 1|1@0+ (1,0) [0|1] ""  CGM_HS,BCM_HS
 SG_ RrAxlMalfIO : 0|1@0+ (1,0) [0|1] ""  CGM_HS,BCM_HS,EBCM_OBD_HS,EBCM_HS

BO_ 465 PPEI_Rear_Axle_Status: 4 TCCM_HS
 SG_ RrAxlOpeMod : 31|3@0+ (1,0) [0|7] ""  CGM_HS,EBCM_OBD_HS,EBCM_HS
 SG_ RrAxlEstTrqV : 8|1@0+ (1,0) [0|1] ""  CGM_HS,EBCM_OBD_HS,EBCM_HS
 SG_ RrAxlEstTrq : 3|11@0- (5,0) [-5120|5115] "Nm"  CGM_HS,EBCM_OBD_HS,EBCM_HS
 SG_ RrAxlStat : 7|3@0+ (1,0) [0|7] ""  CGM_HS,EBCM_OBD_HS,EBCM_HS
 SG_ RrAxlCtrlMod : 4|1@0+ (1,0) [0|1] ""  CGM_HS,EBCM_OBD_HS,EBCM_HS
 SG_ RAMDVLReqVal : 22|7@0+ (2,0) [0|254] "rpm"  CGM_HS,EBCM_OBD_HS,EBCM_HS
 SG_ RAMDVLAtv : 23|1@0+ (1,0) [0|1] ""  CGM_HS,EBCM_OBD_HS,EBCM_HS

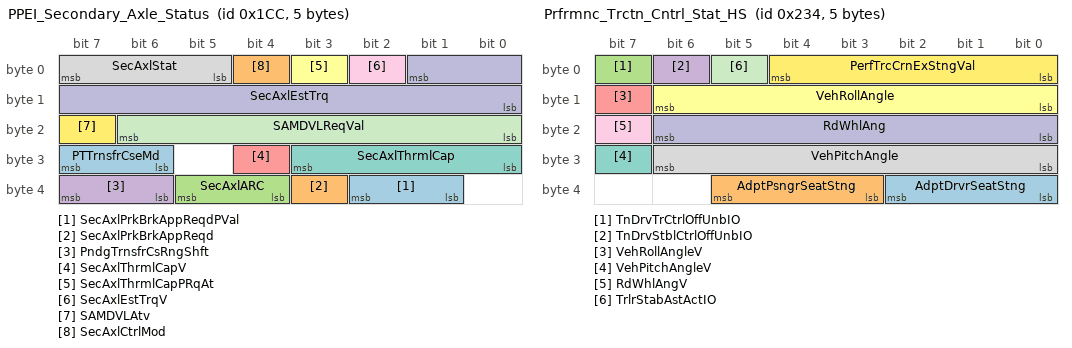
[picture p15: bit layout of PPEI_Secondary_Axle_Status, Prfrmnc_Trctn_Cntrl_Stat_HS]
BO_ 460 PPEI_Secondary_Axle_Status: 5 TCCM_HS
 SG_ SecAxlPrkBrkAppReqdPVal : 34|2@0+ (1,0) [0|3] ""  CGM_HS,EBCM_OBD_HS,EBCM_HS
 SG_ SecAxlPrkBrkAppReqd : 35|1@0+ (1,0) [0|1] ""  CGM_HS,EBCM_OBD_HS,EBCM_HS
 SG_ SecAxlARC : 37|2@0+ (1,0) [0|3] ""  CGM_HS,ECM_HS,EBCM_OBD_HS,EBCM_HS
 SG_ PndgTrnsfrCsRngShft : 39|2@0+ (1,0) [0|3] ""  EOCM2B_K1_HS,EOCM2A_K1_HS,CGM_HS,ECM_HS
 SG_ SecAxlThrmlCapV : 28|1@0+ (1,0) [0|1] ""  EOCM2B_K1_HS,EOCM2A_K1_HS,CGM_HS,EBCM_OBD_HS,EBCM_HS
 SG_ SecAxlThrmlCapPRqAt : 3|1@0+ (1,0) [0|1] ""  EOCM2B_K1_HS,EOCM2A_K1_HS,CGM_HS,EBCM_OBD_HS,EBCM_HS
 SG_ SecAxlThrmlCap : 27|4@0+ (6.7,0) [0|100.5] "%"  EOCM2B_K1_HS,EOCM2A_K1_HS,CGM_HS,EBCM_OBD_HS,EBCM_HS
 SG_ SecAxlStat : 7|3@0+ (1,0) [0|7] ""  EOCM2B_K1_HS,EOCM2A_K1_HS,CGM_HS,EOCM_F_HS,ACC_HS,EBCM_OBD_HS,EBCM_HS
 SG_ SecAxlEstTrqV : 2|1@0+ (1,0) [0|1] ""  EOCM2B_K1_HS,EOCM2A_K1_HS,CGM_HS,ECM_HS,EBCM_OBD_HS,EBCM_HS
 SG_ SecAxlEstTrq : 1|10@0+ (10,0) [0|10230] "Nm"  EOCM2B_K1_HS,EOCM2A_K1_HS,CGM_HS,ECM_HS,EBCM_OBD_HS,EBCM_HS
 SG_ SAMDVLReqVal : 22|7@0+ (2,0) [0|254] ""  EOCM2B_K1_HS,EOCM2A_K1_HS,CGM_HS,EBCM_OBD_HS,EBCM_HS
 SG_ SAMDVLAtv : 23|1@0+ (1,0) [0|1] ""  EOCM2B_K1_HS,EOCM2A_K1_HS,CGM_HS,EBCM_OBD_HS,EBCM_HS
 SG_ PTTrnsfrCseMd : 31|2@0+ (1,0) [0|3] ""  EOCM2B_K1_HS,EOCM2A_K1_HS,FCM_HS,CGM_HS,TCM_HS,ECM_HS
 SG_ SecAxlCtrlMod : 4|1@0+ (1,0) [0|1] ""  EOCM2B_K1_HS,EOCM2A_K1_HS,CGM_HS,EBCM_OBD_HS,EBCM_HS

BO_ 462 PPEI_Secondary_Axle_Control: 4 EBCM_HS
 SG_ SecAxlLkTqRqCplRqTp : 6|2@0+ (1,0) [0|3] ""  CGM_HS,TCCM_HS
 SG_ SecAxlTrqReqProtVal : 18|11@0+ (1,0) [0|2047] "Counts"  CGM_HS,TCCM_HS
 SG_ SecAxlTrqReqARollCnt : 4|2@0+ (1,0) [0|3] "Counts"  CGM_HS,TCCM_HS
 SG_ SATRCplReqVal : 1|10@0+ (10,0) [0|10230] "Nm"  CGM_HS,TCCM_HS
 SG_ SATRCplReqAtv : 2|1@0+ (1,0) [0|1] ""  CGM_HS,TCCM_HS

BO_ 463 PPEI_Secondary_Axle_General_Info: 3 ECM_HS
 SG_ FourWhlDrvIdReqExtRng : 12|4@0+ (1,0) [0|15] ""  CGM_HS,BCM_HS
 SG_ SecAxlOpMdARC : 5|2@0+ (1,0) [0|3] ""  CGM_HS,ECM_HS
 SG_ FourWhlDrvIndReq : 15|3@0+ (1,0) [0|7] ""  EOCM2B_IMX6_HS,EOCM2A_IMX6_HS,EOCM2B_K1_HS,EOCM2A_K1_HS,CGM_HS,BCM_HS
 SG_ TrnsfrCsRngShfSpdLmt : 23|8@0+ (1,0) [0|255] "km / h"  EOCM2B_IMX6_HS,EOCM2A_IMX6_HS,EOCM2B_K1_HS,EOCM2A_K1_HS,CGM_HS,BCM_HS
 SG_ SecAxlNonEmMalfIO : 7|1@0+ (1,0) [0|1] ""  EOCM2B_IMX6_HS,EOCM2A_IMX6_HS,EOCM2B_K1_HS,EOCM2A_K1_HS,CGM_HS,BCM_HS
 SG_ SecAxlOperMod : 3|4@0+ (1,0) [0|15] ""  EOCM2B_IMX6_HS,EOCM2A_IMX6_HS,ICCM_HS,FCM_HS,EOCM2B_K1_HS,EOCM2A_K1_HS,CGM_HS,BSM_HS,VICM_HS,BCM_HS,TCP_HS,ONSTAR_HS,TCM_HS,ECM_HS,ACC_HS,EOCM_F_HS,EBCM_OBD_HS,EBCM_HS
 SG_ SecAxlTmpInhIO : 6|1@0+ (1,0) [0|1] ""  EOCM2B_IMX6_HS,EOCM2A_IMX6_HS,EOCM2B_K1_HS,EOCM2A_K1_HS,CGM_HS,BCM_HS,TCP_HS,ONSTAR_HS

BO_ 719 PPEI_Rear_Virtual_Bmp_Req_Status: 5 EOCM_F_HS
 SG_ RrVrtlBmpAxlTrqCmdRC : 7|2@0+ (1,0) [0|3] ""  EOCM2B_K1_HS,ECM_HS
 SG_ RrVrtlBmpAxlTrqCmdProtVal : 31|16@0+ (1,0) [0|65535] ""  EOCM2B_K1_HS,ECM_HS
 SG_ RVBATC_AxlTrqRqstAct : 15|1@0+ (1,0) [0|1] ""  EOCM2B_K1_HS,ECM_HS
 SG_ RVBATC_AxlTrqRqst : 14|15@0+ (2,-22534) [-22534|43000] "NM"  EOCM2B_K1_HS,ECM_HS

BO_ 853 Pedestrian_Protection_System_HS: 1 APPS_HS
 SG_ SrvPedtrnProtSysIO : 2|1@0+ (1,0) [0|1] ""  V2V_HS,CGM_HS,TCP_HS,ONSTAR_HS,BCM_HS
 SG_ PedtrnProtSysDisbld : 1|1@0+ (1,0) [0|1] ""  V2V_HS,CGM_HS,TCP_HS,ONSTAR_HS,BCM_HS
 SG_ PedtrnProtSysDpl : 0|1@0+ (1,0) [0|1] ""  V2V_HS,CGM_HS,TCP_HS,ONSTAR_HS,BCM_HS

BO_ 869 CPS_Collision_Preparation_IO_HS: 4 EOCM_F_HS
 SG_ TnDrvGapAdjUnbIO : 4|1@0+ (1,0) [0|1] ""  BCM_HS
 SG_ CPSCA_Resrv3Avail : 25|1@0+ (1,0) [0|1] ""  EOCM2B_K1_HS,BCM_HS
 SG_ CPSCA_Resrv2Avail : 26|1@0+ (1,0) [0|1] ""  EOCM2B_K1_HS,BCM_HS
 SG_ CPSCA_Resrv1Avail : 27|1@0+ (1,0) [0|1] ""  EOCM2B_K1_HS,BCM_HS
 SG_ CPSCA_AlrtBrkStrAvail : 28|1@0+ (1,0) [0|1] ""  EOCM2B_K1_HS,BCM_HS
 SG_ CPSCA_AlrtBrkAvail : 29|1@0+ (1,0) [0|1] ""  EOCM2B_K1_HS,BCM_HS
 SG_ CPSCA_AlrtAvail : 30|1@0+ (1,0) [0|1] ""  EOCM2B_K1_HS,BCM_HS
 SG_ CPSCA_OffAvail : 31|1@0+ (1,0) [0|1] ""  EOCM2B_K1_HS,BCM_HS
 SG_ FwdClnMtgnBrkReqAct : 3|1@0+ (1,0) [0|1] ""  EOCM2B_K1_HS,BCM_HS
 SG_ FCACustStngAvlbl : 23|1@0+ (1,0) [0|1] ""  EOCM2B_K1_HS,BCM_HS
 SG_ FwdClnAlrtCustCrntSetngVal : 12|3@0+ (1,0) [0|7] ""  EOCM2B_K1_HS,BCM_HS
 SG_ GNCustSetngAvlbl : 9|1@0+ (1,0) [0|1] ""  EOCM2B_K1_HS,BCM_HS
 SG_ CPSUnblIO : 8|1@0+ (1,0) [0|1] ""  EOCM2B_K1_HS,BCM_HS
 SG_ ColPrSysStngAvl : 7|1@0+ (1,0) [0|1] ""  EOCM2B_K1_HS,BCM_HS
 SG_ CPSOffIO : 6|1@0+ (1,0) [0|1] ""  EOCM2B_K1_HS,BCM_HS
 SG_ CPSFldIO : 5|1@0+ (1,0) [0|1] ""  EOCM2B_K1_HS,BCM_HS
 SG_ ColPrSysCrntStng : 22|3@0+ (1,0) [0|7] ""  EOCM2B_K1_HS,BCM_HS
 SG_ CPSAlrtOnlIO : 2|1@0+ (1,0) [0|1] ""  EOCM2B_K1_HS,BCM_HS
 SG_ GNCustCrntStngVal : 15|3@0+ (1,0) [0|7] ""  EOCM2B_K1_HS,BCM_HS

BO_ 717 PPEI_Collision_Prep_Req_Status: 5 EOCM_F_HS
 SG_ ColPrSysAxlTrqCmdProtVal : 31|16@0+ (1,0) [0|65535] ""  TCM_HS,EOCM2B_K1_HS,ECM_HS
 SG_ CPSATC_AxlTrqRqstAct : 15|1@0+ (1,0) [0|1] ""  TCM_HS,EOCM2B_K1_HS,ECM_HS
 SG_ CPSATC_AxlTrqRqst : 14|15@0+ (2,-22534) [-22534|43000] "NM"  TCM_HS,EOCM2B_K1_HS,ECM_HS
 SG_ ColPrSysAxlTrqCmdRC : 7|2@0+ (1,0) [0|3] ""  TCM_HS,EOCM2B_K1_HS,ECM_HS

BO_ 568 A_12V_System_Status_HS: 1 VICM_HS
 SG_ a_12VSysVlt : 7|8@0+ (0.125,0) [0|31.875] "volts"  CGM_HS,ICCM_B_HS,ICCM_OBD_HS,ICCM_HS

BO_ 564 Prfrmnc_Trctn_Cntrl_Stat_HS: 5 EBCM_HS
 SG_ AdptDrvrSeatStng : 34|3@0+ (1,0) [0|7] ""  CGM_HS,BCM_HS
 SG_ AdptPsngrSeatStng : 37|3@0+ (1,0) [0|7] ""  CGM_HS,BCM_HS
 SG_ TnDrvTrCtrlOffUnbIO : 7|1@0+ (1,0) [0|1] ""  CGM_HS,BCM_HS
 SG_ TnDrvStblCtrlOffUnbIO : 6|1@0+ (1,0) [0|1] ""  CGM_HS,BCM_HS
 SG_ VehRollAngleV : 15|1@0+ (1,0) [0|1] ""  V2V_HS,CGM_HS,BCM_HS
 SG_ VehRollAngle : 14|7@0+ (0.703125,-45) [-45|44.296875] "deg"  V2V_HS,CGM_HS,BCM_HS
 SG_ VehPitchAngleV : 31|1@0+ (1,0) [0|1] ""  V2V_HS,CGM_HS,BCM_HS
 SG_ VehPitchAngle : 30|7@0+ (0.703125,-45) [-45|44.296875] "deg"  V2V_HS,CGM_HS,BCM_HS
 SG_ RdWhlAngV : 23|1@0+ (1,0) [0|1] ""  V2V_HS,CGM_HS,BCM_HS
 SG_ RdWhlAng : 22|7@0+ (0.703125,-45) [-45|44.296875] "deg"  V2V_HS,CGM_HS,BCM_HS
 SG_ TrlrStabAstActIO : 5|1@0+ (1,0) [0|1] ""  CGM_HS,BCM_HS
 SG_ PerfTrcCrnExStngVal : 4|5@0+ (1,0) [0|31] ""  CGM_HS,BCM_HS,LVMPC_HS

BO_ 313 Body_Information_4_HS: 8 BCM_HS
 SG_ LnchCtrlRelLnLockReqd : 15|1@0+ (1,0) [0|1] ""  CGM_HS,EBCM_OBD_HS,EBCM_HS
 SG_ VehStbEnhmntCurStRq : 47|2@0+ (1,0) [0|3] ""  EBCM_OBD_HS,EBCM_HS,CGM_HS
 SG_ TCSysCurStReq : 23|2@0+ (1,0) [0|3] ""  EBCM_OBD_HS,EBCM_HS,CGM_HS
 SG_ DrvrDrOpenSwVDA : 14|1@0+ (1,0) [0|1] ""  HCP_T_HS,ECM_HS,ICCM_HS,CGM_HS
 SG_ DrDoorOpenSwActV : 12|1@0+ (1,0) [0|1] ""  EOCM2B_IMX6_HS,EOCM2A_IMX6_HS,HCP_T_HS,ECM_HS,ICCM_HS,EOCM2B_K1_HS,EOCM2A_K1_HS,CGM_HS
 SG_ DrDoorOpenSwAct : 11|1@0+ (1,0) [0|1] ""  EOCM2B_IMX6_HS,EOCM2A_IMX6_HS,HCP_T_HS,ECM_HS,ICCM_HS,EOCM2B_K1_HS,EOCM2A_K1_HS,CGM_HS
 SG_ LnchCtrlWhlSlpReq : 55|5@0+ (1,0) [0|31] ""  EOCM2B_IMX6_HS,EOCM2A_IMX6_HS,EOCM2B_K1_HS,EOCM2A_K1_HS,EBCM_OBD_HS,EBCM_HS,CGM_HS
 SG_ LnchCtrlMdReq : 57|2@0+ (1,0) [0|3] ""  EOCM2B_IMX6_HS,EOCM2A_IMX6_HS,EOCM2B_K1_HS,EOCM2A_K1_HS,EBCM_OBD_HS,EBCM_HS,CGM_HS
 SG_ LnchCtrlEngRPMReq : 63|6@0+ (1,0) [0|63] ""  EOCM2B_IMX6_HS,EOCM2A_IMX6_HS,EOCM2B_K1_HS,EOCM2A_K1_HS,EBCM_OBD_HS,EBCM_HS,CGM_HS
 SG_ ExtHlStrAssCsStRq : 50|3@0+ (1,0) [0|7] ""  EOCM2B_IMX6_HS,EOCM2A_IMX6_HS,CGM_HS,EOCM2B_K1_HS,EOCM2A_K1_HS,EBCM_OBD_HS,EBCM_HS
 SG_ DrvStyPerfMdCsStReq : 45|3@0+ (1,0) [0|7] ""  EOCM2B_IMX6_HS,EOCM2A_IMX6_HS,EOCM2B_K1_HS,EOCM2A_K1_HS,CGM_HS,EBCM_OBD_HS,EBCM_HS
 SG_ PsngStPerfMdCsStReq : 42|3@0+ (1,0) [0|7] ""  EOCM2B_IMX6_HS,EOCM2A_IMX6_HS,EOCM2B_K1_HS,EOCM2A_K1_HS,CGM_HS,EBCM_OBD_HS,EBCM_HS
 SG_ DrvrStPerfMdCsStReq : 31|3@0+ (1,0) [0|7] ""  EOCM2B_IMX6_HS,EOCM2A_IMX6_HS,EOCM2B_K1_HS,EOCM2A_K1_HS,CGM_HS,EBCM_OBD_HS,EBCM_HS
 SG_ ACCPerfMdCsStReq : 28|3@0+ (1,0) [0|7] ""  EOCM2B_IMX6_HS,EOCM2A_IMX6_HS,EOCM2B_K1_HS,EOCM2A_K1_HS,CGM_HS,EBCM_OBD_HS,EBCM_HS
 SG_ PrkAstAdvSysAct : 8|1@0+ (1,0) [0|1] ""  EOCM2B_IMX6_HS,EOCM2A_IMX6_HS,ECM_HS,EOCM2B_K1_HS,EOCM2A_K1_HS,EBCM_OBD_HS,EBCM_HS,CGM_HS,ACC_HS
 SG_ SndPerfMdCsStRq : 18|3@0+ (1,0) [0|7] ""  EOCM2B_IMX6_HS,EOCM2A_IMX6_HS,EOCM2B_K1_HS,EOCM2A_K1_HS,CGM_HS,EBCM_OBD_HS,EBCM_HS
 SG_ HptcStVbnStat : 2|2@0+ (1,0) [0|3] ""  EOCM2B_IMX6_HS,EOCM2A_IMX6_HS,EOCM2B_K1_HS,EOCM2A_K1_HS,CGM_HS,ACC_HS
 SG_ ACCSettingType : 10|2@0+ (1,0) [0|3] ""  EOCM2B_IMX6_HS,EOCM2A_IMX6_HS,FCM_HS,EOCM2B_K1_HS,EOCM2A_K1_HS,EOCM_F_HS,CGM_HS,ACC_HS
 SG_ FCABrkPrflReq : 13|1@0+ (1,0) [0|1] ""  EOCM2B_IMX6_HS,EOCM2A_IMX6_HS,EOCM2B_K1_HS,EOCM2A_K1_HS,CGM_HS,EBCM_OBD_HS,EBCM_HS
 SG_ ISA2CCC_ScndCdChr : 36|5@0+ (1,0) [0|31] ""  EOCM2B_IMX6_HS,EOCM2A_IMX6_HS,EOCM2B_K1_HS,EOCM2A_K1_HS,CGM_HS,AHL_AFL_HS
 SG_ ISA2CCC_FrstCdChr : 25|5@0+ (1,0) [0|31] ""  EOCM2B_IMX6_HS,EOCM2A_IMX6_HS,EOCM2B_K1_HS,EOCM2A_K1_HS,CGM_HS,AHL_AFL_HS
 SG_ DispPerfMdCsStRq : 21|3@0+ (1,0) [0|7] ""  EOCM2B_IMX6_HS,EOCM2A_IMX6_HS,EOCM2B_K1_HS,EOCM2A_K1_HS,CGM_HS,EBCM_OBD_HS,EBCM_HS
 SG_ CrshAlrtStPrsnt : 0|1@0+ (1,0) [0|1] ""  EOCM2B_IMX6_HS,EOCM2A_IMX6_HS,EOCM2B_K1_HS,EOCM2A_K1_HS,CGM_HS,EBCM_OBD_HS,EBCM_HS,ACC_HS
 SG_ FwdClnAlrtCustStngReq : 5|3@0+ (1,0) [0|7] ""  EOCM2B_IMX6_HS,EOCM2A_IMX6_HS,EOCM2B_K1_HS,EOCM2A_K1_HS,CGM_HS,EOCM_F_HS,ACC_HS
 SG_ GNCustStngReq : 7|2@0+ (1,0) [0|3] ""  EOCM2B_IMX6_HS,EOCM2A_IMX6_HS,FCM_HS,EOCM2B_K1_HS,EOCM2A_K1_HS,CGM_HS,EOCM_F_HS,ACC_HS

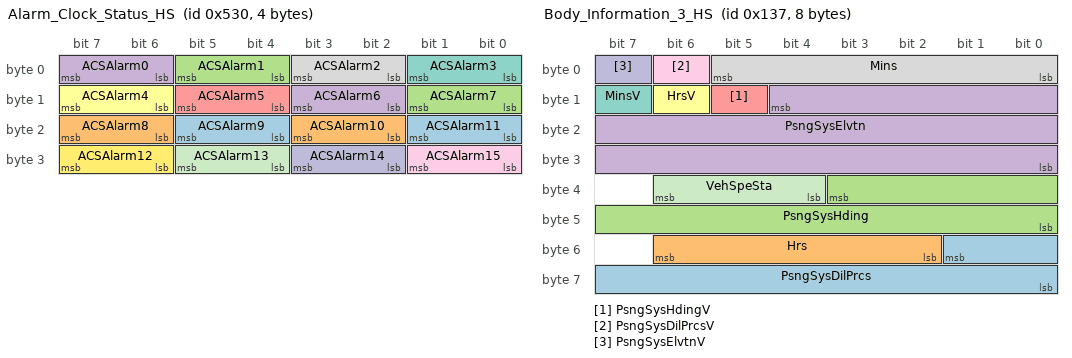
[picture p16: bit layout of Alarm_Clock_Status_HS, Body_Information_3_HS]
BO_ 1328 Alarm_Clock_Status_HS: 4 BCM_HS
 SG_ ACSAlarm9 : 21|2@0+ (1,0) [0|3] ""  CGM_HS,ICCM_B_HS,ICCM_OBD_HS,ICCM_HS,ALC_HS
 SG_ ACSAlarm8 : 23|2@0+ (1,0) [0|3] ""  CGM_HS,ICCM_B_HS,ICCM_OBD_HS,ICCM_HS,ALC_HS
 SG_ ACSAlarm7 : 9|2@0+ (1,0) [0|3] ""  CGM_HS,ICCM_B_HS,ICCM_OBD_HS,ICCM_HS,ALC_HS
 SG_ ACSAlarm6 : 11|2@0+ (1,0) [0|3] ""  CGM_HS,ICCM_B_HS,ICCM_OBD_HS,ICCM_HS,ALC_HS
 SG_ ACSAlarm5 : 13|2@0+ (1,0) [0|3] ""  CGM_HS,ICCM_B_HS,ICCM_OBD_HS,ICCM_HS,ALC_HS
 SG_ ACSAlarm4 : 15|2@0+ (1,0) [0|3] ""  CGM_HS,ICCM_B_HS,ICCM_OBD_HS,ICCM_HS,ALC_HS
 SG_ ACSAlarm3 : 1|2@0+ (1,0) [0|3] ""  CGM_HS,ICCM_B_HS,ICCM_OBD_HS,ICCM_HS,ALC_HS
 SG_ ACSAlarm2 : 3|2@0+ (1,0) [0|3] ""  CGM_HS,ICCM_B_HS,ICCM_OBD_HS,ICCM_HS,ALC_HS
 SG_ ACSAlarm15 : 25|2@0+ (1,0) [0|3] ""  CGM_HS,ICCM_B_HS,ICCM_OBD_HS,ICCM_HS,ALC_HS
 SG_ ACSAlarm14 : 27|2@0+ (1,0) [0|3] ""  CGM_HS,ICCM_B_HS,ICCM_OBD_HS,ICCM_HS,ALC_HS
 SG_ ACSAlarm13 : 29|2@0+ (1,0) [0|3] ""  CGM_HS,ICCM_B_HS,ICCM_OBD_HS,ICCM_HS,ALC_HS
 SG_ ACSAlarm12 : 31|2@0+ (1,0) [0|3] ""  CGM_HS,ICCM_B_HS,ICCM_OBD_HS,ICCM_HS,ALC_HS
 SG_ ACSAlarm11 : 17|2@0+ (1,0) [0|3] ""  CGM_HS,ICCM_B_HS,ICCM_OBD_HS,ICCM_HS,ALC_HS
 SG_ ACSAlarm10 : 19|2@0+ (1,0) [0|3] ""  CGM_HS,ICCM_B_HS,ICCM_OBD_HS,ICCM_HS,ALC_HS
 SG_ ACSAlarm1 : 5|2@0+ (1,0) [0|3] ""  CGM_HS,ICCM_B_HS,ICCM_OBD_HS,ICCM_HS,ALC_HS
 SG_ ACSAlarm0 : 7|2@0+ (1,0) [0|3] ""  CGM_HS,ICCM_B_HS,ICCM_OBD_HS,ICCM_HS,ALC_HS

BO_ 1296 Adaptive_Cruise_Control_Ind_HS: 4 ACC_HS
 SG_ ACCAutoSetSpdStat : 1|2@0+ (1,0) [0|3] ""  EOCM2B_K1_HS,FCM_HS,BCM_HS
 SG_ FwdClnAlrtOffIO : 7|1@0+ (1,0) [0|1] ""  EOCM2B_K1_HS,BCM_HS
 SG_ VADIR_IndLvl : 10|4@0+ (1,0) [0|15] ""  EOCM2B_K1_HS,BCM_HS
 SG_ VADIR_FlwTme : 22|7@0+ (0.1,0) [0|12.7] "s"  EOCM2B_K1_HS,BCM_HS
 SG_ VADIR_FlwDst : 31|8@0+ (1,0) [0|255] "m"  EOCM2B_K1_HS,BCM_HS

BO_ 311 Body_Information_3_HS: 8 BCM_HS
 SG_ PsngSysDilPrcs : 49|10@0+ (0.1,0) [0|102.3] ""  CGM_HS,ACC_HS
 SG_ Hrs : 54|5@0+ (1,0) [0|31] "h"  CGM_HS,ACC_HS
 SG_ PsngSysHding : 35|12@0+ (0.1,0) [0|409.5] "deg"  CGM_HS,ACC_HS
 SG_ PsngSysElvtn : 12|21@0+ (1,-100000) [-100000|1997151] "cm"  CGM_HS,ACC_HS
 SG_ PsngSysHdingV : 13|1@0+ (1,0) [0|1] ""  CGM_HS,ACC_HS
 SG_ HrsV : 14|1@0+ (1,0) [0|1] ""  CGM_HS,ACC_HS
 SG_ MinsV : 15|1@0+ (1,0) [0|1] ""  CGM_HS,ACC_HS
 SG_ Mins : 5|6@0+ (1,0) [0|63] "min"  CGM_HS,ACC_HS
 SG_ PsngSysDilPrcsV : 6|1@0+ (1,0) [0|1] ""  CGM_HS,ACC_HS
 SG_ PsngSysElvtnV : 7|1@0+ (1,0) [0|1] ""  CGM_HS,ACC_HS
 SG_ VehSpeSta : 38|3@0+ (1,0) [0|7] ""  CGM_HS,ACC_HS

BO_ 536 ACC_Drv_Seat_Vib_Req_IO_HS: 5 ACC_HS
 SG_ ACCHptcStVbnRqSeqN : 1|2@0+ (1,0) [0|3] ""  BCM_HS
 SG_ ACCHptcStVbnReq : 7|6@0+ (1,0) [0|63] ""  BCM_HS
 SG_ ShtToPrkBfExtngVehIO : 36|1@0+ (1,0) [0|1] ""  BCM_HS
 SG_ AutoBrkRlsIO : 35|1@0+ (1,0) [0|1] ""  BCM_HS
 SG_ HdUpDsplyUnblIO : 34|1@0+ (1,0) [0|1] ""  BCM_HS
 SG_ FSRACCFrstRsmPrssIO : 33|1@0+ (1,0) [0|1] ""  BCM_HS
 SG_ FrtRdrBlckdIO : 32|1@0+ (1,0) [0|1] ""  BCM_HS

BO_ 570 Fwd_Cln_Alrt_Drv_Seat_Vib_Req_HS: 1 ACC_HS
 SG_ FCAHptcStVbnRqSeqN : 1|2@0+ (1,0) [0|3] ""  BCM_HS
 SG_ FCAHptcStVbnReq : 7|6@0+ (1,0) [0|63] ""  BCM_HS

BO_ 810 GPS_Geographical_Position_HS: 8 BCM_HS
 SG_ PsngSysLongV : 39|1@0+ (1,0) [0|1] ""  CGM_HS,LVMPC_HS,EBCM_OBD_HS,EBCM_HS,ACC_HS
 SG_ PsngSysLong : 38|31@0- (1,0) [-1073741824|1073741823] "ms arc"  CGM_HS,LVMPC_HS,EBCM_OBD_HS,EBCM_HS,ACC_HS
 SG_ PsngSysLatV : 6|1@0+ (1,0) [0|1] ""  CGM_HS,LVMPC_HS,EBCM_OBD_HS,EBCM_HS,ACC_HS
 SG_ PsngSysLat : 5|30@0- (1,0) [-536870912|536870911] "ms arc"  CGM_HS,LVMPC_HS,EBCM_OBD_HS,EBCM_HS,ACC_HS

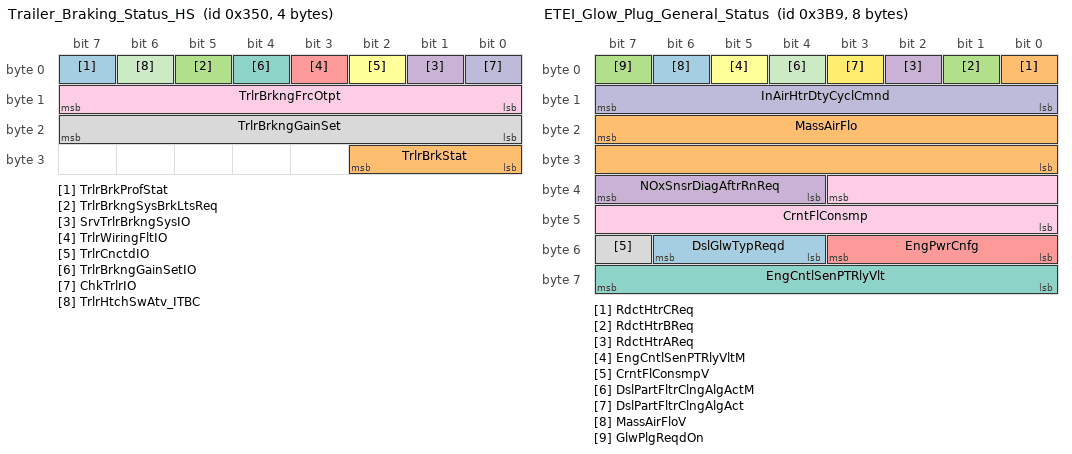
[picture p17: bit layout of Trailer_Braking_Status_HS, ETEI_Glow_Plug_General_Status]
BO_ 848 Trailer_Braking_Status_HS: 4 ICCM_HS
 SG_ TrlrBrkProfStat : 7|1@0+ (1,0) [0|1] ""  CGM_HS,CSM_HS
 SG_ TrlrBrkStat : 26|3@0+ (1,0) [0|7] ""  EOCM2B_K1_HS,EOCM2A_K1_HS,CGM_HS,EBCM_OBD_HS,EBCM_HS
 SG_ TrlrBrkngSysBrkLtsReq : 5|1@0+ (1,0) [0|1] ""  EOCM2B_K1_HS,EOCM2A_K1_HS,CGM_HS,BCM_HS
 SG_ SrvTrlrBrkngSysIO : 1|1@0+ (1,0) [0|1] ""  EOCM2B_K1_HS,EOCM2A_K1_HS,CGM_HS,BCM_HS
 SG_ TrlrWiringFltIO : 3|1@0+ (1,0) [0|1] ""  EOCM2B_K1_HS,EOCM2A_K1_HS,CGM_HS,BCM_HS
 SG_ TrlrCnctdIO : 2|1@0+ (1,0) [0|1] ""  EOCM2B_K1_HS,EOCM2A_K1_HS,CGM_HS,BCM_HS
 SG_ TrlrBrkngGainSetIO : 4|1@0+ (1,0) [0|1] ""  EOCM2B_K1_HS,EOCM2A_K1_HS,CGM_HS,BCM_HS
 SG_ TrlrBrkngGainSet : 23|8@0+ (0.392157,0) [0|100.000035] "%"  EOCM2B_K1_HS,EOCM2A_K1_HS,CGM_HS,EBCM_OBD_HS,EBCM_HS,BCM_HS
 SG_ TrlrBrkngFrcOtpt : 15|8@0+ (0.392157,0) [0|100.000035] "%"  EOCM2B_K1_HS,EOCM2A_K1_HS,CGM_HS,EBCM_OBD_HS,EBCM_HS,BCM_HS
 SG_ ChkTrlrIO : 0|1@0+ (1,0) [0|1] ""  EOCM2B_K1_HS,EOCM2A_K1_HS,CGM_HS,BCM_HS
 SG_ TrlrHtchSwAtv_ITBC : 6|1@0+ (1,0) [0|1] ""  FCM_HS,EOCM2B_K1_HS,EOCM2A_K1_HS,CGM_HS,EOCM_F_HS,ALC_HS,SADS_HS,BCM_HS

BO_ 953 ETEI_Glow_Plug_General_Status: 8 ECM_HS
 SG_ DslGlwTypReqd : 54|3@0+ (1,0) [0|7] ""  CGM_HS,GPCM_HS
 SG_ RdctHtrCReq : 0|1@0+ (1,0) [0|1] ""  CGM_HS,GPCM_HS
 SG_ RdctHtrBReq : 1|1@0+ (1,0) [0|1] ""  CGM_HS,GPCM_HS
 SG_ RdctHtrAReq : 2|1@0+ (1,0) [0|1] ""  CGM_HS,GPCM_HS
 SG_ EngPwrCnfg : 51|4@0+ (1,0) [0|15] ""  CGM_HS,GPCM_HS
 SG_ EngCntlSenPTRlyVltM : 5|1@0+ (1,0) [0|1] ""  CGM_HS,GPCM_HS
 SG_ EngCntlSenPTRlyVlt : 63|8@0+ (0.1,0) [0|25.5] "volts"  CGM_HS,GPCM_HS
 SG_ CrntFlConsmpV : 55|1@0+ (1,0) [0|1] ""  CGM_HS,GPCM_HS
 SG_ CrntFlConsmp : 35|12@0+ (0.05,0) [0|204.75] "mm3/stk"  CGM_HS,GPCM_HS
 SG_ InAirHtrDtyCyclCmnd : 15|8@0+ (0.392157,0) [0|100.000035] "%"  CGM_HS,GPCM_HS
 SG_ DslPartFltrClngAlgActM : 4|1@0+ (1,0) [0|1] ""  CGM_HS,GPCM_HS
 SG_ DslPartFltrClngAlgAct : 3|1@0+ (1,0) [0|1] ""  CGM_HS,GPCM_HS
 SG_ MassAirFloV : 6|1@0+ (1,0) [0|1] ""  CGM_HS,GPCM_HS
 SG_ MassAirFlo : 23|16@0+ (0.01,0) [0|655.35] "grams/s"  CGM_HS,GPCM_HS
 SG_ GlwPlgReqdOn : 7|1@0+ (1,0) [0|1] ""  CGM_HS,GPCM_HS
 SG_ NOxSnsrDiagAftrRnReq : 39|4@0+ (20,0) [0|300] "Sec"  CGM_HS,GPCM_HS

BO_ 510 PPEI_Brake_Pressure_Sensor_Data: 8 EBCM_HS
 SG_ BPSUD_MsCyPrSnsSUpVal : 17|10@0+ (1,0) [0|1023] ""  CGM_HS,EOCM2B_K1_HS,EOCM2A_K1_HS,HCP_B_HS
 SG_ BPSUD_MsCyPrSns2UpVal : 11|10@0+ (1,0) [0|1023] ""  CGM_HS,EOCM2B_K1_HS,EOCM2A_K1_HS,HCP_B_HS
 SG_ BPSUD_MsCyPrSns1UpVal : 5|10@0+ (1,0) [0|1023] ""  CGM_HS,EOCM2B_K1_HS,EOCM2A_K1_HS,HCP_B_HS
 SG_ BrkPresSnsrDataChksm : 50|11@0+ (1,0) [0|2047] ""  CGM_HS,EOCM2B_K1_HS,EOCM2A_K1_HS,HCP_B_HS
 SG_ BrkPresSnsrDataARC : 55|2@0+ (1,0) [0|3] ""  CGM_HS,EOCM2B_K1_HS,EOCM2A_K1_HS,HCP_B_HS

BO_ 711 PPEI_Hyb_Redundant_Batt_Data2: 6 VITM_OBD_HS
 SG_ RdVltCrntTmpModInitStat : 0|1@0+ (1,0) [0|1] ""  CGM_HS,VICM_HS
 SG_ RdHVltBatPckVltV : 2|1@0+ (1,0) [0|1] ""  CGM_HS,VICM_HS
 SG_ RdHVltBatPckVltM : 1|1@0+ (1,0) [0|1] ""  CGM_HS,VICM_HS
 SG_ RdHVltBatPckVlt : 31|12@0+ (0.125,0) [0|511.875] "V"  CGM_HS,VICM_HS
 SG_ RdHVltBatPckCrntV : 14|1@0+ (1,0) [0|1] ""  CGM_HS,VICM_HS
 SG_ RdHVltBatPckCrntM : 13|1@0+ (1,0) [0|1] ""  CGM_HS,VICM_HS
 SG_ RdHVltBatPckCrnt : 12|13@0- (0.15,0) [-614.4|614.25] "A"  CGM_HS,VICM_HS
 SG_ RdntHVBatClOvrVltTstAct : 3|1@0+ (1,0) [0|1] ""  CGM_HS,VICM_HS

BO_ 1011 PPEI_IBS_Battery_Status_3: 6 ECM_HS
 SG_ BatVltHiResV : 39|1@0+ (1,0) [0|1] ""  CGM_HS,EOCM2B_K1_HS,BCM_HS,EOCM2A_K1_HS
 SG_ BatVltHiRes : 38|15@0+ (0.001,0) [0|32.767] "volts"  CGM_HS,EOCM2B_K1_HS,BCM_HS,EOCM2A_K1_HS
 SG_ BatCrntExtRngV : 14|1@0+ (1,0) [0|1] ""  CGM_HS,EOCM2B_K1_HS,BCM_HS,EOCM2A_K1_HS
 SG_ BatCrntExtRng : 13|22@0+ (0.001,-2097.152) [-2097.152|2097.151] "amps"  CGM_HS,EOCM2B_K1_HS,BCM_HS,EOCM2A_K1_HS
 SG_ BatSnsrlntFlt : 5|1@0+ (1,0) [0|1] ""  CGM_HS,EOCM2B_K1_HS,BCM_HS,EOCM2A_K1_HS
 SG_ BatCrntExtRngM : 6|1@0+ (1,0) [0|1] ""  CGM_HS,EOCM2B_K1_HS,BCM_HS,EOCM2A_K1_HS
 SG_ BatVltHiResM : 7|1@0+ (1,0) [0|1] ""  CGM_HS,EOCM2B_K1_HS,BCM_HS,EOCM2A_K1_HS

BO_ 304 Content_Theft_Sensor_Status_HS: 1 BCM_HS
 SG_ PedFrndlyAlrtCsStReq : 5|3@0+ (1,0) [0|7] ""  CGM_HS,PFAF_HS
 SG_ AlrmStat : 2|3@0+ (1,0) [0|7] ""  CGM_HS,VLBS_HS,ICCM_B_HS,ICCM_OBD_HS,ICCM_HS,ALC_HS

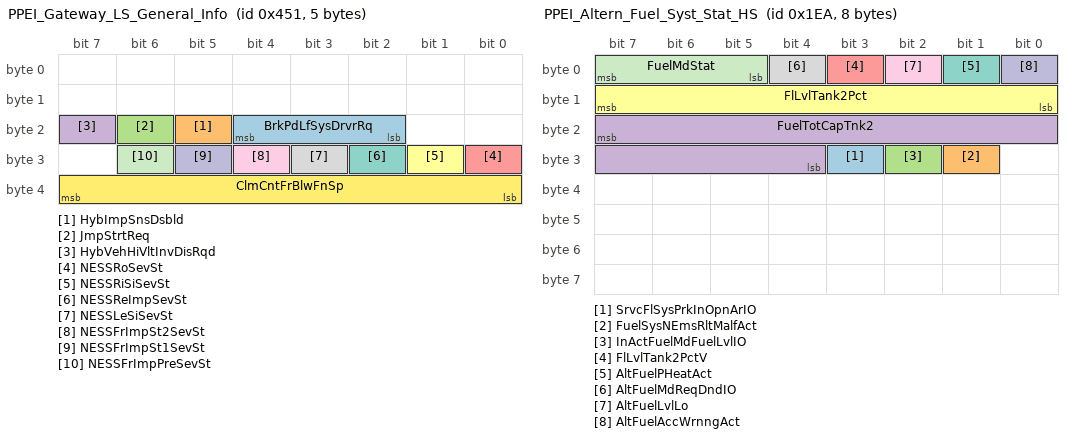
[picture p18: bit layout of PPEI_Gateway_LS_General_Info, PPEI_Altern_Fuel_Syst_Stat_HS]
BO_ 1105 PPEI_Gateway_LS_General_Info: 5 BCM_HS
 SG_ BrkPdLfSysDrvrRq : 20|3@0+ (1,0) [0|7] ""  CGM_HS,EBCM_OBD_HS,EBCM_HS
 SG_ HybImpSnsDsbld : 21|1@0+ (1,0) [0|1] ""  CGM_HS,BCP_HS,HCP_B_HS
 SG_ JmpStrtReq : 22|1@0+ (1,0) [0|1] ""  CGM_HS,BSM_HS,BCP_HS
 SG_ HybVehHiVltInvDisRqd : 23|1@0+ (1,0) [0|1] ""  CGM_HS,HCP_B_HS,BCP_HS
 SG_ NESSRoSevSt : 24|1@0+ (1,0) [0|1] ""  CGM_HS,HCP_B_HS,ECM_HS,BCP_HS
 SG_ NESSRiSiSevSt : 25|1@0+ (1,0) [0|1] ""  CGM_HS,HCP_B_HS,ECM_HS,BCP_HS
 SG_ NESSReImpSevSt : 26|1@0+ (1,0) [0|1] ""  CGM_HS,HCP_B_HS,ECM_HS,BCP_HS
 SG_ NESSLeSiSevSt : 27|1@0+ (1,0) [0|1] ""  CGM_HS,HCP_B_HS,ECM_HS,BCP_HS
 SG_ NESSFrImpSt2SevSt : 28|1@0+ (1,0) [0|1] ""  CGM_HS,HCP_B_HS,ECM_HS,BCP_HS
 SG_ NESSFrImpSt1SevSt : 29|1@0+ (1,0) [0|1] ""  CGM_HS,HCP_B_HS,ECM_HS,BCP_HS
 SG_ NESSFrImpPreSevSt : 30|1@0+ (1,0) [0|1] ""  CGM_HS,HCP_B_HS,ECM_HS,BCP_HS
 SG_ ClmCntFrBlwFnSp : 39|8@0+ (0.392157,0) [0|100.000035] "%"  CGM_HS,BCP_HS,EBCM_OBD_HS,EBCM_HS

BO_ 1005 Vehicle_Limit_Speed_Control_Cmd: 6 ONSTAR_HS
 SG_ EnhSvVehTopSpdLmR : 7|2@0+ (1,0) [0|3] ""  ECM_HS
 SG_ EnhSvVTpSpdLVlARC : 5|2@0+ (1,0) [0|3] ""  ECM_HS
 SG_ EnhSvVehTopSpdLimP : 15|32@0+ (1,0) [0|-1] ""  ECM_HS
 SG_ EnhSvVehTopSpdLim : 47|8@0+ (2,0) [0|510] "km / h"  ECM_HS

BO_ 688 Starter_Generator_Status_3: 5 BCP_HS
 SG_ StrtrGenSpdV : 39|1@0+ (1,0) [0|1] ""  CGM_HS,ECM_HS,EBCM_OBD_HS,EBCM_HS
 SG_ StrtrGenSpd : 21|14@0+ (1,0) [0|16383] "rpm"  CGM_HS,ECM_HS,EBCM_OBD_HS,EBCM_HS

BO_ 993 PPEI_Engine_BAS_Status_1: 7 BCP_HS
 SG_ CstmrUsblSOCV : 6|1@0+ (1,0) [0|1] ""  CGM_HS,BCM_HS
 SG_ CstmrUsblSOC : 55|8@0+ (0.39216,0) [0|100.0008] "%"  CGM_HS,BCM_HS
 SG_ InstDrvEff : 47|8@0- (0.78125,0) [-100|99.21875] "%"  CGM_HS,BCM_HS
 SG_ PwrPckAirInTempFlt : 39|8@0+ (1,-40) [-40|215] "deg C"  CGM_HS,BCM_HS
 SG_ PwrPkFnSpd : 31|8@0+ (0.392157,0) [0|100.000035] "%"  CGM_HS,BCM_HS
 SG_ JmpStrtStat : 18|3@0+ (1,0) [0|7] ""  CGM_HS,BCM_HS
 SG_ HybVehHiVltSysDisbld : 2|1@0+ (1,0) [0|1] ""  CGM_HS,TCP_HS,ONSTAR_HS
 SG_ SvcHybridSysIO : 5|1@0+ (1,0) [0|1] ""  CGM_HS,BCM_HS
 SG_ HybMdDisp : 22|4@0+ (1,0) [0|15] ""  CGM_HS,BCM_HS

BO_ 490 PPEI_Altern_Fuel_Syst_Stat_HS: 8 ECM_HS
 SG_ SrvcFlSysPrkInOpnArIO : 27|1@0+ (1,0) [0|1] ""  CGM_HS,BCM_HS
 SG_ FuelSysNEmsRltMalfAct : 25|1@0+ (1,0) [0|1] ""  CGM_HS,BCM_HS
 SG_ InActFuelMdFuelLvlIO : 26|1@0+ (1,0) [0|1] ""  CGM_HS,BCM_HS
 SG_ FuelTotCapTnk2 : 23|12@0+ (0.125,0) [0|511.875] "liters"  CGM_HS,BCM_HS
 SG_ FlLvlTank2PctV : 3|1@0+ (1,0) [0|1] ""  CGM_HS,BCM_HS
 SG_ FlLvlTank2Pct : 15|8@0+ (0.392157,0) [0|100.000035] "%"  CGM_HS,BCM_HS
 SG_ AltFuelPHeatAct : 1|1@0+ (1,0) [0|1] ""  CGM_HS,ECM_HS,BCM_HS
 SG_ AltFuelMdReqDndIO : 4|1@0+ (1,0) [0|1] ""  CGM_HS,BCM_HS
 SG_ AltFuelLvlLo : 2|1@0+ (1,0) [0|1] ""  CGM_HS,BCM_HS,ECM_HS
 SG_ AltFuelAccWrnngAct : 0|1@0+ (1,0) [0|1] ""  CGM_HS,BCM_HS
 SG_ FuelMdStat : 7|3@0+ (1,0) [0|7] ""  CGM_HS,BCM_HS,ECM_HS

BO_ 431 PTEI_Trans_General_Status_2: 8 TCM_HS
 SG_ TrnsInpCltchStatV : 39|1@0+ (1,0) [0|1] ""  CGM_HS,ECM_HS
 SG_ TransCrnkPermsnStatV : 23|1@0+ (1,0) [0|1] ""  CGM_HS,ECM_HS
 SG_ TransVehTopSpdLim : 63|8@0+ (2,0) [0|510] "km / h"  CGM_HS,ECM_HS
 SG_ TransMinVoltReq : 55|8@0+ (0.07843,0) [0|19.99965] "volts"  CGM_HS,ECM_HS
 SG_ TDslPrtFltrIdlRgtnMdAtv : 6|1@0+ (1,0) [0|1] ""  CGM_HS,ECM_HS
 SG_ DrvlneTrqStabStat : 38|3@0+ (1,0) [0|7] ""  CGM_HS,ECM_HS
 SG_ TrnsTrqCnvCltCmdMdF : 19|1@0+ (1,0) [0|1] ""  CGM_HS,ECM_HS
 SG_ AutoTransGrSftDirectFl : 16|1@0+ (1,0) [0|1] ""  CGM_HS,ECM_HS
 SG_ AutoTransGrSftDirect : 18|2@0+ (1,0) [0|3] ""  CGM_HS,ECM_HS
 SG_ TrnsTrqCnvCltCmndMd : 22|3@0+ (1,0) [0|7] ""  CGM_HS,ECM_HS
 SG_ TrnsTrqCnvCltDsrSlp : 35|12@0- (1,0) [-2048|2047] "rpm"  CGM_HS,ECM_HS
 SG_ TrnsStWntrMdOvrd : 25|2@0+ (1,0) [0|3] ""  CGM_HS,ECM_HS
 SG_ TrnsStTwHaulMdOvrd : 27|2@0+ (1,0) [0|3] ""  CGM_HS,ECM_HS
 SG_ TrnsStSprtMdOvrd : 29|2@0+ (1,0) [0|3] ""  CGM_HS,ECM_HS
 SG_ TrnsStEconMdOvrd : 31|2@0+ (1,0) [0|3] ""  CGM_HS,ECM_HS
 SG_ TrnsInpCltchStat : 2|3@0+ (1,0) [0|7] ""  CGM_HS,ECM_HS
 SG_ TrnsAntcptdCrpTrqRRnV : 7|1@0+ (1,0) [0|1] ""  CGM_HS,ECM_HS
 SG_ TrnsAntcptdCrpTrqRRn : 15|8@0+ (0.5,0) [0|127.5] "Nm"  CGM_HS,ECM_HS
 SG_ TrnCltAdpAtv : 3|1@0+ (1,0) [0|1] ""  CGM_HS,ECM_HS
 SG_ TransCrnkPermsnStat : 5|1@0+ (1,0) [0|1] ""  CGM_HS,ECM_HS
 SG_ WrmUpShftPtrn : 4|1@0+ (1,0) [0|1] ""  CGM_HS,ECM_HS

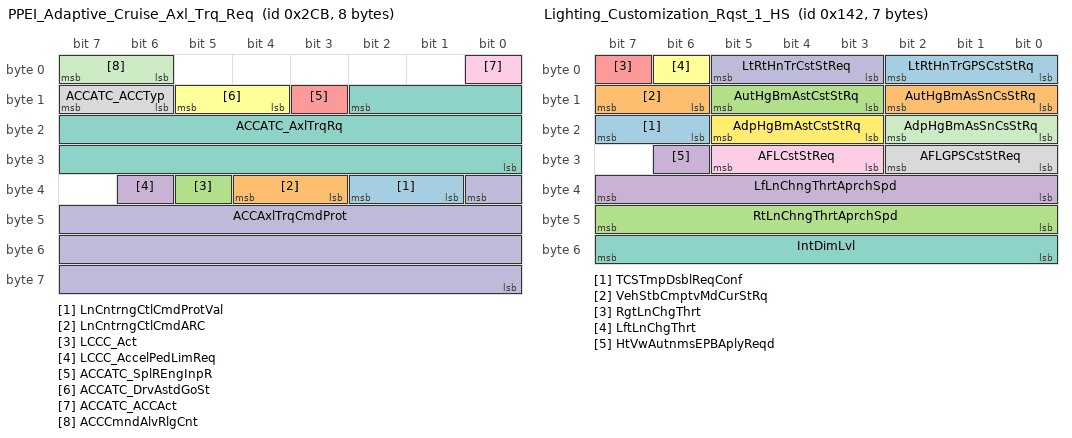
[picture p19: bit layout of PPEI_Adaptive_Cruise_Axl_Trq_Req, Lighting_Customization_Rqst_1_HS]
BO_ 715 PPEI_Adaptive_Cruise_Axl_Trq_Req: 8 ACC_HS
 SG_ LnCntrngCtlCmdProtVal : 34|2@0+ (1,0) [0|3] ""  ECM_HS,EOCM2B_K1_HS,ESCM_SP_HS
 SG_ LnCntrngCtlCmdARC : 36|2@0+ (1,0) [0|3] ""  ECM_HS,EOCM2B_K1_HS,ESCM_SP_HS
 SG_ LCCC_Act : 37|1@0+ (1,0) [0|1] ""  ECM_HS,EOCM2B_K1_HS,ESCM_SP_HS
 SG_ LCCC_AccelPedLimReq : 38|1@0+ (1,0) [0|1] ""  ECM_HS,EOCM2B_K1_HS,ESCM_SP_HS
 SG_ ACCATC_SplREngInpR : 11|1@0+ (1,0) [0|1] ""  BSM_HS,VICM_HS,HCP_B_HS,HCP_T_HS,HCP_HS,EOCM2B_K1_HS,BCP_HS,ECM_HS
 SG_ ACCATC_DrvAstdGoSt : 13|2@0+ (1,0) [0|3] ""  BSM_HS,VICM_HS,HCP_B_HS,HCP_T_HS,HCP_HS,EOCM2B_K1_HS,BCP_HS,ECM_HS
 SG_ ACCATC_AxlTrqRq : 10|19@0+ (0.125,-22534) [-22534|43001.875] "Nm"  BSM_HS,VICM_HS,HCP_B_HS,HCP_T_HS,HCP_HS,EOCM2B_K1_HS,BCP_HS,ECM_HS
 SG_ ACCATC_ACCTyp : 15|2@0+ (1,0) [0|3] ""  BSM_HS,VICM_HS,HCP_B_HS,HCP_T_HS,HCP_HS,EOCM2B_K1_HS,BCP_HS,ECM_HS
 SG_ ACCATC_ACCAct : 0|1@0+ (1,0) [0|1] ""  BSM_HS,VICM_HS,HCP_B_HS,HCP_T_HS,HCP_HS,EOCM2B_K1_HS,BCP_HS,ECM_HS
 SG_ ACCAxlTrqCmdProt : 32|25@0+ (1,0) [0|33554431] ""  EOCM2B_K1_HS,ECM_HS
 SG_ ACCCmndAlvRlgCnt : 7|2@0+ (1,0) [0|3] ""  EOCM2B_K1_HS,ECM_HS

BO_ 1267 PPEI_Powertrain_Config_Data_2: 1 ECM_HS
 SG_ VehMassNom : 7|8@0+ (20,500) [500|5600] "kg"  EOCM2B_K1_HS,EOCM2A_K1_HS,CGM_HS,EOCM_F_HS,ACC_HS,FCM_HS

BO_ 453 PPEI_Driver_Intnd_Axle_Torq_Stat: 6 ECM_HS
 SG_ DrvIntndAxlTrqV : 7|1@0+ (1,0) [0|1] ""  EOCM2B_K2_HS,EOCM2A_K2_HS,EOCM2B_K1_HS,CGM_HS,EOCM2A_K1_HS,FCM_HS,ICCM_B_HS,ICCM_OBD_HS,ICCM_HS,EBCM_OBD_HS,EBCM_HS,BSM_HS,VICM_HS,EOCM_F_HS,ACC_HS
 SG_ DrvIntndAxlTrqMinV : 23|1@0+ (1,0) [0|1] ""  EOCM2B_K2_HS,EOCM2A_K2_HS,EOCM2B_K1_HS,CGM_HS,EOCM2A_K1_HS,FCM_HS,EOCM_F_HS,ACC_HS
 SG_ DrvIntndAxlTrqMin : 22|15@0+ (2,-22534) [-22534|43000] "Nm"  EOCM2B_K2_HS,EOCM2A_K2_HS,HCP_T_HS,HCP_HS,EOCM2B_K1_HS,CGM_HS,EOCM2A_K1_HS,FCM_HS,HCP_B_HS,EOCM_F_HS,ACC_HS
 SG_ DrvIntndAxlTrqMaxV : 39|1@0+ (1,0) [0|1] ""  EOCM2B_K2_HS,EOCM2A_K2_HS,EOCM2B_K1_HS,CGM_HS,EOCM2A_K1_HS,FCM_HS,EOCM_F_HS,ACC_HS
 SG_ DrvIntndAxlTrqMax : 38|15@0+ (2,-22534) [-22534|43000] "Nm"  EOCM2B_K2_HS,EOCM2A_K2_HS,EOCM2B_K1_HS,CGM_HS,EOCM2A_K1_HS,FCM_HS,EOCM_F_HS,ACC_HS
 SG_ DrvIntndAxlTrq : 6|15@0+ (2,-22534) [-22534|43000] "Nm"  EOCM2B_K2_HS,EOCM2A_K2_HS,EOCM2B_K1_HS,CGM_HS,EOCM2A_K1_HS,FCM_HS,ICCM_B_HS,ICCM_OBD_HS,ICCM_HS,EBCM_OBD_HS,EBCM_HS,BSM_HS,VICM_HS,EOCM_F_HS,ACC_HS

BO_ 452 PPEI_Torque_Request_Status: 8 ECM_HS
 SG_ FSpRgACCSwADdPVal : 50|2@0+ (1,0) [0|3] ""  EOCM2B_K2_HS,EOCM2A_K2_HS,EOCM2B_K1_HS,EOCM2A_K1_HS,CGM_HS,EBCM_OBD_HS,EBCM_HS
 SG_ FSpRgACCSwADdARC : 6|2@0+ (1,0) [0|3] ""  EOCM2B_K2_HS,EOCM2A_K2_HS,EOCM2B_K1_HS,EOCM2A_K1_HS,CGM_HS,EBCM_OBD_HS,EBCM_HS
 SG_ FSpRgACCSwADd : 7|1@0+ (1,0) [0|1] ""  EOCM2B_K2_HS,EOCM2A_K2_HS,EOCM2B_K1_HS,EOCM2A_K1_HS,CGM_HS,EBCM_OBD_HS,EBCM_HS,ACC_HS
 SG_ AutBrkAccActPsStRC : 34|2@0+ (1,0) [0|3] ""  EOCM2B_K2_HS,EOCM2A_K2_HS,EOCM2B_K1_HS,EOCM2A_K1_HS,CGM_HS,FCM_HS,EPB_HS,EOCM_F_HS,ACC_HS,EBCM_OBD_HS,EBCM_HS
 SG_ AutBrkAccActPsStPVal : 48|9@0+ (1,0) [0|511] ""  EOCM2B_K2_HS,EOCM2A_K2_HS,EOCM2B_K1_HS,EOCM2A_K1_HS,CGM_HS,FCM_HS,EPB_HS,EOCM_F_HS,ACC_HS,EBCM_OBD_HS,EBCM_HS
 SG_ ABAAPS_AccPos : 47|8@0+ (0.392157,0) [0|100.000035] "%"  EOCM2B_K2_HS,EOCM2A_K2_HS,EOCM2B_K1_HS,EOCM2A_K1_HS,CGM_HS,FCM_HS,EPB_HS,EBCM_OBD_HS,EBCM_HS,ACC_HS,EOCM_F_HS
 SG_ ABAAPS_AccPosV : 32|1@0+ (1,0) [0|1] ""  EOCM2B_K2_HS,EOCM2A_K2_HS,EOCM2B_K1_HS,EOCM2A_K1_HS,CGM_HS,FCM_HS,EPB_HS,EBCM_OBD_HS,EBCM_HS,ACC_HS,EOCM_F_HS
 SG_ ACCATCS_LmtgStat : 12|2@0+ (1,0) [0|3] ""  EOCM2B_K2_HS,EOCM2A_K2_HS,FCM_HS,EOCM2B_K1_HS,EOCM2A_K1_HS,HCP_T_HS,HCP_HS,HCP_B_HS,BCP_HS,CGM_HS,EOCM_F_HS,ACC_HS
 SG_ ACCATCS_RqStat : 15|3@0+ (1,0) [0|7] ""  EOCM2B_K2_HS,EOCM2A_K2_HS,FCM_HS,EOCM2B_K1_HS,EOCM2A_K1_HS,HCP_T_HS,HCP_HS,HCP_B_HS,BCP_HS,CGM_HS,EOCM_F_HS,ACC_HS
 SG_ RdLdNomAxlTrq : 10|19@0+ (0.125,-22534) [-22534|43001.875] "Nm"  EOCM2B_K2_HS,EOCM2A_K2_HS,FCM_HS,CSM_HS,HMIM_HS,EOCM2B_K1_HS,EOCM2A_K1_HS,CGM_HS,EOCM_F_HS,ACC_HS
 SG_ AccPdlOvrrdAtvProtVal : 1|2@0+ (1,0) [0|3] ""  EOCM2B_K2_HS,EOCM2A_K2_HS,TCM_HS,EOCM2B_K1_HS,EOCM2A_K1_HS,CGM_HS,FCM_HS,EOCM_F_HS,EBCM_OBD_HS,EBCM_HS,ACC_HS,PTO_HS
 SG_ AccPdlOvrrdAtvARC : 3|2@0+ (1,0) [0|3] ""  EOCM2B_K2_HS,EOCM2A_K2_HS,TCM_HS,EOCM2B_K1_HS,EOCM2A_K1_HS,CGM_HS,FCM_HS,EOCM_F_HS,EBCM_OBD_HS,EBCM_HS,ACC_HS,PTO_HS
 SG_ AccPdlOvrrdAtv : 4|1@0+ (1,0) [0|1] ""  EOCM2B_K2_HS,EOCM2A_K2_HS,TCM_HS,EOCM2B_K1_HS,EOCM2A_K1_HS,CGM_HS,FCM_HS,BCM_HS,EOCM_F_HS,EBCM_OBD_HS,EBCM_HS,ACC_HS,PTO_HS
 SG_ CPSATCS_ReqStatus : 37|3@0+ (1,0) [0|7] ""  EOCM2B_K2_HS,EOCM2A_K2_HS,EOCM2B_K1_HS,EOCM2A_K1_HS,CGM_HS,FCM_HS,ACC_HS,EOCM_F_HS
 SG_ CPSATCS_LmtngStatus : 39|2@0+ (1,0) [0|3] ""  EOCM2B_K2_HS,EOCM2A_K2_HS,EOCM2B_K1_HS,EOCM2A_K1_HS,CGM_HS,FCM_HS,ACC_HS,EOCM_F_HS
 SG_ RVBATCS_ReqStat : 53|3@0+ (1,0) [0|7] ""  EOCM2B_K2_HS,EOCM2A_K2_HS,EOCM2B_K1_HS,EOCM2A_K1_HS,CGM_HS,EOCM_F_HS
 SG_ RVBATCS_LmtngStat : 55|2@0+ (1,0) [0|3] ""  EOCM2B_K2_HS,EOCM2A_K2_HS,EOCM2B_K1_HS,EOCM2A_K1_HS,CGM_HS,EOCM_F_HS

BO_ 1905 DTC_Triggered_771: 7 EBOOST_OBD_HS
 SG_ DTCI_DTCFaultType_771 : 55|8@0+ (1,0) [0|255] ""  CGM_HS,CSM_HS,HMIM_HS,TCP_HS,VLBS_HS,ONSTAR_HS
 SG_ DTCI_CodeSupported_771 : 40|1@0+ (1,0) [0|1] ""  CGM_HS,CSM_HS,HMIM_HS,TCP_HS,VLBS_HS,ONSTAR_HS
 SG_ DTCI_CurrentStatus_771 : 41|1@0+ (1,0) [0|1] ""  CGM_HS,CSM_HS,HMIM_HS,TCP_HS,VLBS_HS,ONSTAR_HS
 SG_ DTCI_TstNPsdCdClrdSt_771 : 42|1@0+ (1,0) [0|1] ""  CGM_HS,CSM_HS,HMIM_HS,TCP_HS,VLBS_HS,ONSTAR_HS
 SG_ DTCI_TstFldCdClrdStat_771 : 43|1@0+ (1,0) [0|1] ""  CGM_HS,CSM_HS,HMIM_HS,TCP_HS,VLBS_HS,ONSTAR_HS
 SG_ DTCI_HistStat_771 : 44|1@0+ (1,0) [0|1] ""  CGM_HS,CSM_HS,HMIM_HS,TCP_HS,VLBS_HS,ONSTAR_HS
 SG_ DTCI_TstNPsdPwrUpSt_771 : 45|1@0+ (1,0) [0|1] ""  CGM_HS,CSM_HS,HMIM_HS,TCP_HS,VLBS_HS,ONSTAR_HS
 SG_ DTCI_TstFldPwrUpSt_771 : 46|1@0+ (1,0) [0|1] ""  CGM_HS,CSM_HS,HMIM_HS,TCP_HS,VLBS_HS,ONSTAR_HS
 SG_ DTCI_WrnIndRqdSt_771 : 47|1@0+ (1,0) [0|1] ""  CGM_HS,CSM_HS,HMIM_HS,TCP_HS,VLBS_HS,ONSTAR_HS
 SG_ DTCI_DTCFailType_771 : 39|8@0+ (1,0) [0|255] ""  CGM_HS,CSM_HS,HMIM_HS,TCP_HS,VLBS_HS,ONSTAR_HS
 SG_ DTCI_DTCNumber_771 : 23|16@0+ (1,0) [0|65535] ""  CGM_HS,CSM_HS,HMIM_HS,TCP_HS,VLBS_HS,ONSTAR_HS
 SG_ DTCI_DTCSource_771 : 15|8@0+ (1,0) [0|255] ""  CGM_HS,CSM_HS,HMIM_HS,TCP_HS,VLBS_HS,ONSTAR_HS
 SG_ DTCI_DTCTriggered_771 : 0|1@0+ (1,0) [0|1] ""  CGM_HS,CSM_HS,HMIM_HS,TCP_HS,VLBS_HS,ONSTAR_HS
 SG_ DTCIUnused7_771 : 1|1@0+ (1,0) [0|1] ""  CGM_HS,CSM_HS,HMIM_HS,TCP_HS,VLBS_HS,ONSTAR_HS
 SG_ DTCIUnused6_771 : 2|1@0+ (1,0) [0|1] ""  CGM_HS,CSM_HS,HMIM_HS,TCP_HS,VLBS_HS,ONSTAR_HS
 SG_ DTCIUnused5_771 : 3|1@0+ (1,0) [0|1] ""  CGM_HS,CSM_HS,HMIM_HS,TCP_HS,VLBS_HS,ONSTAR_HS
 SG_ DTCIUnused4_771 : 4|1@0+ (1,0) [0|1] ""  CGM_HS,CSM_HS,HMIM_HS,TCP_HS,VLBS_HS,ONSTAR_HS
 SG_ DTCIUnused3_771 : 5|1@0+ (1,0) [0|1] ""  CGM_HS,CSM_HS,HMIM_HS,TCP_HS,VLBS_HS,ONSTAR_HS
 SG_ DTCIUnused2_771 : 6|1@0+ (1,0) [0|1] ""  CGM_HS,CSM_HS,HMIM_HS,TCP_HS,VLBS_HS,ONSTAR_HS
 SG_ DTCIUnused1_771 : 7|1@0+ (1,0) [0|1] ""  CGM_HS,CSM_HS,HMIM_HS,TCP_HS,VLBS_HS,ONSTAR_HS

BO_ 1935 DTC_Triggered_78F: 7 Dummy_HS
 SG_ DTCI_DTCSource_78F : 15|8@0+ (1,0) [0|255] ""  CGM_HS,CSM_HS,HMIM_HS,TCP_HS,VLBS_HS,ONSTAR_HS
 SG_ DTCI_DTCTriggered_78F : 0|1@0+ (1,0) [0|1] ""  CGM_HS,CSM_HS,HMIM_HS,TCP_HS,VLBS_HS,ONSTAR_HS
 SG_ DTCIUnused1_78F : 7|1@0+ (1,0) [0|1] ""  CGM_HS,CSM_HS,HMIM_HS,TCP_HS,VLBS_HS,ONSTAR_HS
 SG_ DTCIUnused2_78F : 6|1@0+ (1,0) [0|1] ""  CGM_HS,CSM_HS,HMIM_HS,TCP_HS,VLBS_HS,ONSTAR_HS
 SG_ DTCIUnused3_78F : 5|1@0+ (1,0) [0|1] ""  CGM_HS,CSM_HS,HMIM_HS,TCP_HS,VLBS_HS,ONSTAR_HS
 SG_ DTCIUnused4_78F : 4|1@0+ (1,0) [0|1] ""  CGM_HS,CSM_HS,HMIM_HS,TCP_HS,VLBS_HS,ONSTAR_HS
 SG_ DTCIUnused5_78F : 3|1@0+ (1,0) [0|1] ""  CGM_HS,CSM_HS,HMIM_HS,TCP_HS,VLBS_HS,ONSTAR_HS
 SG_ DTCIUnused6_78F : 2|1@0+ (1,0) [0|1] ""  CGM_HS,CSM_HS,HMIM_HS,TCP_HS,VLBS_HS,ONSTAR_HS
 SG_ DTCIUnused7_78F : 1|1@0+ (1,0) [0|1] ""  CGM_HS,CSM_HS,HMIM_HS,TCP_HS,VLBS_HS,ONSTAR_HS
 SG_ DTCI_CodeSupported_78F : 40|1@0+ (1,0) [0|1] ""  CGM_HS,CSM_HS,HMIM_HS,TCP_HS,VLBS_HS,ONSTAR_HS
 SG_ DTCI_CurrentStatus_78F : 41|1@0+ (1,0) [0|1] ""  CGM_HS,CSM_HS,HMIM_HS,TCP_HS,VLBS_HS,ONSTAR_HS
 SG_ DTCI_DTCFaultType_78F : 55|8@0+ (1,0) [0|255] ""  CGM_HS,CSM_HS,HMIM_HS,TCP_HS,VLBS_HS,ONSTAR_HS
 SG_ DTCI_TstFldCdClrdStat_78F : 43|1@0+ (1,0) [0|1] ""  CGM_HS,CSM_HS,HMIM_HS,TCP_HS,VLBS_HS,ONSTAR_HS
 SG_ DTCI_TstNPsdCdClrdSt_78F : 42|1@0+ (1,0) [0|1] ""  CGM_HS,CSM_HS,HMIM_HS,TCP_HS,VLBS_HS,ONSTAR_HS
 SG_ DTCI_HistStat_78F : 44|1@0+ (1,0) [0|1] ""  CGM_HS,CSM_HS,HMIM_HS,TCP_HS,VLBS_HS,ONSTAR_HS
 SG_ DTCI_TstNPsdPwrUpSt_78F : 45|1@0+ (1,0) [0|1] ""  CGM_HS,CSM_HS,HMIM_HS,TCP_HS,VLBS_HS,ONSTAR_HS
 SG_ DTCI_TstFldPwrUpSt_78F : 46|1@0+ (1,0) [0|1] ""  CGM_HS,CSM_HS,HMIM_HS,TCP_HS,VLBS_HS,ONSTAR_HS
 SG_ DTCI_WrnIndRqdSt_78F : 47|1@0+ (1,0) [0|1] ""  CGM_HS,CSM_HS,HMIM_HS,TCP_HS,VLBS_HS,ONSTAR_HS
 SG_ DTCI_DTCFailType_78F : 39|8@0+ (1,0) [0|255] ""  CGM_HS,CSM_HS,HMIM_HS,TCP_HS,VLBS_HS,ONSTAR_HS
 SG_ DTCI_DTCNumber_78F : 23|16@0+ (1,0) [0|65535] ""  CGM_HS,CSM_HS,HMIM_HS,TCP_HS,VLBS_HS,ONSTAR_HS

BO_ 1934 DTC_Triggered_78E: 7 ESCM_SP_HS
 SG_ DTCI_CodeSupported_78E : 40|1@0+ (1,0) [0|1] ""  CGM_HS,CSM_HS,HMIM_HS,TCP_HS,VLBS_HS,ONSTAR_HS
 SG_ DTCI_CurrentStatus_78E : 41|1@0+ (1,0) [0|1] ""  CGM_HS,CSM_HS,HMIM_HS,TCP_HS,VLBS_HS,ONSTAR_HS
 SG_ DTCI_DTCFailType_78E : 39|8@0+ (1,0) [0|255] ""  CGM_HS,CSM_HS,HMIM_HS,TCP_HS,VLBS_HS,ONSTAR_HS
 SG_ DTCI_DTCFaultType_78E : 55|8@0+ (1,0) [0|255] ""  CGM_HS,CSM_HS,HMIM_HS,TCP_HS,VLBS_HS,ONSTAR_HS
 SG_ DTCI_DTCNumber_78E : 23|16@0+ (1,0) [0|65535] ""  CGM_HS,CSM_HS,HMIM_HS,TCP_HS,VLBS_HS,ONSTAR_HS
 SG_ DTCI_DTCSource_78E : 15|8@0+ (1,0) [0|255] ""  CGM_HS,CSM_HS,HMIM_HS,TCP_HS,VLBS_HS,ONSTAR_HS
 SG_ DTCI_DTCTriggered_78E : 0|1@0+ (1,0) [0|1] ""  CGM_HS,CSM_HS,HMIM_HS,TCP_HS,VLBS_HS,ONSTAR_HS
 SG_ DTCI_HistStat_78E : 44|1@0+ (1,0) [0|1] ""  CGM_HS,CSM_HS,HMIM_HS,TCP_HS,VLBS_HS,ONSTAR_HS
 SG_ DTCI_TstFldCdClrdStat_78E : 43|1@0+ (1,0) [0|1] ""  CGM_HS,CSM_HS,HMIM_HS,TCP_HS,VLBS_HS,ONSTAR_HS
 SG_ DTCI_TstFldPwrUpSt_78E : 46|1@0+ (1,0) [0|1] ""  CGM_HS,CSM_HS,HMIM_HS,TCP_HS,VLBS_HS,ONSTAR_HS
 SG_ DTCI_TstNPsdCdClrdSt_78E : 42|1@0+ (1,0) [0|1] ""  CGM_HS,CSM_HS,HMIM_HS,TCP_HS,VLBS_HS,ONSTAR_HS
 SG_ DTCI_TstNPsdPwrUpSt_78E : 45|1@0+ (1,0) [0|1] ""  CGM_HS,CSM_HS,HMIM_HS,TCP_HS,VLBS_HS,ONSTAR_HS
 SG_ DTCIUnused1_78E : 7|1@0+ (1,0) [0|1] ""  CGM_HS,CSM_HS,HMIM_HS,TCP_HS,VLBS_HS,ONSTAR_HS
 SG_ DTCIUnused2_78E : 6|1@0+ (1,0) [0|1] ""  CGM_HS,CSM_HS,HMIM_HS,TCP_HS,VLBS_HS,ONSTAR_HS
 SG_ DTCIUnused3_78E : 5|1@0+ (1,0) [0|1] ""  CGM_HS,CSM_HS,HMIM_HS,TCP_HS,VLBS_HS,ONSTAR_HS
 SG_ DTCIUnused4_78E : 4|1@0+ (1,0) [0|1] ""  CGM_HS,CSM_HS,HMIM_HS,TCP_HS,VLBS_HS,ONSTAR_HS
 SG_ DTCIUnused5_78E : 3|1@0+ (1,0) [0|1] ""  CGM_HS,CSM_HS,HMIM_HS,TCP_HS,VLBS_HS,ONSTAR_HS
 SG_ DTCIUnused6_78E : 2|1@0+ (1,0) [0|1] ""  CGM_HS,CSM_HS,HMIM_HS,TCP_HS,VLBS_HS,ONSTAR_HS
 SG_ DTCIUnused7_78E : 1|1@0+ (1,0) [0|1] ""  CGM_HS,CSM_HS,HMIM_HS,TCP_HS,VLBS_HS,ONSTAR_HS
 SG_ DTCI_WrnIndRqdSt_78E : 47|1@0+ (1,0) [0|1] ""  CGM_HS,CSM_HS,HMIM_HS,TCP_HS,VLBS_HS,ONSTAR_HS

BO_ 1933 DTC_Triggered_78D: 7 EOCM2B_K1_HS
 SG_ DTCI_CodeSupported_78D : 40|1@0+ (1,0) [0|1] ""  CGM_HS,CSM_HS,HMIM_HS,TCP_HS,VLBS_HS,ONSTAR_HS
 SG_ DTCI_CurrentStatus_78D : 41|1@0+ (1,0) [0|1] ""  CGM_HS,CSM_HS,HMIM_HS,TCP_HS,VLBS_HS,ONSTAR_HS
 SG_ DTCI_DTCFailType_78D : 39|8@0+ (1,0) [0|255] ""  CGM_HS,CSM_HS,HMIM_HS,TCP_HS,VLBS_HS,ONSTAR_HS
 SG_ DTCI_DTCFaultType_78D : 55|8@0+ (1,0) [0|255] ""  CGM_HS,CSM_HS,HMIM_HS,TCP_HS,VLBS_HS,ONSTAR_HS
 SG_ DTCI_DTCNumber_78D : 23|16@0+ (1,0) [0|65535] ""  CGM_HS,CSM_HS,HMIM_HS,TCP_HS,VLBS_HS,ONSTAR_HS
 SG_ DTCI_DTCSource_78D : 15|8@0+ (1,0) [0|255] ""  CGM_HS,CSM_HS,HMIM_HS,TCP_HS,VLBS_HS,ONSTAR_HS
 SG_ DTCI_DTCTriggered_78D : 0|1@0+ (1,0) [0|1] ""  CGM_HS,CSM_HS,HMIM_HS,TCP_HS,VLBS_HS,ONSTAR_HS
 SG_ DTCI_HistStat_78D : 44|1@0+ (1,0) [0|1] ""  CGM_HS,CSM_HS,HMIM_HS,TCP_HS,VLBS_HS,ONSTAR_HS
 SG_ DTCI_TstFldCdClrdStat_78D : 43|1@0+ (1,0) [0|1] ""  CGM_HS,CSM_HS,HMIM_HS,TCP_HS,VLBS_HS,ONSTAR_HS
 SG_ DTCI_TstFldPwrUpSt_78D : 46|1@0+ (1,0) [0|1] ""  CGM_HS,CSM_HS,HMIM_HS,TCP_HS,VLBS_HS,ONSTAR_HS
 SG_ DTCI_TstNPsdCdClrdSt_78D : 42|1@0+ (1,0) [0|1] ""  CGM_HS,CSM_HS,HMIM_HS,TCP_HS,VLBS_HS,ONSTAR_HS
 SG_ DTCI_TstNPsdPwrUpSt_78D : 45|1@0+ (1,0) [0|1] ""  CGM_HS,CSM_HS,HMIM_HS,TCP_HS,VLBS_HS,ONSTAR_HS
 SG_ DTCIUnused1_78D : 7|1@0+ (1,0) [0|1] ""  CGM_HS,CSM_HS,HMIM_HS,TCP_HS,VLBS_HS,ONSTAR_HS
 SG_ DTCIUnused2_78D : 6|1@0+ (1,0) [0|1] ""  CGM_HS,CSM_HS,HMIM_HS,TCP_HS,VLBS_HS,ONSTAR_HS
 SG_ DTCIUnused3_78D : 5|1@0+ (1,0) [0|1] ""  CGM_HS,CSM_HS,HMIM_HS,TCP_HS,VLBS_HS,ONSTAR_HS
 SG_ DTCIUnused4_78D : 4|1@0+ (1,0) [0|1] ""  CGM_HS,CSM_HS,HMIM_HS,TCP_HS,VLBS_HS,ONSTAR_HS
 SG_ DTCIUnused5_78D : 3|1@0+ (1,0) [0|1] ""  CGM_HS,CSM_HS,HMIM_HS,TCP_HS,VLBS_HS,ONSTAR_HS
 SG_ DTCIUnused6_78D : 2|1@0+ (1,0) [0|1] ""  CGM_HS,CSM_HS,HMIM_HS,TCP_HS,VLBS_HS,ONSTAR_HS
 SG_ DTCIUnused7_78D : 1|1@0+ (1,0) [0|1] ""  CGM_HS,CSM_HS,HMIM_HS,TCP_HS,VLBS_HS,ONSTAR_HS
 SG_ DTCI_WrnIndRqdSt_78D : 47|1@0+ (1,0) [0|1] ""  CGM_HS,CSM_HS,HMIM_HS,TCP_HS,VLBS_HS,ONSTAR_HS

BO_ 1932 DTC_Triggered_78C: 7 VLBS_HS
 SG_ DTCI_CodeSupported_78C : 40|1@0+ (1,0) [0|1] ""  CGM_HS,CSM_HS,HMIM_HS,TCP_HS,VLBS_HS,ONSTAR_HS
 SG_ DTCI_CurrentStatus_78C : 41|1@0+ (1,0) [0|1] ""  CGM_HS,CSM_HS,HMIM_HS,TCP_HS,VLBS_HS,ONSTAR_HS
 SG_ DTCI_DTCFailType_78C : 39|8@0+ (1,0) [0|255] ""  CGM_HS,CSM_HS,HMIM_HS,TCP_HS,VLBS_HS,ONSTAR_HS
 SG_ DTCI_DTCFaultType_78C : 55|8@0+ (1,0) [0|255] ""  CGM_HS,CSM_HS,HMIM_HS,TCP_HS,VLBS_HS,ONSTAR_HS
 SG_ DTCI_DTCNumber_78C : 23|16@0+ (1,0) [0|65535] ""  CGM_HS,CSM_HS,HMIM_HS,TCP_HS,VLBS_HS,ONSTAR_HS
 SG_ DTCI_DTCSource_78C : 15|8@0+ (1,0) [0|255] ""  CGM_HS,CSM_HS,HMIM_HS,TCP_HS,VLBS_HS,ONSTAR_HS
 SG_ DTCI_DTCTriggered_78C : 0|1@0+ (1,0) [0|1] ""  CGM_HS,CSM_HS,HMIM_HS,TCP_HS,VLBS_HS,ONSTAR_HS
 SG_ DTCI_HistStat_78C : 44|1@0+ (1,0) [0|1] ""  CGM_HS,CSM_HS,HMIM_HS,TCP_HS,VLBS_HS,ONSTAR_HS
 SG_ DTCI_TstFldCdClrdStat_78C : 43|1@0+ (1,0) [0|1] ""  CGM_HS,CSM_HS,HMIM_HS,TCP_HS,VLBS_HS,ONSTAR_HS
 SG_ DTCI_TstFldPwrUpSt_78C : 45|1@0+ (1,0) [0|1] ""  CGM_HS,CSM_HS,HMIM_HS,TCP_HS,VLBS_HS,ONSTAR_HS
 SG_ DTCI_TstNPsdCdClrdSt_78C : 42|1@0+ (1,0) [0|1] ""  CGM_HS,CSM_HS,HMIM_HS,TCP_HS,VLBS_HS,ONSTAR_HS
 SG_ DTCI_TstNPsdPwrUpSt_78C : 46|1@0+ (1,0) [0|1] ""  CGM_HS,CSM_HS,HMIM_HS,TCP_HS,VLBS_HS,ONSTAR_HS
 SG_ DTCIUnused1_78C : 7|1@0+ (1,0) [0|1] ""  CGM_HS,CSM_HS,HMIM_HS,TCP_HS,VLBS_HS,ONSTAR_HS
 SG_ DTCIUnused2_78C : 6|1@0+ (1,0) [0|1] ""  CGM_HS,CSM_HS,HMIM_HS,TCP_HS,VLBS_HS,ONSTAR_HS
 SG_ DTCIUnused3_78C : 5|1@0+ (1,0) [0|1] ""  CGM_HS,CSM_HS,HMIM_HS,TCP_HS,VLBS_HS,ONSTAR_HS
 SG_ DTCIUnused4_78C : 4|1@0+ (1,0) [0|1] ""  CGM_HS,CSM_HS,HMIM_HS,TCP_HS,VLBS_HS,ONSTAR_HS
 SG_ DTCIUnused5_78C : 3|1@0+ (1,0) [0|1] ""  CGM_HS,CSM_HS,HMIM_HS,TCP_HS,VLBS_HS,ONSTAR_HS
 SG_ DTCIUnused6_78C : 2|1@0+ (1,0) [0|1] ""  CGM_HS,CSM_HS,HMIM_HS,TCP_HS,VLBS_HS,ONSTAR_HS
 SG_ DTCIUnused7_78C : 1|1@0+ (1,0) [0|1] ""  CGM_HS,CSM_HS,HMIM_HS,TCP_HS,VLBS_HS,ONSTAR_HS
 SG_ DTCI_WrnIndRqdSt_78C : 47|1@0+ (1,0) [0|1] ""  CGM_HS,CSM_HS,HMIM_HS,TCP_HS,VLBS_HS,ONSTAR_HS

BO_ 1931 DTC_Triggered_78B: 7 SAS_HS
 SG_ DTCI_CodeSupported_78B : 40|1@0+ (1,0) [0|1] ""  CGM_HS,CSM_HS,HMIM_HS,TCP_HS,VLBS_HS,ONSTAR_HS
 SG_ DTCI_CurrentStatus_78B : 41|1@0+ (1,0) [0|1] ""  CGM_HS,CSM_HS,HMIM_HS,TCP_HS,VLBS_HS,ONSTAR_HS
 SG_ DTCI_DTCFailType_78B : 39|8@0+ (1,0) [0|255] ""  CGM_HS,CSM_HS,HMIM_HS,TCP_HS,VLBS_HS,ONSTAR_HS
 SG_ DTCI_DTCFaultType_78B : 55|8@0+ (1,0) [0|255] ""  CGM_HS,CSM_HS,HMIM_HS,TCP_HS,VLBS_HS,ONSTAR_HS
 SG_ DTCI_DTCNumber_78B : 23|16@0+ (1,0) [0|65535] ""  CGM_HS,CSM_HS,HMIM_HS,TCP_HS,VLBS_HS,ONSTAR_HS
 SG_ DTCI_DTCSource_78B : 15|8@0+ (1,0) [0|255] ""  CGM_HS,CSM_HS,HMIM_HS,TCP_HS,VLBS_HS,ONSTAR_HS
 SG_ DTCI_DTCTriggered_78B : 0|1@0+ (1,0) [0|1] ""  CGM_HS,CSM_HS,HMIM_HS,TCP_HS,VLBS_HS,ONSTAR_HS
 SG_ DTCI_HistStat_78B : 44|1@0+ (1,0) [0|1] ""  CGM_HS,CSM_HS,HMIM_HS,TCP_HS,VLBS_HS,ONSTAR_HS
 SG_ DTCI_TstFldCdClrdStat_78B : 43|1@0+ (1,0) [0|1] ""  CGM_HS,CSM_HS,HMIM_HS,TCP_HS,VLBS_HS,ONSTAR_HS
 SG_ DTCI_TstFldPwrUpSt_78B : 46|1@0+ (1,0) [0|1] ""  CGM_HS,CSM_HS,HMIM_HS,TCP_HS,VLBS_HS,ONSTAR_HS
 SG_ DTCI_TstNPsdCdClrdSt_78B : 42|1@0+ (1,0) [0|1] ""  CGM_HS,CSM_HS,HMIM_HS,TCP_HS,VLBS_HS,ONSTAR_HS
 SG_ DTCI_TstNPsdPwrUpSt_78B : 45|1@0+ (1,0) [0|1] ""  CGM_HS,CSM_HS,HMIM_HS,TCP_HS,VLBS_HS,ONSTAR_HS
 SG_ DTCIUnused1_78B : 7|1@0+ (1,0) [0|1] ""  CGM_HS,CSM_HS,HMIM_HS,TCP_HS,VLBS_HS,ONSTAR_HS
 SG_ DTCIUnused2_78B : 6|1@0+ (1,0) [0|1] ""  CGM_HS,CSM_HS,HMIM_HS,TCP_HS,VLBS_HS,ONSTAR_HS
 SG_ DTCIUnused3_78B : 5|1@0+ (1,0) [0|1] ""  CGM_HS,CSM_HS,HMIM_HS,TCP_HS,VLBS_HS,ONSTAR_HS
 SG_ DTCIUnused4_78B : 4|1@0+ (1,0) [0|1] ""  CGM_HS,CSM_HS,HMIM_HS,TCP_HS,VLBS_HS,ONSTAR_HS
 SG_ DTCIUnused5_78B : 3|1@0+ (1,0) [0|1] ""  CGM_HS,CSM_HS,HMIM_HS,TCP_HS,VLBS_HS,ONSTAR_HS
 SG_ DTCIUnused6_78B : 2|1@0+ (1,0) [0|1] ""  CGM_HS,CSM_HS,HMIM_HS,TCP_HS,VLBS_HS,ONSTAR_HS
 SG_ DTCIUnused7_78B : 1|1@0+ (1,0) [0|1] ""  CGM_HS,CSM_HS,HMIM_HS,TCP_HS,VLBS_HS,ONSTAR_HS
 SG_ DTCI_WrnIndRqdSt_78B : 47|1@0+ (1,0) [0|1] ""  CGM_HS,CSM_HS,HMIM_HS,TCP_HS,VLBS_HS,ONSTAR_HS

BO_ 1930 DTC_Triggered_78A: 7 FCM_HS
 SG_ DTCI_CodeSupported_78A : 40|1@0+ (1,0) [0|1] ""  CGM_HS,CSM_HS,HMIM_HS,TCP_HS,VLBS_HS,ONSTAR_HS
 SG_ DTCI_CurrentStatus_78A : 41|1@0+ (1,0) [0|1] ""  CGM_HS,CSM_HS,HMIM_HS,TCP_HS,VLBS_HS,ONSTAR_HS
 SG_ DTCI_DTCFailType_78A : 39|8@0+ (1,0) [0|255] ""  CGM_HS,CSM_HS,HMIM_HS,TCP_HS,VLBS_HS,ONSTAR_HS
 SG_ DTCI_DTCFaultType_78A : 55|8@0+ (1,0) [0|255] ""  CGM_HS,CSM_HS,HMIM_HS,TCP_HS,VLBS_HS,ONSTAR_HS
 SG_ DTCI_DTCNumber_78A : 23|16@0+ (1,0) [0|65535] ""  CGM_HS,CSM_HS,HMIM_HS,TCP_HS,VLBS_HS,ONSTAR_HS
 SG_ DTCI_DTCSource_78A : 15|8@0+ (1,0) [0|255] ""  CGM_HS,CSM_HS,HMIM_HS,TCP_HS,VLBS_HS,ONSTAR_HS
 SG_ DTCI_DTCTriggered_78A : 0|1@0+ (1,0) [0|1] ""  CGM_HS,CSM_HS,HMIM_HS,TCP_HS,VLBS_HS,ONSTAR_HS
 SG_ DTCI_HistStat_78A : 44|1@0+ (1,0) [0|1] ""  CGM_HS,CSM_HS,HMIM_HS,TCP_HS,VLBS_HS,ONSTAR_HS
 SG_ DTCI_TstFldCdClrdStat_78A : 43|1@0+ (1,0) [0|1] ""  CGM_HS,CSM_HS,HMIM_HS,TCP_HS,VLBS_HS,ONSTAR_HS
 SG_ DTCI_TstFldPwrUpSt_78A : 46|1@0+ (1,0) [0|1] ""  CGM_HS,CSM_HS,HMIM_HS,TCP_HS,VLBS_HS,ONSTAR_HS
 SG_ DTCI_TstNPsdCdClrdSt_78A : 42|1@0+ (1,0) [0|1] ""  CGM_HS,CSM_HS,HMIM_HS,TCP_HS,VLBS_HS,ONSTAR_HS
 SG_ DTCI_TstNPsdPwrUpSt_78A : 45|1@0+ (1,0) [0|1] ""  CGM_HS,CSM_HS,HMIM_HS,TCP_HS,VLBS_HS,ONSTAR_HS
 SG_ DTCIUnused1_78A : 7|1@0+ (1,0) [0|1] ""  CGM_HS,CSM_HS,HMIM_HS,TCP_HS,VLBS_HS,ONSTAR_HS
 SG_ DTCIUnused2_78A : 6|1@0+ (1,0) [0|1] ""  CGM_HS,CSM_HS,HMIM_HS,TCP_HS,VLBS_HS,ONSTAR_HS
 SG_ DTCIUnused3_78A : 5|1@0+ (1,0) [0|1] ""  CGM_HS,CSM_HS,HMIM_HS,TCP_HS,VLBS_HS,ONSTAR_HS
 SG_ DTCIUnused4_78A : 4|1@0+ (1,0) [0|1] ""  CGM_HS,CSM_HS,HMIM_HS,TCP_HS,VLBS_HS,ONSTAR_HS
 SG_ DTCIUnused5_78A : 3|1@0+ (1,0) [0|1] ""  CGM_HS,CSM_HS,HMIM_HS,TCP_HS,VLBS_HS,ONSTAR_HS
 SG_ DTCIUnused6_78A : 2|1@0+ (1,0) [0|1] ""  CGM_HS,CSM_HS,HMIM_HS,TCP_HS,VLBS_HS,ONSTAR_HS
 SG_ DTCIUnused7_78A : 1|1@0+ (1,0) [0|1] ""  CGM_HS,CSM_HS,HMIM_HS,TCP_HS,VLBS_HS,ONSTAR_HS
 SG_ DTCI_WrnIndRqdSt_78A : 47|1@0+ (1,0) [0|1] ""  CGM_HS,CSM_HS,HMIM_HS,TCP_HS,VLBS_HS,ONSTAR_HS

BO_ 1929 DTC_Triggered_789: 7 ARS_HS
 SG_ DTCI_CodeSupported_789 : 40|1@0+ (1,0) [0|1] ""  CGM_HS,CSM_HS,HMIM_HS,TCP_HS,VLBS_HS,ONSTAR_HS
 SG_ DTCI_CurrentStatus_789 : 41|1@0+ (1,0) [0|1] ""  CGM_HS,CSM_HS,HMIM_HS,TCP_HS,VLBS_HS,ONSTAR_HS
 SG_ DTCI_DTCFailType_789 : 39|8@0+ (1,0) [0|255] ""  CGM_HS,CSM_HS,HMIM_HS,TCP_HS,VLBS_HS,ONSTAR_HS
 SG_ DTCI_DTCFaultType_789 : 55|8@0+ (1,0) [0|255] ""  CGM_HS,CSM_HS,HMIM_HS,TCP_HS,VLBS_HS,ONSTAR_HS
 SG_ DTCI_DTCNumber_789 : 23|16@0+ (1,0) [0|65535] ""  CGM_HS,CSM_HS,HMIM_HS,TCP_HS,VLBS_HS,ONSTAR_HS
 SG_ DTCI_DTCSource_789 : 15|8@0+ (1,0) [0|255] ""  CGM_HS,CSM_HS,HMIM_HS,TCP_HS,VLBS_HS,ONSTAR_HS
 SG_ DTCI_DTCTriggered_789 : 0|1@0+ (1,0) [0|1] ""  CGM_HS,CSM_HS,HMIM_HS,TCP_HS,VLBS_HS,ONSTAR_HS
 SG_ DTCI_HistStat_789 : 44|1@0+ (1,0) [0|1] ""  CGM_HS,CSM_HS,HMIM_HS,TCP_HS,VLBS_HS,ONSTAR_HS
 SG_ DTCI_TstFldCdClrdStat_789 : 43|1@0+ (1,0) [0|1] ""  CGM_HS,CSM_HS,HMIM_HS,TCP_HS,VLBS_HS,ONSTAR_HS
 SG_ DTCI_TstFldPwrUpSt_789 : 46|1@0+ (1,0) [0|1] ""  CGM_HS,CSM_HS,HMIM_HS,TCP_HS,VLBS_HS,ONSTAR_HS
 SG_ DTCI_TstNPsdCdClrdSt_789 : 42|1@0+ (1,0) [0|1] ""  CGM_HS,CSM_HS,HMIM_HS,TCP_HS,VLBS_HS,ONSTAR_HS
 SG_ DTCI_TstNPsdPwrUpSt_789 : 45|1@0+ (1,0) [0|1] ""  CGM_HS,CSM_HS,HMIM_HS,TCP_HS,VLBS_HS,ONSTAR_HS
 SG_ DTCIUnused1_789 : 7|1@0+ (1,0) [0|1] ""  CGM_HS,CSM_HS,HMIM_HS,TCP_HS,VLBS_HS,ONSTAR_HS
 SG_ DTCIUnused2_789 : 6|1@0+ (1,0) [0|1] ""  CGM_HS,CSM_HS,HMIM_HS,TCP_HS,VLBS_HS,ONSTAR_HS
 SG_ DTCIUnused3_789 : 5|1@0+ (1,0) [0|1] ""  CGM_HS,CSM_HS,HMIM_HS,TCP_HS,VLBS_HS,ONSTAR_HS
 SG_ DTCIUnused4_789 : 4|1@0+ (1,0) [0|1] ""  CGM_HS,CSM_HS,HMIM_HS,TCP_HS,VLBS_HS,ONSTAR_HS
 SG_ DTCIUnused5_789 : 3|1@0+ (1,0) [0|1] ""  CGM_HS,CSM_HS,HMIM_HS,TCP_HS,VLBS_HS,ONSTAR_HS
 SG_ DTCIUnused6_789 : 2|1@0+ (1,0) [0|1] ""  CGM_HS,CSM_HS,HMIM_HS,TCP_HS,VLBS_HS,ONSTAR_HS
 SG_ DTCIUnused7_789 : 1|1@0+ (1,0) [0|1] ""  CGM_HS,CSM_HS,HMIM_HS,TCP_HS,VLBS_HS,ONSTAR_HS
 SG_ DTCI_WrnIndRqdSt_789 : 47|1@0+ (1,0) [0|1] ""  CGM_HS,CSM_HS,HMIM_HS,TCP_HS,VLBS_HS,ONSTAR_HS

BO_ 1928 DTC_Triggered_788: 7 HMIM_HS
 SG_ DTCI_CodeSupported_788 : 40|1@0+ (1,0) [0|1] ""  CSM_HS,HMIM_HS,TCP_HS,VLBS_HS,ONSTAR_HS
 SG_ DTCI_CurrentStatus_788 : 41|1@0+ (1,0) [0|1] ""  CSM_HS,HMIM_HS,TCP_HS,VLBS_HS,ONSTAR_HS
 SG_ DTCI_DTCFailType_788 : 39|8@0+ (1,0) [0|255] ""  CSM_HS,HMIM_HS,TCP_HS,VLBS_HS,ONSTAR_HS
 SG_ DTCI_DTCFaultType_788 : 55|8@0+ (1,0) [0|255] ""  CSM_HS,HMIM_HS,TCP_HS,VLBS_HS,ONSTAR_HS
 SG_ DTCI_DTCNumber_788 : 23|16@0+ (1,0) [0|65535] ""  CSM_HS,HMIM_HS,TCP_HS,VLBS_HS,ONSTAR_HS
 SG_ DTCI_DTCSource_788 : 15|8@0+ (1,0) [0|255] ""  CSM_HS,HMIM_HS,TCP_HS,VLBS_HS,ONSTAR_HS
 SG_ DTCI_DTCTriggered_788 : 0|1@0+ (1,0) [0|1] ""  CSM_HS,HMIM_HS,TCP_HS,VLBS_HS,ONSTAR_HS
 SG_ DTCI_HistStat_788 : 44|1@0+ (1,0) [0|1] ""  CSM_HS,HMIM_HS,TCP_HS,VLBS_HS,ONSTAR_HS
 SG_ DTCI_TstFldCdClrdStat_788 : 42|1@0+ (1,0) [0|1] ""  CSM_HS,HMIM_HS,TCP_HS,VLBS_HS,ONSTAR_HS
 SG_ DTCI_TstFldPwrUpSt_788 : 46|1@0+ (1,0) [0|1] ""  CSM_HS,HMIM_HS,TCP_HS,VLBS_HS,ONSTAR_HS
 SG_ DTCI_TstNPsdCdClrdSt_788 : 43|1@0+ (1,0) [0|1] ""  CSM_HS,HMIM_HS,TCP_HS,VLBS_HS,ONSTAR_HS
 SG_ DTCI_TstNPsdPwrUpSt_788 : 45|1@0+ (1,0) [0|1] ""  CSM_HS,HMIM_HS,TCP_HS,VLBS_HS,ONSTAR_HS
 SG_ DTCIUnused1_788 : 7|1@0+ (1,0) [0|1] ""  CSM_HS,HMIM_HS,TCP_HS,VLBS_HS,ONSTAR_HS
 SG_ DTCIUnused2_788 : 6|1@0+ (1,0) [0|1] ""  CSM_HS,HMIM_HS,TCP_HS,VLBS_HS,ONSTAR_HS
 SG_ DTCIUnused3_788 : 5|1@0+ (1,0) [0|1] ""  CSM_HS,HMIM_HS,TCP_HS,VLBS_HS,ONSTAR_HS
 SG_ DTCIUnused4_788 : 4|1@0+ (1,0) [0|1] ""  CSM_HS,HMIM_HS,TCP_HS,VLBS_HS,ONSTAR_HS
 SG_ DTCIUnused5_788 : 3|1@0+ (1,0) [0|1] ""  CSM_HS,HMIM_HS,TCP_HS,VLBS_HS,ONSTAR_HS
 SG_ DTCIUnused6_788 : 2|1@0+ (1,0) [0|1] ""  CSM_HS,HMIM_HS,TCP_HS,VLBS_HS,ONSTAR_HS
 SG_ DTCIUnused7_788 : 1|1@0+ (1,0) [0|1] ""  CSM_HS,HMIM_HS,TCP_HS,VLBS_HS,ONSTAR_HS
 SG_ DTCI_WrnIndRqdSt_788 : 47|1@0+ (1,0) [0|1] ""  CSM_HS,HMIM_HS,TCP_HS,VLBS_HS,ONSTAR_HS

BO_ 1927 DTC_Triggered_787: 7 VICM_HS
 SG_ DTCI_CodeSupported_787 : 40|1@0+ (1,0) [0|1] ""  CGM_HS,CSM_HS,HMIM_HS,TCP_HS,VLBS_HS,ONSTAR_HS
 SG_ DTCI_CurrentStatus_787 : 41|1@0+ (1,0) [0|1] ""  CGM_HS,CSM_HS,HMIM_HS,TCP_HS,VLBS_HS,ONSTAR_HS
 SG_ DTCI_DTCFailType_787 : 39|8@0+ (1,0) [0|255] ""  CGM_HS,CSM_HS,HMIM_HS,TCP_HS,VLBS_HS,ONSTAR_HS
 SG_ DTCI_DTCFaultType_787 : 55|8@0+ (1,0) [0|255] ""  CGM_HS,CSM_HS,HMIM_HS,TCP_HS,VLBS_HS,ONSTAR_HS
 SG_ DTCI_DTCNumber_787 : 23|16@0+ (1,0) [0|65535] ""  CGM_HS,CSM_HS,HMIM_HS,TCP_HS,VLBS_HS,ONSTAR_HS
 SG_ DTCI_DTCSource_787 : 15|8@0+ (1,0) [0|255] ""  CGM_HS,CSM_HS,HMIM_HS,TCP_HS,VLBS_HS,ONSTAR_HS
 SG_ DTCI_DTCTriggered_787 : 0|1@0+ (1,0) [0|1] ""  CGM_HS,CSM_HS,HMIM_HS,TCP_HS,VLBS_HS,ONSTAR_HS
 SG_ DTCI_HistStat_787 : 44|1@0+ (1,0) [0|1] ""  CGM_HS,CSM_HS,HMIM_HS,TCP_HS,VLBS_HS,ONSTAR_HS
 SG_ DTCI_TstFldCdClrdStat_787 : 43|1@0+ (1,0) [0|1] ""  CGM_HS,CSM_HS,HMIM_HS,TCP_HS,VLBS_HS,ONSTAR_HS
 SG_ DTCI_TstFldPwrUpSt_787 : 46|1@0+ (1,0) [0|1] ""  CGM_HS,CSM_HS,HMIM_HS,TCP_HS,VLBS_HS,ONSTAR_HS
 SG_ DTCI_TstNPsdCdClrdSt_787 : 42|1@0+ (1,0) [0|1] ""  CGM_HS,CSM_HS,HMIM_HS,TCP_HS,VLBS_HS,ONSTAR_HS
 SG_ DTCI_TstNPsdPwrUpSt_787 : 45|1@0+ (1,0) [0|1] ""  CGM_HS,CSM_HS,HMIM_HS,TCP_HS,VLBS_HS,ONSTAR_HS
 SG_ DTCIUnused1_787 : 7|1@0+ (1,0) [0|1] ""  CGM_HS,CSM_HS,HMIM_HS,TCP_HS,VLBS_HS,ONSTAR_HS
 SG_ DTCIUnused2_787 : 6|1@0+ (1,0) [0|1] ""  CGM_HS,CSM_HS,HMIM_HS,TCP_HS,VLBS_HS,ONSTAR_HS
 SG_ DTCIUnused3_787 : 5|1@0+ (1,0) [0|1] ""  CGM_HS,CSM_HS,HMIM_HS,TCP_HS,VLBS_HS,ONSTAR_HS
 SG_ DTCIUnused4_787 : 4|1@0+ (1,0) [0|1] ""  CGM_HS,CSM_HS,HMIM_HS,TCP_HS,VLBS_HS,ONSTAR_HS
 SG_ DTCIUnused5_787 : 3|1@0+ (1,0) [0|1] ""  CGM_HS,CSM_HS,HMIM_HS,TCP_HS,VLBS_HS,ONSTAR_HS
 SG_ DTCIUnused6_787 : 2|1@0+ (1,0) [0|1] ""  CGM_HS,CSM_HS,HMIM_HS,TCP_HS,VLBS_HS,ONSTAR_HS
 SG_ DTCIUnused7_787 : 1|1@0+ (1,0) [0|1] ""  CGM_HS,CSM_HS,HMIM_HS,TCP_HS,VLBS_HS,ONSTAR_HS
 SG_ DTCI_WrnIndRqdSt_787 : 47|1@0+ (1,0) [0|1] ""  CGM_HS,CSM_HS,HMIM_HS,TCP_HS,VLBS_HS,ONSTAR_HS

BO_ 1926 DTC_Triggered_786: 7 MCP_B_HS
 SG_ DTCI_CodeSupported_786 : 40|1@0+ (1,0) [0|1] ""  CGM_HS,CSM_HS,HMIM_HS,TCP_HS,VLBS_HS,ONSTAR_HS
 SG_ DTCI_CurrentStatus_786 : 41|1@0+ (1,0) [0|1] ""  CGM_HS,CSM_HS,HMIM_HS,TCP_HS,VLBS_HS,ONSTAR_HS
 SG_ DTCI_DTCFailType_786 : 39|8@0+ (1,0) [0|255] ""  CGM_HS,CSM_HS,HMIM_HS,TCP_HS,VLBS_HS,ONSTAR_HS
 SG_ DTCI_DTCFaultType_786 : 55|8@0+ (1,0) [0|255] ""  CGM_HS,CSM_HS,HMIM_HS,TCP_HS,VLBS_HS,ONSTAR_HS
 SG_ DTCI_DTCNumber_786 : 23|16@0+ (1,0) [0|65535] ""  CGM_HS,CSM_HS,HMIM_HS,TCP_HS,VLBS_HS,ONSTAR_HS
 SG_ DTCI_DTCSource_786 : 15|8@0+ (1,0) [0|255] ""  CGM_HS,CSM_HS,HMIM_HS,TCP_HS,VLBS_HS,ONSTAR_HS
 SG_ DTCI_DTCTriggered_786 : 0|1@0+ (1,0) [0|1] ""  CGM_HS,CSM_HS,HMIM_HS,TCP_HS,VLBS_HS,ONSTAR_HS
 SG_ DTCI_HistStat_786 : 44|1@0+ (1,0) [0|1] ""  CGM_HS,CSM_HS,HMIM_HS,TCP_HS,VLBS_HS,ONSTAR_HS
 SG_ DTCI_TstFldCdClrdStat_786 : 43|1@0+ (1,0) [0|1] ""  CGM_HS,CSM_HS,HMIM_HS,TCP_HS,VLBS_HS,ONSTAR_HS
 SG_ DTCI_TstFldPwrUpSt_786 : 46|1@0+ (1,0) [0|1] ""  CGM_HS,CSM_HS,HMIM_HS,TCP_HS,VLBS_HS,ONSTAR_HS
 SG_ DTCI_TstNPsdCdClrdSt_786 : 42|1@0+ (1,0) [0|1] ""  CGM_HS,CSM_HS,HMIM_HS,TCP_HS,VLBS_HS,ONSTAR_HS
 SG_ DTCI_TstNPsdPwrUpSt_786 : 45|1@0+ (1,0) [0|1] ""  CGM_HS,CSM_HS,HMIM_HS,TCP_HS,VLBS_HS,ONSTAR_HS
 SG_ DTCIUnused1_786 : 7|1@0+ (1,0) [0|1] ""  CGM_HS,CSM_HS,HMIM_HS,TCP_HS,VLBS_HS,ONSTAR_HS
 SG_ DTCIUnused2_786 : 6|1@0+ (1,0) [0|1] ""  CGM_HS,CSM_HS,HMIM_HS,TCP_HS,VLBS_HS,ONSTAR_HS
 SG_ DTCIUnused3_786 : 5|1@0+ (1,0) [0|1] ""  CGM_HS,CSM_HS,HMIM_HS,TCP_HS,VLBS_HS,ONSTAR_HS
 SG_ DTCIUnused4_786 : 4|1@0+ (1,0) [0|1] ""  CGM_HS,CSM_HS,HMIM_HS,TCP_HS,VLBS_HS,ONSTAR_HS
 SG_ DTCIUnused5_786 : 3|1@0+ (1,0) [0|1] ""  CGM_HS,CSM_HS,HMIM_HS,TCP_HS,VLBS_HS,ONSTAR_HS
 SG_ DTCIUnused6_786 : 2|1@0+ (1,0) [0|1] ""  CGM_HS,CSM_HS,HMIM_HS,TCP_HS,VLBS_HS,ONSTAR_HS
 SG_ DTCIUnused7_786 : 1|1@0+ (1,0) [0|1] ""  CGM_HS,CSM_HS,HMIM_HS,TCP_HS,VLBS_HS,ONSTAR_HS
 SG_ DTCI_WrnIndRqdSt_786 : 47|1@0+ (1,0) [0|1] ""  CGM_HS,CSM_HS,HMIM_HS,TCP_HS,VLBS_HS,ONSTAR_HS

BO_ 1925 DTC_Triggered_785: 7 ICCM_HS
 SG_ DTCI_CodeSupported_785 : 40|1@0+ (1,0) [0|1] ""  CGM_HS,CSM_HS,HMIM_HS,TCP_HS,VLBS_HS,ONSTAR_HS
 SG_ DTCI_CurrentStatus_785 : 41|1@0+ (1,0) [0|1] ""  CGM_HS,CSM_HS,HMIM_HS,TCP_HS,VLBS_HS,ONSTAR_HS
 SG_ DTCI_DTCFailType_785 : 39|8@0+ (1,0) [0|255] ""  CGM_HS,CSM_HS,HMIM_HS,TCP_HS,VLBS_HS,ONSTAR_HS
 SG_ DTCI_DTCFaultType_785 : 55|8@0+ (1,0) [0|255] ""  CGM_HS,CSM_HS,HMIM_HS,TCP_HS,VLBS_HS,ONSTAR_HS
 SG_ DTCI_DTCNumber_785 : 23|16@0+ (1,0) [0|65535] ""  CGM_HS,CSM_HS,HMIM_HS,TCP_HS,VLBS_HS,ONSTAR_HS
 SG_ DTCI_DTCSource_785 : 15|8@0+ (1,0) [0|255] ""  CGM_HS,CSM_HS,HMIM_HS,TCP_HS,VLBS_HS,ONSTAR_HS
 SG_ DTCI_DTCTriggered_785 : 0|1@0+ (1,0) [0|1] ""  CGM_HS,CSM_HS,HMIM_HS,TCP_HS,VLBS_HS,ONSTAR_HS
 SG_ DTCI_HistStat_785 : 44|1@0+ (1,0) [0|1] ""  CGM_HS,CSM_HS,HMIM_HS,TCP_HS,VLBS_HS,ONSTAR_HS
 SG_ DTCI_TstFldCdClrdStat_785 : 43|1@0+ (1,0) [0|1] ""  CGM_HS,CSM_HS,HMIM_HS,TCP_HS,VLBS_HS,ONSTAR_HS
 SG_ DTCI_TstFldPwrUpSt_785 : 46|1@0+ (1,0) [0|1] ""  CGM_HS,CSM_HS,HMIM_HS,TCP_HS,VLBS_HS,ONSTAR_HS
 SG_ DTCI_TstNPsdCdClrdSt_785 : 42|1@0+ (1,0) [0|1] ""  CGM_HS,CSM_HS,HMIM_HS,TCP_HS,VLBS_HS,ONSTAR_HS
 SG_ DTCI_TstNPsdPwrUpSt_785 : 45|1@0+ (1,0) [0|1] ""  CGM_HS,CSM_HS,HMIM_HS,TCP_HS,VLBS_HS,ONSTAR_HS
 SG_ DTCIUnused1_785 : 7|1@0+ (1,0) [0|1] ""  CGM_HS,CSM_HS,HMIM_HS,TCP_HS,VLBS_HS,ONSTAR_HS
 SG_ DTCIUnused2_785 : 6|1@0+ (1,0) [0|1] ""  CGM_HS,CSM_HS,HMIM_HS,TCP_HS,VLBS_HS,ONSTAR_HS
 SG_ DTCIUnused3_785 : 5|1@0+ (1,0) [0|1] ""  CGM_HS,CSM_HS,HMIM_HS,TCP_HS,VLBS_HS,ONSTAR_HS
 SG_ DTCIUnused4_785 : 4|1@0+ (1,0) [0|1] ""  CGM_HS,CSM_HS,HMIM_HS,TCP_HS,VLBS_HS,ONSTAR_HS
 SG_ DTCIUnused5_785 : 3|1@0+ (1,0) [0|1] ""  CGM_HS,CSM_HS,HMIM_HS,TCP_HS,VLBS_HS,ONSTAR_HS
 SG_ DTCIUnused6_785 : 2|1@0+ (1,0) [0|1] ""  CGM_HS,CSM_HS,HMIM_HS,TCP_HS,VLBS_HS,ONSTAR_HS
 SG_ DTCIUnused7_785 : 1|1@0+ (1,0) [0|1] ""  CGM_HS,CSM_HS,HMIM_HS,TCP_HS,VLBS_HS,ONSTAR_HS
 SG_ DTCI_WrnIndRqdSt_785 : 47|1@0+ (1,0) [0|1] ""  CGM_HS,CSM_HS,HMIM_HS,TCP_HS,VLBS_HS,ONSTAR_HS

BO_ 1924 DTC_Triggered_784: 7 AVM_HS
 SG_ DTCI_HistStat_784 : 44|1@0+ (1,0) [0|1] ""  CGM_HS,CSM_HS,HMIM_HS,TCP_HS,VLBS_HS,ONSTAR_HS
 SG_ DTCI_TstFldCdClrdStat_784 : 43|1@0+ (1,0) [0|1] ""  CGM_HS,CSM_HS,HMIM_HS,TCP_HS,VLBS_HS,ONSTAR_HS
 SG_ DTCI_TstFldPwrUpSt_784 : 46|1@0+ (1,0) [0|1] ""  CGM_HS,CSM_HS,HMIM_HS,TCP_HS,VLBS_HS,ONSTAR_HS
 SG_ DTCI_TstNPsdCdClrdSt_784 : 42|1@0+ (1,0) [0|1] ""  CGM_HS,CSM_HS,HMIM_HS,TCP_HS,VLBS_HS,ONSTAR_HS
 SG_ DTCI_TstNPsdPwrUpSt_784 : 45|1@0+ (1,0) [0|1] ""  CGM_HS,CSM_HS,HMIM_HS,TCP_HS,VLBS_HS,ONSTAR_HS
 SG_ DTCIUnused1_784 : 7|1@0+ (1,0) [0|1] ""  CGM_HS,CSM_HS,HMIM_HS,TCP_HS,VLBS_HS,ONSTAR_HS
 SG_ DTCIUnused2_784 : 6|1@0+ (1,0) [0|1] ""  CGM_HS,CSM_HS,HMIM_HS,TCP_HS,VLBS_HS,ONSTAR_HS
 SG_ DTCIUnused3_784 : 5|1@0+ (1,0) [0|1] ""  CGM_HS,CSM_HS,HMIM_HS,TCP_HS,VLBS_HS,ONSTAR_HS
 SG_ DTCIUnused4_784 : 4|1@0+ (1,0) [0|1] ""  CGM_HS,CSM_HS,HMIM_HS,TCP_HS,VLBS_HS,ONSTAR_HS
 SG_ DTCIUnused5_784 : 3|1@0+ (1,0) [0|1] ""  CGM_HS,CSM_HS,HMIM_HS,TCP_HS,VLBS_HS,ONSTAR_HS
 SG_ DTCIUnused6_784 : 2|1@0+ (1,0) [0|1] ""  CGM_HS,CSM_HS,HMIM_HS,TCP_HS,VLBS_HS,ONSTAR_HS
 SG_ DTCIUnused7_784 : 1|1@0+ (1,0) [0|1] ""  CGM_HS,CSM_HS,HMIM_HS,TCP_HS,VLBS_HS,ONSTAR_HS
 SG_ DTCI_WrnIndRqdSt_784 : 47|1@0+ (1,0) [0|1] ""  CGM_HS,CSM_HS,HMIM_HS,TCP_HS,VLBS_HS,ONSTAR_HS
 SG_ DTCI_CodeSupported_784 : 40|1@0+ (1,0) [0|1] ""  CGM_HS,CSM_HS,HMIM_HS,TCP_HS,VLBS_HS,ONSTAR_HS
 SG_ DTCI_CurrentStatus_784 : 41|1@0+ (1,0) [0|1] ""  CGM_HS,CSM_HS,HMIM_HS,TCP_HS,VLBS_HS,ONSTAR_HS
 SG_ DTCI_DTCFailType_784 : 39|8@0+ (1,0) [0|255] ""  CGM_HS,CSM_HS,HMIM_HS,TCP_HS,VLBS_HS,ONSTAR_HS
 SG_ DTCI_DTCFaultType_784 : 55|8@0+ (1,0) [0|255] ""  CGM_HS,CSM_HS,HMIM_HS,TCP_HS,VLBS_HS,ONSTAR_HS
 SG_ DTCI_DTCNumber_784 : 23|16@0+ (1,0) [0|65535] ""  CGM_HS,CSM_HS,HMIM_HS,TCP_HS,VLBS_HS,ONSTAR_HS
 SG_ DTCI_DTCSource_784 : 15|8@0+ (1,0) [0|255] ""  CGM_HS,CSM_HS,HMIM_HS,TCP_HS,VLBS_HS,ONSTAR_HS
 SG_ DTCI_DTCTriggered_784 : 0|1@0+ (1,0) [0|1] ""  CGM_HS,CSM_HS,HMIM_HS,TCP_HS,VLBS_HS,ONSTAR_HS

BO_ 1923 DTC_Triggered_783: 7 ALC_HS
 SG_ DTCI_WrnIndRqdSt_783 : 47|1@0+ (1,0) [0|1] ""  CGM_HS,CSM_HS,HMIM_HS,TCP_HS,VLBS_HS,ONSTAR_HS
 SG_ DTCI_TstNPsdPwrUpSt_783 : 45|1@0+ (1,0) [0|1] ""  CGM_HS,CSM_HS,HMIM_HS,TCP_HS,VLBS_HS,ONSTAR_HS
 SG_ DTCI_TstNPsdCdClrdSt_783 : 42|1@0+ (1,0) [0|1] ""  CGM_HS,CSM_HS,HMIM_HS,TCP_HS,VLBS_HS,ONSTAR_HS
 SG_ DTCI_TstFldPwrUpSt_783 : 46|1@0+ (1,0) [0|1] ""  CGM_HS,CSM_HS,HMIM_HS,TCP_HS,VLBS_HS,ONSTAR_HS
 SG_ DTCI_TstFldCdClrdStat_783 : 43|1@0+ (1,0) [0|1] ""  CGM_HS,CSM_HS,HMIM_HS,TCP_HS,VLBS_HS,ONSTAR_HS
 SG_ DTCI_HistStat_783 : 44|1@0+ (1,0) [0|1] ""  CGM_HS,CSM_HS,HMIM_HS,TCP_HS,VLBS_HS,ONSTAR_HS
 SG_ DTCI_DTCTriggered_783 : 0|1@0+ (1,0) [0|1] ""  CGM_HS,CSM_HS,HMIM_HS,TCP_HS,VLBS_HS,ONSTAR_HS
 SG_ DTCI_DTCSource_783 : 15|8@0+ (1,0) [0|255] ""  CGM_HS,CSM_HS,HMIM_HS,TCP_HS,VLBS_HS,ONSTAR_HS
 SG_ DTCI_DTCNumber_783 : 23|16@0+ (1,0) [0|65535] ""  CGM_HS,CSM_HS,HMIM_HS,TCP_HS,VLBS_HS,ONSTAR_HS
 SG_ DTCI_DTCFaultType_783 : 55|8@0+ (1,0) [0|255] ""  CGM_HS,CSM_HS,HMIM_HS,TCP_HS,VLBS_HS,ONSTAR_HS
 SG_ DTCI_DTCFailType_783 : 39|8@0+ (1,0) [0|255] ""  CGM_HS,CSM_HS,HMIM_HS,TCP_HS,VLBS_HS,ONSTAR_HS
 SG_ DTCI_CurrentStatus_783 : 41|1@0+ (1,0) [0|1] ""  CGM_HS,CSM_HS,HMIM_HS,TCP_HS,VLBS_HS,ONSTAR_HS
 SG_ DTCI_CodeSupported_783 : 40|1@0+ (1,0) [0|1] ""  CGM_HS,CSM_HS,HMIM_HS,TCP_HS,VLBS_HS,ONSTAR_HS
 SG_ DTCIUnused7_783 : 1|1@0+ (1,0) [0|1] ""  CGM_HS,CSM_HS,HMIM_HS,TCP_HS,VLBS_HS,ONSTAR_HS
 SG_ DTCIUnused6_783 : 2|1@0+ (1,0) [0|1] ""  CGM_HS,CSM_HS,HMIM_HS,TCP_HS,VLBS_HS,ONSTAR_HS
 SG_ DTCIUnused5_783 : 3|1@0+ (1,0) [0|1] ""  CGM_HS,CSM_HS,HMIM_HS,TCP_HS,VLBS_HS,ONSTAR_HS
 SG_ DTCIUnused4_783 : 4|1@0+ (1,0) [0|1] ""  CGM_HS,CSM_HS,HMIM_HS,TCP_HS,VLBS_HS,ONSTAR_HS
 SG_ DTCIUnused3_783 : 5|1@0+ (1,0) [0|1] ""  CGM_HS,CSM_HS,HMIM_HS,TCP_HS,VLBS_HS,ONSTAR_HS
 SG_ DTCIUnused2_783 : 6|1@0+ (1,0) [0|1] ""  CGM_HS,CSM_HS,HMIM_HS,TCP_HS,VLBS_HS,ONSTAR_HS
 SG_ DTCIUnused1_783 : 7|1@0+ (1,0) [0|1] ""  CGM_HS,CSM_HS,HMIM_HS,TCP_HS,VLBS_HS,ONSTAR_HS

BO_ 1363 UUDT_Resp_From_AMP_HS: 8 AMP_HS
 SG_ DgnInf_HS553 : 7|64@0+ (1,0) [0|1.8446744074e+19] ""  CGM_HS,HMIM_HS,CSM_HS,TCP_HS,ONSTAR_HS,TestTool_HS

BO_ 607 USDT_Req_to_VLBS_CGM_HS: 8 TestTool_HS
 SG_ DgnInf : 7|64@0+ (1,0) [0|1.8446744074e+19] ""  TCP_HS,ONSTAR_HS,HMIM_HS,CGM_HS

BO_ 1630 USDT_Resp_From_VCM_HS: 8 VCM_HS
 SG_ DgnInf : 7|64@0+ (1,0) [0|1.8446744074e+19] ""  HMIM_HS,CSM_HS,CGM_HS,TCP_HS,ONSTAR_HS,TestTool_HS

BO_ 1629 USDT_Resp_From_ARS_HS: 8 ARS_HS
 SG_ DgnInf : 7|64@0+ (1,0) [0|1.8446744074e+19] ""  HMIM_HS,CSM_HS,CGM_HS,TCP_HS,ONSTAR_HS,TestTool_HS

BO_ 606 USDT_Req_to_VCM_HS: 8 TestTool_HS
 SG_ DgnInf : 7|64@0+ (1,0) [0|1.8446744074e+19] ""  TCP_HS,ONSTAR_HS,CGM_HS,HMIM_HS,IPC_HS,VCM_HS

BO_ 605 USDT_Req_to_ARS_HS: 8 TestTool_HS
 SG_ DgnInf : 7|64@0+ (1,0) [0|1.8446744074e+19] ""  TCP_HS,ONSTAR_HS,HMIM_HS,CGM_HS,ESCM_SP_HS,ARS_HS

BO_ 604 USDT_Req_to_ACCM_HS: 8 TestTool_HS
 SG_ DgnInf : 7|64@0+ (1,0) [0|1.8446744074e+19] ""  TCP_HS,ONSTAR_HS,CGM_HS,HMIM_HS,ACCM_HS

BO_ 603 USDT_Req_to_ACC_HS: 8 TestTool_HS
 SG_ DgnInf : 7|64@0+ (1,0) [0|1.8446744074e+19] ""  TCP_HS,ONSTAR_HS,HMIM_HS,CGM_HS,VPM_HS,ACC_HS

BO_ 602 USDT_Req_to_ICCM_B_HS: 8 TestTool_HS
 SG_ DgnInf : 7|64@0+ (1,0) [0|1.8446744074e+19] ""  TCP_HS,ONSTAR_HS,CGM_HS,HMIM_HS,ICCM_B_HS

BO_ 1631 USDT_Resp_From_VLBS_CGM_HS: 8 CGM_HS
 SG_ DgnInf : 7|64@0+ (1,0) [0|1.8446744074e+19] ""  HMIM_HS,CSM_HS,TCP_HS,ONSTAR_HS,TestTool_HS

BO_ 1375 UUDT_Resp_From_VLBS_CGM_HS: 8 CGM_HS
 SG_ DgnInf_HS55F : 7|64@0+ (1,0) [0|1.8446744074e+19] ""  HMIM_HS,CSM_HS,TCP_HS,ONSTAR_HS,TestTool_HS

BO_ 1374 UUDT_Resp_From_VCM_HS: 8 CGM_HS
 SG_ DgnInf_HS55E : 7|64@0+ (1,0) [0|1.8446744074e+19] ""  HMIM_HS,CSM_HS,CGM_HS,TCP_HS,ONSTAR_HS,TestTool_HS

BO_ 1373 UUDT_Resp_From_ARS_HS: 8 ARS_HS
 SG_ DgnInf_HS55D : 7|64@0+ (1,0) [0|1.8446744074e+19] ""  HMIM_HS,CSM_HS,CGM_HS,TCP_HS,ONSTAR_HS,TestTool_HS

BO_ 1372 UUDT_Resp_From_ACCM_HS: 8 ACCM_HS
 SG_ DgnInf_HS55C : 7|64@0+ (1,0) [0|1.8446744074e+19] ""  HMIM_HS,CSM_HS,CGM_HS,TCP_HS,ONSTAR_HS,TestTool_HS

BO_ 1371 UUDT_Resp_From_ACC_HS: 8 ACC_HS
 SG_ DgnInf_HS55B : 7|64@0+ (1,0) [0|1.8446744074e+19] ""  HMIM_HS,CSM_HS,CGM_HS,TCP_HS,ONSTAR_HS,TestTool_HS

BO_ 1370 UUDT_Resp_From_ICCM_B_HS: 8 ICCM_B_HS
 SG_ DgnInf_HS55A : 7|64@0+ (1,0) [0|1.8446744074e+19] ""  HMIM_HS,CSM_HS,CGM_HS,TCP_HS,ONSTAR_HS,TestTool_HS

BO_ 1368 UUDT_Resp_From_MCP_B_HS: 8 MCP_B_HS
 SG_ DgnInf_HS558 : 7|64@0+ (1,0) [0|1.8446744074e+19] ""  HMIM_HS,CSM_HS,CGM_HS,TCP_HS,ONSTAR_HS,TestTool_HS

BO_ 1367 UUDT_Resp_From_MCP_HS: 8 MCP_HS
 SG_ DgnInf_HS557 : 7|64@0+ (1,0) [0|1.8446744074e+19] ""  HMIM_HS,CSM_HS,CGM_HS,TCP_HS,ONSTAR_HS,TestTool_HS

BO_ 1366 UUDT_Resp_From_TCCM_HS: 8 TCCM_HS
 SG_ DgnInf_HS556 : 7|64@0+ (1,0) [0|1.8446744074e+19] ""  HMIM_HS,CSM_HS,CGM_HS,TCP_HS,ONSTAR_HS,TestTool_HS

BO_ 1362 UUDT_Resp_From_HMIM_HS: 8 HMIM_HS
 SG_ DgnInf_HS552 : 7|64@0+ (1,0) [0|1.8446744074e+19] ""  CGM_HS,TCP_HS,ONSTAR_HS,TestTool_HS

BO_ 1628 USDT_Resp_From_ACCM_HS: 8 ACCM_HS
 SG_ DgnInf : 7|64@0+ (1,0) [0|1.8446744074e+19] ""  HMIM_HS,CSM_HS,CGM_HS,TCP_HS,ONSTAR_HS,TestTool_HS

BO_ 1627 USDT_Resp_From_ACC_HS: 8 ACC_HS
 SG_ DgnInf : 7|64@0+ (1,0) [0|1.8446744074e+19] ""  HMIM_HS,CSM_HS,CGM_HS,TCP_HS,ONSTAR_HS,TestTool_HS

BO_ 1626 USDT_Resp_From_ICCM_B_HS: 8 ICCM_B_HS
 SG_ DgnInf : 7|64@0+ (1,0) [0|1.8446744074e+19] ""  HMIM_HS,CSM_HS,CGM_HS,TCP_HS,ONSTAR_HS,TestTool_HS

BO_ 1624 USDT_Resp_From_MCP_B_HS: 8 MCP_B_HS
 SG_ DgnInf : 7|64@0+ (1,0) [0|1.8446744074e+19] ""  HMIM_HS,CSM_HS,CGM_HS,TCP_HS,ONSTAR_HS,TestTool_HS

BO_ 1623 USDT_Resp_From_MCP_HS: 8 MCP_HS
 SG_ DgnInf : 7|64@0+ (1,0) [0|1.8446744074e+19] ""  HMIM_HS,CSM_HS,CGM_HS,TCP_HS,ONSTAR_HS,TestTool_HS

BO_ 1622 USDT_Resp_From_TCCM_HS: 8 TCCM_HS
 SG_ DgnInf : 7|64@0+ (1,0) [0|1.8446744074e+19] ""  HMIM_HS,CSM_HS,CGM_HS,TCP_HS,ONSTAR_HS,TestTool_HS

BO_ 1619 USDT_Resp_From_AMP_HS: 8 AMP_HS
 SG_ DgnInf : 7|64@0+ (1,0) [0|1.8446744074e+19] ""  CGM_HS,HMIM_HS,CSM_HS,TCP_HS,ONSTAR_HS,TestTool_HS

BO_ 1618 USDT_Resp_From_HMIM_HS: 8 HMIM_HS
 SG_ DgnInf : 7|64@0+ (1,0) [0|1.8446744074e+19] ""  CGM_HS,TCP_HS,ONSTAR_HS,TestTool_HS

BO_ 1617 USDT_Resp_From_Free_51_HS: 8 Dummy_HS
 SG_ DgnInf : 7|64@0+ (1,0) [0|1.8446744074e+19] ""  HMIM_HS,CSM_HS,CGM_HS,TCP_HS,ONSTAR_HS,TestTool_HS

BO_ 600 USDT_Req_to_MCP_B_HS: 8 TestTool_HS
 SG_ DgnInf : 7|64@0+ (1,0) [0|1.8446744074e+19] ""  TCP_HS,ONSTAR_HS,CGM_HS,HMIM_HS,MCP_B_HS

BO_ 599 USDT_Req_to_MCP_HS: 8 TestTool_HS
 SG_ DgnInf : 7|64@0+ (1,0) [0|1.8446744074e+19] ""  TCP_HS,ONSTAR_HS,CGM_HS,HMIM_HS,TTPM_HS,MCP_A_HS,MCP_HS

BO_ 598 USDT_Req_to_TCCM_HS: 8 TestTool_HS
 SG_ DgnInf : 7|64@0+ (1,0) [0|1.8446744074e+19] ""  TCP_HS,ONSTAR_HS,CGM_HS,HMIM_HS,TCCM_HS

BO_ 595 USDT_Req_to_AMP_HS: 8 TestTool_HS
 SG_ DgnInf : 7|64@0+ (1,0) [0|1.8446744074e+19] ""  TCP_HS,ONSTAR_HS,HMIM_HS,CGM_HS,AMP_HS

BO_ 594 USDT_Req_to_HMIM_HS: 8 TestTool_HS
 SG_ DgnInf : 7|64@0+ (1,0) [0|1.8446744074e+19] ""  TCP_HS,ONSTAR_HS,CGM_HS,AMM_HS,CSM_HS,HMIM_HS

BO_ 593 USDT_Req_to_Free_51_HS: 8 TestTool_HS
 SG_ DgnInf : 7|64@0+ (1,0) [0|1.8446744074e+19] ""  TCP_HS,ONSTAR_HS,CGM_HS,HMIM_HS,Dummy_HS

BO_ 1280 Wheel_Pulses_HS: 4 EBCM_HS
 SG_ TireRRLowTracIO : 22|1@0+ (1,0) [0|1] ""  EOCM2B_K1_HS,EOCM2A_K1_HS,CGM_HS,BCM_HS
 SG_ TireRFLowTracIO : 21|1@0+ (1,0) [0|1] ""  EOCM2B_K1_HS,EOCM2A_K1_HS,CGM_HS,BCM_HS
 SG_ TireLRLowTracIO : 20|1@0+ (1,0) [0|1] ""  EOCM2B_K1_HS,EOCM2A_K1_HS,CGM_HS,BCM_HS
 SG_ TireLFLowTracIO : 19|1@0+ (1,0) [0|1] ""  EOCM2B_K1_HS,EOCM2A_K1_HS,CGM_HS,BCM_HS
 SG_ WhlRotStatTmstmpRes : 18|11@0+ (0.002,0) [0|4.094] "uSec"  V2V_HS,CSM_HS,FCM_HS,TRCM_HS,EOCM2B_K1_HS,EOCM2A_K1_HS,CGM_HS,RDCM_HS,EPB_HS,HMIM_HS,TCCM_HS,BCM_HS,VES_HS,EPS_HS,EOCM_F_HS,ICCM_B_HS,ICCM_OBD_HS,ICCM_HS
 SG_ WhlPlsPerRevNonDrvn : 14|7@0+ (1,0) [0|127] ""  V2V_HS,CSM_HS,FCM_HS,EOCM2B_K1_HS,EOCM2A_K1_HS,CGM_HS,ICCM_B_HS,ICCM_OBD_HS,ICCM_HS,HMIM_HS,TCCM_HS,EOCM_F_HS,VES_HS,EPS_HS,RDCM_HS,EPB_HS,ACC_HS,BCM_HS,SADS_HS,TCP_HS,ONSTAR_HS
 SG_ WhlPlsPerRevDrvn : 6|7@0+ (1,0) [0|127] ""  V2V_HS,CSM_HS,FCM_HS,TRCM_HS,EOCM2B_K1_HS,EOCM2A_K1_HS,CGM_HS,ICCM_B_HS,ICCM_OBD_HS,ICCM_HS,HMIM_HS,TCCM_HS,EOCM_F_HS,VES_HS,EPS_HS,RDCM_HS,TCP_HS,ONSTAR_HS,ACC_HS,BCM_HS,EPB_HS,SADS_HS

BO_ 190 PTEI_Brake_Apply_Status: 6 ECM_HS
 SG_ EngSpdMaxCapRdcdRng : 26|10@0+ (8,0) [0|8184] "rpm"  CGM_HS,TCM_HS
 SG_ PTSnsdBrkPdlInfPVal : 32|9@0+ (1,0) [0|511] ""  EOCM2B_K1_HS,EOCM2A_K1_HS,CGM_HS,FCM_HS,EOCM_F_HS,PTO_HS,EBCM_OBD_HS,EBCM_HS,EBOOST_OBD_HS,ICCM_B_HS,ICCM_OBD_HS,ICCM_HS
 SG_ TrnsAuxPmpAct : 1|1@0+ (1,0) [0|1] ""  CGM_HS,TCM_HS
 SG_ AccPos : 23|8@0+ (0.392157,0) [0|100.000035] "%"  CGM_HS,BCP_HS,FICM_HS,TCM_HS,TCCM_HS
 SG_ PTSnsdBrkPdlInfARC : 3|2@0+ (1,0) [0|3] ""  EOCM2B_K1_HS,EOCM2A_K1_HS,CGM_HS,FCM_HS,EOCM_F_HS,PTO_HS,EBCM_OBD_HS,EBCM_HS,EBOOST_OBD_HS,ICCM_B_HS,ICCM_OBD_HS,ICCM_HS
 SG_ PSBPI_PTSnBrkPdlPsV : 0|1@0+ (1,0) [0|1] ""  EOCM2B_K1_HS,EOCM2A_K1_HS,FCM_HS,CGM_HS,PTO_HS,EOCM_F_HS,EBCM_OBD_HS,EBCM_HS,EBOOST_OBD_HS,ICCM_B_HS,ICCM_OBD_HS,ICCM_HS,TCM_HS
 SG_ PSBPI_PTSnBrkPdlPs : 15|8@0+ (0.392157,0) [0|100.000035] "%"  EOCM2B_K1_HS,EOCM2A_K1_HS,FCM_HS,CGM_HS,PTO_HS,EOCM_F_HS,EBCM_OBD_HS,EBCM_HS,EBOOST_OBD_HS,ICCM_B_HS,ICCM_OBD_HS,ICCM_HS,TCM_HS

BO_ 1361 UUDT_Resp_From_Free_51_HS: 8 Dummy_HS
 SG_ DgnInf_HS551 : 7|64@0+ (1,0) [0|1.8446744074e+19] ""  HMIM_HS,CSM_HS,CGM_HS,TCP_HS,ONSTAR_HS,TestTool_HS

BO_ 1345 UUDT_Resp_From_BCM_HS: 8 BCM_HS
 SG_ DgnInf_HS541 : 7|64@0+ (1,0) [0|1.8446744074e+19] ""  HMIM_HS,CSM_HS,CGM_HS,TCP_HS,ONSTAR_HS,TestTool_HS

BO_ 322 Lighting_Customization_Rqst_1_HS: 7 BCM_HS
 SG_ TCSTmpDsblReqConf : 23|2@0+ (1,0) [0|3] ""  EBCM_OBD_HS,EBCM_HS,CGM_HS
 SG_ VehStbCmptvMdCurStRq : 15|2@0+ (1,0) [0|3] ""  EBCM_OBD_HS,EBCM_HS,CGM_HS
 SG_ RtLnChngThrtAprchSpd : 47|8@0- (1,0) [-128|127] "km/h"  AHL_AFL_HS,CGM_HS
 SG_ LfLnChngThrtAprchSpd : 39|8@0- (1,0) [-128|127] "km/h"  AHL_AFL_HS,CGM_HS
 SG_ RgtLnChgThrt : 7|1@0+ (1,0) [0|1] ""  AHL_AFL_HS,CGM_HS
 SG_ LftLnChgThrt : 6|1@0+ (1,0) [0|1] ""  AHL_AFL_HS,CGM_HS
 SG_ IntDimLvl : 55|8@0+ (0.392157,0) [0|100.000035] "%"  ICCM_B_HS,ECM_HS,CGM_HS,ICCM_HS,EBCM_OBD_HS,EBCM_HS
 SG_ AFLGPSCstStReq : 26|3@0+ (1,0) [0|7] ""  CGM_HS,AHL_AFL_HS
 SG_ AFLCstStReq : 29|3@0+ (1,0) [0|7] ""  CGM_HS,AHL_AFL_HS
 SG_ LtRtHnTrCstStReq : 5|3@0+ (1,0) [0|7] ""  CGM_HS,AHL_AFL_HS
 SG_ AdpHgBmAsSnCsStRq : 18|3@0+ (1,0) [0|7] ""  CGM_HS,AHL_AFL_HS
 SG_ AdpHgBmAstCstStRq : 21|3@0+ (1,0) [0|7] ""  CGM_HS,AHL_AFL_HS
 SG_ LtRtHnTrGPSCstStRq : 2|3@0+ (1,0) [0|7] ""  CGM_HS,AHL_AFL_HS
 SG_ AutHgBmAsSnCsStRq : 10|3@0+ (1,0) [0|7] ""  CGM_HS,AHL_AFL_HS
 SG_ AutHgBmAstCstStRq : 13|3@0+ (1,0) [0|7] ""  CGM_HS,AHL_AFL_HS
 SG_ HtVwAutnmsEPBAplyReqd : 30|1@0+ (1,0) [0|1] ""  CGM_HS,EBCM_OBD_HS,EBCM_HS

BO_ 1608 USDT_Resp_From_Free_48_HS: 8 Dummy_HS
 SG_ DgnInf : 7|64@0+ (1,0) [0|1.8446744074e+19] ""  HMIM_HS,CSM_HS,CGM_HS,TCP_HS,ONSTAR_HS,TestTool_HS

BO_ 534 Damper_Information_HS: 2 SADS_HS
 SG_ DmpSysVehTopSpdLim : 15|8@0+ (2,0) [0|510] "km / h"  EOCM2B_K1_HS,EOCM2A_K1_HS,CGM_HS,BCM_HS
 SG_ SrvSuspSysIO : 0|1@0+ (1,0) [0|1] ""  EOCM2B_K1_HS,EOCM2A_K1_HS,CGM_HS,EDI_HS,TCP_HS,ONSTAR_HS,BCM_HS

BO_ 309 Body_Information_2_HS: 8 BCM_HS
 SG_ PedFrndlyAlrtSndMnAct : 8|1@0+ (1,0) [0|1] ""  CGM_HS,PFAF_HS
 SG_ StBltTgtCSRq : 23|3@0+ (1,0) [0|7] ""  EOCM2B_IMX6_HS,EOCM2A_IMX6_HS,EOCM2B_K1_HS,EOCM2A_K1_HS,CGM_HS,EBCM_OBD_HS,EBCM_HS
 SG_ ColPrSysCustReq : 15|3@0+ (1,0) [0|7] ""  EOCM2B_IMX6_HS,EOCM2A_IMX6_HS,EOCM2B_K1_HS,EOCM2A_K1_HS,FCM_HS,CGM_HS,ACC_HS,EOCM_F_HS
 SG_ SecV : 62|1@0+ (1,0) [0|1] ""  EOCM2B_IMX6_HS,EOCM2A_IMX6_HS,EOCM2B_K1_HS,EOCM2A_K1_HS,CGM_HS,ACC_HS
 SG_ Sec : 61|6@0+ (1,0) [0|63] "s"  EOCM2B_IMX6_HS,EOCM2A_IMX6_HS,EOCM2B_K1_HS,EOCM2A_K1_HS,CGM_HS,ACC_HS
 SG_ CldrYr_154 : 55|8@0+ (1,2000) [2000|2255] "year"  EOCM2B_IMX6_HS,EOCM2A_IMX6_HS,EOCM2B_K1_HS,EOCM2A_K1_HS,CGM_HS,ACC_HS
 SG_ CldrYr : 47|8@0+ (1,2000) [2000|2255] "year"  EOCM2B_K1_HS,EOCM2A_K1_HS,CGM_HS,EBCM_OBD_HS,EBCM_HS,ACC_HS
 SG_ CldrMth_154 : 39|4@0+ (1,0) [0|15] ""  EOCM2B_K1_HS,EOCM2A_K1_HS,CGM_HS,ACC_HS
 SG_ CldrMth : 35|4@0+ (1,0) [0|15] ""  EOCM2B_IMX6_HS,EOCM2A_IMX6_HS,EOCM2B_K1_HS,EOCM2A_K1_HS,EBCM_OBD_HS,EBCM_HS,CGM_HS,ACC_HS
 SG_ CldrDay_154 : 30|5@0+ (1,0) [0|31] "days"  EOCM2B_K1_HS,EOCM2A_K1_HS,CGM_HS,ACC_HS
 SG_ CldrDay : 20|5@0+ (1,0) [0|31] "days"  EOCM2B_IMX6_HS,EOCM2A_IMX6_HS,EOCM2B_K1_HS,EOCM2A_K1_HS,EBCM_OBD_HS,EBCM_HS,CGM_HS,ACC_HS
 SG_ AutoHiBmVDA : 25|1@0+ (1,0) [0|1] ""  EOCM2B_IMX6_HS,EOCM2A_IMX6_HS,EOCM2B_K1_HS,EOCM2A_K1_HS,CGM_HS,AHL_AFL_HS
 SG_ CtLghtDet : 24|1@0+ (1,0) [0|1] ""  EOCM2B_IMX6_HS,EOCM2A_IMX6_HS,EOCM2B_K1_HS,EOCM2A_K1_HS,CGM_HS,AHL_AFL_HS
 SG_ RrClosVDA : 11|1@0+ (1,0) [0|1] ""  EOCM2B_IMX6_HS,EOCM2A_IMX6_HS,EOCM2B_K1_HS,EOCM2A_K1_HS,CGM_HS,ICCM_B_HS,ICCM_OBD_HS,ICCM_HS,ALC_HS,SADS_HS
 SG_ TCSysDisSwAtv : 4|1@0+ (1,0) [0|1] ""  EOCM2B_IMX6_HS,EOCM2A_IMX6_HS,EOCM2B_K1_HS,EOCM2A_K1_HS,CGM_HS,EBCM_OBD_HS,EBCM_HS
 SG_ VehMovState : 2|3@0+ (1,0) [0|7] ""  EOCM2B_IMX6_HS,EOCM2A_IMX6_HS,TTPM_HS,CSM_HS,EOCM2B_K1_HS,EOCM2A_K1_HS,CGM_HS,HMIM_HS,EBCM_OBD_HS,EBCM_HS,RDCM_HS,FCM_HS,SADS_HS,AHL_AFL_HS
 SG_ TCSysDisSwAtvV : 3|1@0+ (1,0) [0|1] ""  EOCM2B_IMX6_HS,EOCM2A_IMX6_HS,EOCM2B_K1_HS,EOCM2A_K1_HS,CGM_HS,EBCM_OBD_HS,EBCM_HS
 SG_ HillDesCtrlMdSwActV : 10|1@0+ (1,0) [0|1] ""  EOCM2B_IMX6_HS,EOCM2A_IMX6_HS,EOCM2B_K1_HS,EOCM2A_K1_HS,CGM_HS,EBCM_OBD_HS,EBCM_HS
 SG_ WSWshSwAtv : 5|1@0+ (1,0) [0|1] ""  EOCM2B_IMX6_HS,EOCM2A_IMX6_HS,EOCM2B_K1_HS,EOCM2A_K1_HS,CGM_HS,EOCM_F_HS,FCM_HS,ACC_HS
 SG_ HillDesCtrlMdSwAct : 9|1@0+ (1,0) [0|1] ""  EOCM2B_IMX6_HS,EOCM2A_IMX6_HS,EOCM2B_K1_HS,EOCM2A_K1_HS,CGM_HS,EBCM_OBD_HS,EBCM_HS
 SG_ RrClosAjarSwAct : 12|1@0+ (1,0) [0|1] ""  EOCM2B_IMX6_HS,EOCM2A_IMX6_HS,EOCM2B_K1_HS,EOCM2A_K1_HS,CGM_HS,ICCM_B_HS,ICCM_OBD_HS,ICCM_HS,ALC_HS,SADS_HS
 SG_ WSWprAct : 6|1@0+ (1,0) [0|1] ""  EOCM2B_IMX6_HS,EOCM2A_IMX6_HS,ECM_HS,EOCM2B_K1_HS,EOCM2A_K1_HS,CGM_HS,FCM_HS,EOCM_F_HS,EBCM_OBD_HS,EBCM_HS,ACC_HS,AHL_AFL_HS

BO_ 1922 DTC_Triggered_782: 7 Dummy_HS
 SG_ DTCI_WrnIndRqdSt_782 : 47|1@0+ (1,0) [0|1] ""  CGM_HS,CSM_HS,HMIM_HS,TCP_HS,VLBS_HS,ONSTAR_HS
 SG_ DTCIUnused7_782 : 1|1@0+ (1,0) [0|1] ""  CGM_HS,CSM_HS,HMIM_HS,TCP_HS,VLBS_HS,ONSTAR_HS
 SG_ DTCIUnused6_782 : 2|1@0+ (1,0) [0|1] ""  CGM_HS,CSM_HS,HMIM_HS,TCP_HS,VLBS_HS,ONSTAR_HS
 SG_ DTCIUnused5_782 : 3|1@0+ (1,0) [0|1] ""  CGM_HS,CSM_HS,HMIM_HS,TCP_HS,VLBS_HS,ONSTAR_HS
 SG_ DTCIUnused4_782 : 4|1@0+ (1,0) [0|1] ""  CGM_HS,CSM_HS,HMIM_HS,TCP_HS,VLBS_HS,ONSTAR_HS
 SG_ DTCIUnused3_782 : 5|1@0+ (1,0) [0|1] ""  CGM_HS,CSM_HS,HMIM_HS,TCP_HS,VLBS_HS,ONSTAR_HS
 SG_ DTCIUnused2_782 : 6|1@0+ (1,0) [0|1] ""  CGM_HS,CSM_HS,HMIM_HS,TCP_HS,VLBS_HS,ONSTAR_HS
 SG_ DTCIUnused1_782 : 7|1@0+ (1,0) [0|1] ""  CGM_HS,CSM_HS,HMIM_HS,TCP_HS,VLBS_HS,ONSTAR_HS
 SG_ DTCI_TstNPsdPwrUpSt_782 : 45|1@0+ (1,0) [0|1] ""  CGM_HS,CSM_HS,HMIM_HS,TCP_HS,VLBS_HS,ONSTAR_HS
 SG_ DTCI_TstNPsdCdClrdSt_782 : 42|1@0+ (1,0) [0|1] ""  CGM_HS,CSM_HS,HMIM_HS,TCP_HS,VLBS_HS,ONSTAR_HS
 SG_ DTCI_TstFldPwrUpSt_782 : 46|1@0+ (1,0) [0|1] ""  CGM_HS,CSM_HS,HMIM_HS,TCP_HS,VLBS_HS,ONSTAR_HS
 SG_ DTCI_TstFldCdClrdStat_782 : 43|1@0+ (1,0) [0|1] ""  CGM_HS,CSM_HS,HMIM_HS,TCP_HS,VLBS_HS,ONSTAR_HS
 SG_ DTCI_HistStat_782 : 44|1@0+ (1,0) [0|1] ""  CGM_HS,CSM_HS,HMIM_HS,TCP_HS,VLBS_HS,ONSTAR_HS
 SG_ DTCI_DTCTriggered_782 : 0|1@0+ (1,0) [0|1] ""  CGM_HS,CSM_HS,HMIM_HS,TCP_HS,VLBS_HS,ONSTAR_HS
 SG_ DTCI_DTCSource_782 : 15|8@0+ (1,0) [0|255] ""  CGM_HS,CSM_HS,HMIM_HS,TCP_HS,VLBS_HS,ONSTAR_HS
 SG_ DTCI_DTCNumber_782 : 23|16@0+ (1,0) [0|65535] ""  CGM_HS,CSM_HS,HMIM_HS,TCP_HS,VLBS_HS,ONSTAR_HS
 SG_ DTCI_DTCFaultType_782 : 55|8@0+ (1,0) [0|255] ""  CGM_HS,CSM_HS,HMIM_HS,TCP_HS,VLBS_HS,ONSTAR_HS
 SG_ DTCI_DTCFailType_782 : 39|8@0+ (1,0) [0|255] ""  CGM_HS,CSM_HS,HMIM_HS,TCP_HS,VLBS_HS,ONSTAR_HS
 SG_ DTCI_CurrentStatus_782 : 41|1@0+ (1,0) [0|1] ""  CGM_HS,CSM_HS,HMIM_HS,TCP_HS,VLBS_HS,ONSTAR_HS
 SG_ DTCI_CodeSupported_782 : 40|1@0+ (1,0) [0|1] ""  CGM_HS,CSM_HS,HMIM_HS,TCP_HS,VLBS_HS,ONSTAR_HS

BO_ 352 Immobilizer_Identifier_HS: 5 BCM_HS
 SG_ ShfFrmPrkAlwd : 36|1@0+ (1,0) [0|1] ""  ECM_HS,ICCM_HS,CGM_HS
 SG_ AVHSwtchStats : 35|1@0+ (1,0) [0|1] ""  CGM_HS,EBCM_OBD_HS,EBCM_HS
 SG_ SmrtHgBmAstCstCurrSetVal : 39|3@0+ (1,0) [0|7] ""  AHL_AFL_HS,CGM_HS
 SG_ TeenDrvAct : 34|1@0+ (1,0) [0|1] ""  CGM_HS,ALC_HS,EBCM_OBD_HS,EBCM_HS,AHL_AFL_HS,ACC_HS
 SG_ LrnEnvIdSt : 32|1@0+ (1,0) [0|1] ""  CGM_HS,TCP_HS,VLBS_HS,ONSTAR_HS,EBCM_OBD_HS,EBCM_HS
 SG_ LrnEnvId : 23|16@0+ (1,0) [0|65535] ""  CGM_HS,TCP_HS,VLBS_HS,ONSTAR_HS,EBCM_OBD_HS,EBCM_HS
 SG_ ImoId : 7|16@0+ (1,0) [0|65535] ""  CGM_HS,TCP_HS,VLBS_HS,ONSTAR_HS,EBCM_OBD_HS,EBCM_HS
 SG_ ImoIdSt : 33|1@0+ (1,0) [0|1] ""  CGM_HS,TCP_HS,VLBS_HS,ONSTAR_HS,EBCM_OBD_HS,EBCM_HS

BO_ 562 Driving_Mode_Control_HS: 8 EBCM_HS
 SG_ BrkSysAutBrkStat : 52|2@0+ (1,0) [0|3] ""  FCM_HS,CGM_HS
 SG_ FSRACCBrkngReqDenied : 46|1@0+ (1,0) [0|1] ""  FCM_HS,CGM_HS
 SG_ BrkSysExtHldCpbltyFld : 47|1@0+ (1,0) [0|1] ""  FCM_HS,CGM_HS
 SG_ SndPerfMdCsStAvl : 63|1@0+ (1,0) [0|1] ""  EOCM2B_IMX6_HS,EOCM2A_IMX6_HS,EOCM2B_K1_HS,EOCM2A_K1_HS,CGM_HS,BCM_HS
 SG_ SndPerfMdCsCrStVal : 62|3@0+ (1,0) [0|7] ""  EOCM2B_IMX6_HS,EOCM2A_IMX6_HS,EOCM2B_K1_HS,EOCM2A_K1_HS,CGM_HS,BCM_HS
 SG_ DispPerfMdCsStAvl : 59|1@0+ (1,0) [0|1] ""  EOCM2B_IMX6_HS,EOCM2A_IMX6_HS,EOCM2B_K1_HS,EOCM2A_K1_HS,CGM_HS,BCM_HS
 SG_ DispPerfMdCsCrStVal : 58|3@0+ (1,0) [0|7] ""  EOCM2B_IMX6_HS,EOCM2A_IMX6_HS,EOCM2B_K1_HS,EOCM2A_K1_HS,CGM_HS,BCM_HS
 SG_ DrvlneMntsPerfMdRq : 50|3@0+ (1,0) [0|7] ""  EOCM2B_IMX6_HS,EOCM2A_IMX6_HS,ECM_HS,EOCM2B_K1_HS,EOCM2A_K1_HS,CGM_HS,Dummy_HS,ICCM_B_HS,ICCM_OBD_HS,ICCM_HS
 SG_ RideCntrlPerfMdRq : 18|3@0+ (1,0) [0|7] ""  EOCM2B_IMX6_HS,EOCM2A_IMX6_HS,EOCM2B_K1_HS,EOCM2A_K1_HS,CGM_HS,EDI_HS,SADS_HS
 SG_ StgSysPerfMdRq : 29|3@0+ (1,0) [0|7] ""  EOCM2B_IMX6_HS,EOCM2A_IMX6_HS,EOCM2B_K1_HS,EOCM2A_K1_HS,EOCM_F_HS,FCM_HS,CGM_HS,EDI_HS,VES_HS,EPS_HS
 SG_ DiffPerfMdRq : 26|3@0+ (1,0) [0|7] ""  EOCM2B_IMX6_HS,EOCM2A_IMX6_HS,EOCM2B_K1_HS,EOCM2A_K1_HS,CGM_HS,ICCM_B_HS,ICCM_OBD_HS,ICCM_HS
 SG_ SndEnhcmtPerfMdRq : 13|3@0+ (1,0) [0|7] ""  EOCM2B_IMX6_HS,EOCM2A_IMX6_HS,EOCM2B_K1_HS,EOCM2A_K1_HS,CGM_HS,BCM_HS,AMP_HS
 SG_ DsplyPerfMdRq : 10|3@0+ (1,0) [0|7] ""  EOCM2B_IMX6_HS,EOCM2A_IMX6_HS,EOCM2B_K1_HS,EOCM2A_K1_HS,CGM_HS,EDI_HS,BCM_HS
 SG_ ExhstPerfMdRq : 5|3@0+ (1,0) [0|7] ""  EOCM2B_IMX6_HS,EOCM2A_IMX6_HS,EOCM2B_K1_HS,EOCM2A_K1_HS,CGM_HS,ICCM_B_HS,ICCM_OBD_HS,ICCM_HS
 SG_ HillDscntCntlSysStat : 55|3@0+ (1,0) [0|7] ""  EOCM2B_IMX6_HS,EOCM2A_IMX6_HS,EOCM2B_K1_HS,EOCM2A_K1_HS,CGM_HS,BCM_HS
 SG_ SusCustStngAvlbl : 23|1@0+ (1,0) [0|1] ""  EOCM2B_IMX6_HS,EOCM2A_IMX6_HS,EOCM2B_K1_HS,EOCM2A_K1_HS,CGM_HS,TCP_HS,ONSTAR_HS,BCM_HS
 SG_ SusCustCurrStngVal : 45|3@0+ (1,0) [0|7] ""  EOCM2B_IMX6_HS,EOCM2A_IMX6_HS,EOCM2B_K1_HS,EOCM2A_K1_HS,CGM_HS,TCP_HS,ONSTAR_HS,BCM_HS
 SG_ StrCustStngAvlbl : 7|1@0+ (1,0) [0|1] ""  EOCM2B_IMX6_HS,EOCM2A_IMX6_HS,EOCM2B_K1_HS,EOCM2A_K1_HS,CGM_HS,TCP_HS,ONSTAR_HS,BCM_HS
 SG_ StrCustCurrStngVal : 42|3@0+ (1,0) [0|7] ""  EOCM2B_IMX6_HS,EOCM2A_IMX6_HS,EOCM2B_K1_HS,EOCM2A_K1_HS,CGM_HS,TCP_HS,ONSTAR_HS,BCM_HS
 SG_ DrvlnCustStngAvlbl : 6|1@0+ (1,0) [0|1] ""  EOCM2B_IMX6_HS,EOCM2A_IMX6_HS,EOCM2B_K1_HS,EOCM2A_K1_HS,CGM_HS,TCP_HS,ONSTAR_HS,BCM_HS
 SG_ DrvMdCntrlState : 39|8@0+ (1,0) [0|255] ""  EOCM2B_IMX6_HS,EOCM2A_IMX6_HS,EOCM2B_K1_HS,EOCM2A_K1_HS,CGM_HS,EOCM_F_HS,FCM_HS,VES_HS,EPS_HS,RDCM_HS,SADS_HS
 SG_ AWDPerfMdRq : 2|3@0+ (1,0) [0|7] ""  EOCM2B_IMX6_HS,EOCM2A_IMX6_HS,EOCM2B_K1_HS,EOCM2A_K1_HS,CGM_HS,RDCM_HS,TCCM_HS
 SG_ DrvlnCustCurrStngVal : 22|3@0+ (1,0) [0|7] ""  EOCM2B_IMX6_HS,EOCM2A_IMX6_HS,EOCM2B_K1_HS,EOCM2A_K1_HS,CGM_HS,TCP_HS,ONSTAR_HS,BCM_HS

BO_ 893 Lighting_Customization_Info_3_HS: 2 AHL_AFL_HS
 SG_ AFLMnu3CstStAvl : 10|1@0+ (1,0) [0|1] ""  BCM_HS
 SG_ AFLMnu2CstStAvl : 9|1@0+ (1,0) [0|1] ""  BCM_HS
 SG_ AFLGPSMnu2CstStAvl : 8|1@0+ (1,0) [0|1] ""  BCM_HS
 SG_ AFLGPSCstStAvl : 6|1@0+ (1,0) [0|1] ""  BCM_HS
 SG_ AFLGPSCstCrStVal : 2|3@0+ (1,0) [0|7] ""  BCM_HS
 SG_ AFLCstStAvl : 7|1@0+ (1,0) [0|1] ""  BCM_HS
 SG_ AFLCstCrStVal : 5|3@0+ (1,0) [0|7] ""  BCM_HS

BO_ 892 Lighting_Customization_Info_2_HS: 2 AHL_AFL_HS
 SG_ AdpHgBmAsSnCsCrStVal : 13|3@0+ (1,0) [0|7] ""  BCM_HS
 SG_ AdpHgBmAsSnCsStAvl : 15|1@0+ (1,0) [0|1] ""  BCM_HS
 SG_ AdpHgBmAsCsCrStVal : 10|3@0+ (1,0) [0|7] ""  BCM_HS
 SG_ AdpHgBmAsCsStAvl : 14|1@0+ (1,0) [0|1] ""  BCM_HS
 SG_ AutHgBmAsCsCrStVal : 2|3@0+ (1,0) [0|7] ""  BCM_HS
 SG_ AutHgBmAsSnCsStAvl : 7|1@0+ (1,0) [0|1] ""  BCM_HS
 SG_ AutHgBmAsSnCsCrStVa : 5|3@0+ (1,0) [0|7] ""  BCM_HS
 SG_ AutHgBmAsCsStAvl : 6|1@0+ (1,0) [0|1] ""  BCM_HS

BO_ 386 Environment_Id_Resp_4_HS: 8 EBCM_HS
 SG_ AHAct : 31|1@0+ (1,0) [0|1] ""  EOCM2B_IMX6_HS,EOCM2A_IMX6_HS,CGM_HS,EOCM2B_K1_HS,EOCM2A_K1_HS,BCM_HS
 SG_ AHEnbld : 30|1@0+ (1,0) [0|1] ""  EOCM2B_IMX6_HS,EOCM2A_IMX6_HS,CGM_HS,EOCM2B_K1_HS,EOCM2A_K1_HS,BCM_HS
 SG_ ShfToPrkBfExtngIO : 29|1@0+ (1,0) [0|1] ""  EOCM2B_IMX6_HS,EOCM2A_IMX6_HS,CGM_HS,EOCM2B_K1_HS,EOCM2A_K1_HS,BCM_HS
 SG_ AHServcIO : 28|1@0+ (1,0) [0|1] ""  EOCM2B_IMX6_HS,EOCM2A_IMX6_HS,CGM_HS,EOCM2B_K1_HS,EOCM2A_K1_HS,BCM_HS
 SG_ AHAppBrkPedlIO : 27|1@0+ (1,0) [0|1] ""  EOCM2B_IMX6_HS,EOCM2A_IMX6_HS,CGM_HS,EOCM2B_K1_HS,EOCM2A_K1_HS,BCM_HS
 SG_ AHDisbldStbltIO : 26|1@0+ (1,0) [0|1] ""  EOCM2B_IMX6_HS,EOCM2A_IMX6_HS,CGM_HS,EOCM2B_K1_HS,EOCM2A_K1_HS,BCM_HS
 SG_ AHDisbldDrOpnIO : 25|1@0+ (1,0) [0|1] ""  EOCM2B_IMX6_HS,EOCM2A_IMX6_HS,CGM_HS,EOCM2B_K1_HS,EOCM2A_K1_HS,BCM_HS
 SG_ PMVSS_Disps : 58|3@0+ (1,0) [0|7] ""  EOCM2B_IMX6_HS,EOCM2A_IMX6_HS,CGM_HS,EOCM2B_K1_HS,EOCM2A_K1_HS,BCM_HS
 SG_ PMVSS_Exhst : 61|3@0+ (1,0) [0|7] ""  EOCM2B_IMX6_HS,EOCM2A_IMX6_HS,CGM_HS,EOCM2B_K1_HS,EOCM2A_K1_HS,BCM_HS
 SG_ PMVSS_PsngrSeat : 48|3@0+ (1,0) [0|7] ""  EOCM2B_IMX6_HS,EOCM2A_IMX6_HS,CGM_HS,EOCM2B_K1_HS,EOCM2A_K1_HS,BCM_HS
 SG_ PMVSS_DrvrSeat : 51|3@0+ (1,0) [0|7] ""  EOCM2B_IMX6_HS,EOCM2A_IMX6_HS,CGM_HS,EOCM2B_K1_HS,EOCM2A_K1_HS,BCM_HS
 SG_ PMVSS_AdptCrsCnt : 54|3@0+ (1,0) [0|7] ""  EOCM2B_IMX6_HS,EOCM2A_IMX6_HS,CGM_HS,EOCM2B_K1_HS,EOCM2A_K1_HS,BCM_HS
 SG_ PMVSS_Drvln : 41|3@0+ (1,0) [0|7] ""  EOCM2B_IMX6_HS,EOCM2A_IMX6_HS,CGM_HS,EOCM2B_K1_HS,EOCM2A_K1_HS,BCM_HS
 SG_ PMVSS_Susp : 44|3@0+ (1,0) [0|7] ""  EOCM2B_IMX6_HS,EOCM2A_IMX6_HS,CGM_HS,EOCM2B_K1_HS,EOCM2A_K1_HS,BCM_HS
 SG_ PMVSS_Strng : 47|3@0+ (1,0) [0|7] ""  EOCM2B_IMX6_HS,EOCM2A_IMX6_HS,CGM_HS,EOCM2B_K1_HS,EOCM2A_K1_HS,BCM_HS
 SG_ PMVSS_Trans : 34|3@0+ (1,0) [0|7] ""  EOCM2B_IMX6_HS,EOCM2A_IMX6_HS,CGM_HS,EOCM2B_K1_HS,EOCM2A_K1_HS,BCM_HS
 SG_ PMVSS_Eng : 37|3@0+ (1,0) [0|7] ""  EOCM2B_IMX6_HS,EOCM2A_IMX6_HS,CGM_HS,EOCM2B_K1_HS,EOCM2A_K1_HS,BCM_HS
 SG_ PMVSS_Snd : 24|3@0+ (1,0) [0|7] ""  EOCM2B_IMX6_HS,EOCM2A_IMX6_HS,CGM_HS,EOCM2B_K1_HS,EOCM2A_K1_HS,BCM_HS
 SG_ AdptCruzCtrlStg : 20|3@0+ (1,0) [0|7] ""  EOCM2B_IMX6_HS,EOCM2A_IMX6_HS,FCM_HS,CGM_HS,EOCM2B_K1_HS,EOCM2A_K1_HS,EOCM_F_HS,ACC_HS
 SG_ AWDRecmndIO : 21|1@0+ (1,0) [0|1] ""  CGM_HS,BCM_HS
 SG_ EnvIdRsp4 : 7|16@0+ (1,0) [0|65535] ""  EOCM2B_IMX6_HS,EOCM2A_IMX6_HS,CGM_HS,EOCM2B_K1_HS,EOCM2A_K1_HS,BCM_HS
 SG_ EnvIdRspSt4 : 17|2@0+ (1,0) [0|3] ""  EOCM2B_IMX6_HS,EOCM2A_IMX6_HS,CGM_HS,EOCM2B_K1_HS,EOCM2A_K1_HS,BCM_HS

BO_ 597 USDT_Req_to_TRCM_HS: 8 TestTool_HS
 SG_ DgnInf : 7|64@0+ (1,0) [0|1.8446744074e+19] ""  TCP_HS,ONSTAR_HS,CGM_HS,HMIM_HS,TRCM_HS

BO_ 1621 USDT_Resp_From_TRCM_HS: 8 TRCM_HS
 SG_ DgnInf : 7|64@0+ (1,0) [0|1.8446744074e+19] ""  HMIM_HS,CSM_HS,CGM_HS,TCP_HS,ONSTAR_HS,TestTool_HS

BO_ 532 Brake_Pedal_Driver_Status_HS: 6 EBCM_HS
 SG_ RedntVSEActARC : 38|2@0+ (1,0) [0|3] ""  EOCM2B_K2_HS,EOCM2A_K2_HS,EOCM2B_K1_HS,EOCM2A_K1_HS,CGM_HS,EPS_HS,ICCM_B_HS,ICCM_OBD_HS,ICCM_HS
 SG_ RedntVSEAct : 39|1@0+ (1,0) [0|1] ""  EOCM2B_K2_HS,EOCM2A_K2_HS,EOCM2B_K1_HS,EOCM2A_K1_HS,CGM_HS,EPS_HS,ICCM_B_HS,ICCM_OBD_HS,ICCM_HS
 SG_ AutoBrkngActARC : 22|2@0+ (1,0) [0|3] ""  EOCM2B_K2_HS,EOCM2A_K2_HS,EOCM2B_K1_HS,EOCM2A_K1_HS,CGM_HS,ICCM_B_HS,ICCM_OBD_HS,ICCM_HS
 SG_ HilRlbkCtrlActIO : 19|1@0+ (1,0) [0|1] ""  EOCM2B_K2_HS,EOCM2A_K2_HS,EOCM2B_K1_HS,EOCM2A_K1_HS,CGM_HS,BCM_HS
 SG_ VehHldDrvrDsblActvFlg : 36|1@0+ (1,0) [0|1] ""  EOCM2B_K2_HS,EOCM2A_K2_HS,EOCM2B_K1_HS,EOCM2A_K1_HS,CGM_HS,EPB_HS
 SG_ ABSAutnmsBrkReqPVal : 41|2@0+ (1,0) [0|3] ""  EOCM2B_K2_HS,EOCM2A_K2_HS,V2V_HS,EOCM2B_K1_HS,EOCM2A_K1_HS,CGM_HS,EPB_HS
 SG_ AutoBrkngAvlbl : 17|1@0+ (1,0) [0|1] ""  EOCM2B_K2_HS,EOCM2A_K2_HS,V2V_HS,ECM_HS,ICCM_HS,EOCM2B_K1_HS,EOCM2A_K1_HS,FCM_HS,CGM_HS,EPS_HS,EOCM_F_HS,EPB_HS
 SG_ ABSAutnmsBrkReqARC : 35|2@0+ (1,0) [0|3] ""  EOCM2B_K2_HS,EOCM2A_K2_HS,V2V_HS,EOCM2B_K1_HS,EOCM2A_K1_HS,CGM_HS,EPB_HS
 SG_ ABSAutnmsBrkReq : 33|1@0+ (1,0) [0|1] ""  EOCM2B_K2_HS,EOCM2A_K2_HS,V2V_HS,EOCM2B_K1_HS,EOCM2A_K1_HS,CGM_HS,EPB_HS
 SG_ ABSActvProtPVal : 43|2@0+ (1,0) [0|3] ""  EOCM2B_K2_HS,EOCM2A_K2_HS,V2V_HS,EOCM2B_K1_HS,EOCM2A_K1_HS,CGM_HS,EPS_HS,EOCM_F_HS,ICCM_B_HS,ICCM_OBD_HS,ICCM_HS
 SG_ ABSActvProtARC : 45|2@0+ (1,0) [0|3] ""  EOCM2B_K2_HS,EOCM2A_K2_HS,V2V_HS,EOCM2B_K1_HS,EOCM2A_K1_HS,CGM_HS,EPS_HS,EOCM_F_HS,ICCM_B_HS,ICCM_OBD_HS,ICCM_HS
 SG_ HlStrAssActIO : 20|1@0+ (1,0) [0|1] ""  EOCM2B_K2_HS,EOCM2A_K2_HS,EOCM2B_K1_HS,EOCM2A_K1_HS,CGM_HS,BCM_HS
 SG_ ABSActvProt : 46|1@0+ (1,0) [0|1] ""  EOCM2B_K2_HS,EOCM2A_K2_HS,V2V_HS,EOCM2B_K1_HS,EOCM2A_K1_HS,CGM_HS,EPS_HS,EOCM_F_HS,ICCM_B_HS,ICCM_OBD_HS,ICCM_HS
 SG_ BrkSysAutBrkFld : 5|1@0+ (1,0) [0|1] ""  EOCM2B_K2_HS,EOCM2A_K2_HS,ECM_HS,ICCM_HS,EOCM2B_K1_HS,EOCM2A_K1_HS,FCM_HS,CGM_HS,EPB_HS,BCM_HS,ACC_HS
 SG_ IntBrkAssPreFilReq : 4|1@0+ (1,0) [0|1] "N/A"  EOCM2B_K2_HS,EOCM2A_K2_HS,EOCM2B_K1_HS,EOCM2A_K1_HS,CGM_HS,BCM_HS
 SG_ BrkSysMalFuncIndOn : 3|1@0+ (1,0) [0|1] ""  EOCM2B_K2_HS,EOCM2A_K2_HS,EOCM2B_K1_HS,EOCM2A_K1_HS,V2V_HS,CGM_HS,BCM_HS
 SG_ BrkPdDrvAPrsStaPVal : 16|9@0+ (1,0) [0|511] ""  EOCM2B_K2_HS,EOCM2A_K2_HS,V2V_HS,EOCM2B_K1_HS,EOCM2A_K1_HS,CGM_HS,FCM_HS,ACC_HS,EOCM_F_HS,ICCM_B_HS,ICCM_OBD_HS,ICCM_HS,EPB_HS,SADS_HS
 SG_ BPDAPS_BkPDrvApPV : 8|1@0+ (1,0) [0|1] ""  EOCM2B_K2_HS,EOCM2A_K2_HS,EOCM2B_K1_HS,EOCM2A_K1_HS,V2V_HS,CGM_HS,FCM_HS,EOCM_F_HS,ICCM_B_HS,ICCM_OBD_HS,ICCM_HS,BCM_HS,ACC_HS,SADS_HS,EPB_HS
 SG_ BPDAPS_BkPDrvApP : 0|8@0+ (75,0) [0|19125] "kPa"  EOCM2B_K2_HS,EOCM2A_K2_HS,EOCM2B_K1_HS,EOCM2A_K1_HS,V2V_HS,CGM_HS,FCM_HS,EOCM_F_HS,ICCM_B_HS,ICCM_OBD_HS,ICCM_HS,BCM_HS,ACC_HS,SADS_HS,EPB_HS
 SG_ BrkPdDrvAppPrsAlRC : 2|2@0+ (1,0) [0|3] ""  EOCM2B_K2_HS,EOCM2A_K2_HS,V2V_HS,EOCM2B_K1_HS,EOCM2A_K1_HS,CGM_HS,FCM_HS,ACC_HS,EOCM_F_HS,ICCM_B_HS,ICCM_OBD_HS,ICCM_HS,SADS_HS,EPB_HS
 SG_ BrkFldLvlLwV : 7|1@0+ (1,0) [0|1] ""  EOCM2B_K2_HS,EOCM2A_K2_HS,EOCM2B_K1_HS,EOCM2A_K1_HS,CGM_HS,BCM_HS
 SG_ AutoBrkngAct : 18|1@0+ (1,0) [0|1] ""  EOCM2B_K2_HS,EOCM2A_K2_HS,V2V_HS,EOCM2B_K1_HS,EOCM2A_K1_HS,CGM_HS,ICCM_B_HS,ICCM_OBD_HS,ICCM_HS,EPB_HS,ACC_HS
 SG_ BrkFldLvlLw : 6|1@0+ (1,0) [0|1] ""  EOCM2B_K2_HS,EOCM2A_K2_HS,EOCM2B_K1_HS,EOCM2A_K1_HS,CGM_HS,BCM_HS

BO_ 890 Lighting_Customization_Info_1_HS: 1 AHL_AFL_HS
 SG_ LtRtHnTrGPCsCrStVal : 5|3@0+ (1,0) [0|7] ""  BCM_HS
 SG_ LtRtHnTrGPSCsStAvl : 7|1@0+ (1,0) [0|1] ""  BCM_HS
 SG_ LtRtHnTrCstStVal : 2|3@0+ (1,0) [0|7] ""  BCM_HS
 SG_ LtRtHnTrCstStAvail : 6|1@0+ (1,0) [0|1] ""  BCM_HS

BO_ 592 USDT_Req_to_AVM_HS: 8 TestTool_HS
 SG_ DgnInf : 7|64@0+ (1,0) [0|1.8446744074e+19] ""  TCP_HS,ONSTAR_HS,CGM_HS,HMIM_HS,AVM_HS,PLCM_HS

BO_ 1365 UUDT_Resp_From_TRCM_HS: 8 TRCM_HS
 SG_ DgnInf_HS555 : 7|64@0+ (1,0) [0|1.8446744074e+19] ""  HMIM_HS,CSM_HS,CGM_HS,TCP_HS,ONSTAR_HS,TestTool_HS

BO_ 328 Power_Steering_Information_HS: 1 EPS_HS
 SG_ StrAsstRdcdLvl3IO : 3|1@0+ (1,0) [0|1] ""  CGM_HS,BCM_HS
 SG_ StrAsstRdcdLvl2IO : 2|1@0+ (1,0) [0|1] ""  CGM_HS,BCM_HS
 SG_ StrngAsstRdcdIO : 1|1@0+ (1,0) [0|1] ""  EOCM2B_K1_HS,CGM_HS,EOCM2A_K1_HS,BCM_HS
 SG_ PwrStrIO : 0|1@0+ (1,0) [0|1] ""  EOCM2B_K1_HS,CGM_HS,EOCM2A_K1_HS,BCM_HS,EPB_HS

CM_ SG_ 949 AltFuelEqvlntRatBsOffst "Units = Equivalence Ratio";
CM_ SG_ 544 PTORelBrkPedIO "Power Take Off Release Brake Pedal To Engage Indication On";
CM_ SG_ 979 BrkBstVac "0 kPA represents the sensor reading atmospheric pressure";
CM_ SG_ 1239 BatSOH "State of Health = the aging state of the Battery";
CM_ SG_ 398 EngNTrnsRegStdyStTqV "ETEI 3.1";
CM_ SG_ 398 EngNTrnsRegStdyStTq "ETEI 3.1";
CM_ SG_ 398 EngActStdyStTorq "ETEI 3.1";
CM_ SG_ 398 EngActStdyStTorqV "ETEI 3.1";
CM_ SG_ 390 HybDFCOReq "DFCO = Deceleration Fuel Cut Off";
CM_ BO_ 719 "Application Is Tx ing this frame at the rate of 40 ms";
CM_ BO_ 869 "Note that the ACC and EBCM algorithm will transmit this message at a 50 ms periodic rate and the EOCM algorithm will transmit this message at a 40 ms periodic rate";
CM_ BO_ 717 "Note that the ACC algorithm will transmit this message at a 50 ms periodic rate and the EOCM algorithm will transmit this message at a 40 ms periodic rate";
CM_ SG_ 311 PsngSysHding "The 'usable' range is somewhat less than the encoded range (0.0 to 359.9 degrees).  0.0 degrees represents North, 90.0 degrees represents East.";
CM_ SG_ 810 PsngSysLong "The units of the data are milli-arcseconds (1/3,600,000 of a degree).  The actual 'usable' range of this data is somewhat less than the encoded range (+/- 648,000,000, corresponding to +/- 180 degrees)";
CM_ SG_ 810 PsngSysLat "The units of the data are milli-arcseconds (1/3,600,000 of a degree).  The actual 'usable' range of this data is somewhat less than the encoded range (+/- 324,000,000, corresponding to +/- 90 degrees)";
CM_ SG_ 953 DslPartFltrClngAlgActM "Diesel signal could be shared with a Gasoline application";
CM_ SG_ 953 DslPartFltrClngAlgAct "Diesel signal could be shared with a Gasoline application";
CM_ SG_ 1005 EnhSvVehTopSpdLimP "4 ASCII characters";
CM_ SG_ 431 TDslPrtFltrIdlRgtnMdAtv "Diesel signal could be shared with a Gasoline application";
CM_ BO_ 715 "Note that the stand-alone radar ACC algorithm will transmit this message at a 50 ms periodic rate and the EOCM and FCM algorithm will transmit this message at a 40 ms periodic rate";
CM_ SG_ 1905 DTCI_DTCFaultType_771 "Based on Powertrain definition.  Not expected to be supported by all devices.";
CM_ SG_ 1905 DTCI_DTCFailType_771 "Assigned per GMW3110, Appendix E";
CM_ SG_ 1905 DTCI_DTCSource_771 "This shall be equal to the Diagnostic Address of the transmittting device.";
CM_ SG_ 1935 DTCI_DTCSource_78F "This shall be equal to the Diagnostic Address of the transmittting device.";
CM_ SG_ 1935 DTCI_DTCFaultType_78F "Based on Powertrain definition.  Not expected to be supported by all devices.";
CM_ SG_ 1935 DTCI_DTCFailType_78F "Assigned per GMW3110, Appendix E";
CM_ SG_ 1934 DTCI_DTCFailType_78E "Assigned per GMW3110, Appendix E";
CM_ SG_ 1934 DTCI_DTCFaultType_78E "Based on Powertrain definition.  Not expected to be supported by all devices.";
CM_ SG_ 1934 DTCI_DTCSource_78E "This shall be equal to the Diagnostic Address of the transmittting device.";
CM_ SG_ 1933 DTCI_DTCFailType_78D "Assigned per GMW3110, Appendix E";
CM_ SG_ 1933 DTCI_DTCFaultType_78D "Based on Powertrain definition.  Not expected to be supported by all devices.";
CM_ SG_ 1933 DTCI_DTCSource_78D "This shall be equal to the Diagnostic Address of the transmittting device.";
CM_ SG_ 1932 DTCI_DTCFailType_78C "Assigned per GMW3110, Appendix E";
CM_ SG_ 1932 DTCI_DTCFaultType_78C "Based on Powertrain definition.  Not expected to be supported by all devices.";
CM_ SG_ 1932 DTCI_DTCSource_78C "This shall be equal to the Diagnostic Address of the transmittting device.";
CM_ SG_ 1931 DTCI_DTCFailType_78B "Assigned per GMW3110, Appendix E";
CM_ SG_ 1931 DTCI_DTCFaultType_78B "Based on Powertrain definition.  Not expected to be supported by all devices.";
CM_ SG_ 1931 DTCI_DTCSource_78B "This shall be equal to the Diagnostic Address of the transmittting device.";
CM_ SG_ 1930 DTCI_DTCFailType_78A "Assigned per GMW3110, Appendix E";
CM_ SG_ 1930 DTCI_DTCFaultType_78A "Based on Powertrain definition.  Not expected to be supported by all devices.";
CM_ SG_ 1930 DTCI_DTCSource_78A "This shall be equal to the Diagnostic Address of the transmittting device.";
CM_ SG_ 1929 DTCI_DTCFailType_789 "Assigned per GMW3110, Appendix E";
CM_ SG_ 1929 DTCI_DTCFaultType_789 "Based on Powertrain definition.  Not expected to be supported by all devices.";
CM_ SG_ 1929 DTCI_DTCSource_789 "This shall be equal to the Diagnostic Address of the transmittting device.";
CM_ SG_ 1928 DTCI_DTCFailType_788 "Assigned per GMW3110, Appendix E";
CM_ SG_ 1928 DTCI_DTCFaultType_788 "Based on Powertrain definition.  Not expected to be supported by all devices.";
CM_ SG_ 1928 DTCI_DTCSource_788 "This shall be equal to the Diagnostic Address of the transmittting device.";
CM_ SG_ 1927 DTCI_DTCFailType_787 "Assigned per GMW3110, Appendix E";
CM_ SG_ 1927 DTCI_DTCFaultType_787 "Based on Powertrain definition.  Not expected to be supported by all devices.";
CM_ SG_ 1927 DTCI_DTCSource_787 "This shall be equal to the Diagnostic Address of the transmittting device.";
CM_ SG_ 1926 DTCI_DTCFailType_786 "Assigned per GMW3110, Appendix E";
CM_ SG_ 1926 DTCI_DTCFaultType_786 "Based on Powertrain definition.  Not expected to be supported by all devices.";
CM_ SG_ 1926 DTCI_DTCSource_786 "This shall be equal to the Diagnostic Address of the transmittting device.";
CM_ SG_ 1925 DTCI_DTCFailType_785 "Assigned per GMW3110, Appendix E";
CM_ SG_ 1925 DTCI_DTCFaultType_785 "Based on Powertrain definition.  Not expected to be supported by all devices.";
CM_ SG_ 1925 DTCI_DTCSource_785 "This shall be equal to the Diagnostic Address of the transmittting device.";
CM_ SG_ 1924 DTCI_DTCFailType_784 "Assigned per GMW3110, Appendix E";
CM_ SG_ 1924 DTCI_DTCFaultType_784 "Based on Powertrain definition.  Not expected to be supported by all devices.";
CM_ SG_ 1924 DTCI_DTCSource_784 "This shall be equal to the Diagnostic Address of the transmittting device.";
CM_ SG_ 1923 DTCI_DTCSource_783 "This shall be equal to the Diagnostic Address of the transmittting device.";
CM_ SG_ 1923 DTCI_DTCFaultType_783 "Based on Powertrain definition.  Not expected to be supported by all devices.";
CM_ SG_ 1923 DTCI_DTCFailType_783 "Assigned per GMW3110, Appendix E";
CM_ SG_ 1922 DTCI_DTCSource_782 "This shall be equal to the Diagnostic Address of the transmittting device.";
CM_ SG_ 1922 DTCI_DTCFaultType_782 "Based on Powertrain definition.  Not expected to be supported by all devices.";
CM_ SG_ 1922 DTCI_DTCFailType_782 "Assigned per GMW3110, Appendix E";
CM_ SG_ 532 BrkSysAutBrkFld "BrakeSystemAutomaticBrakingFailed";
CM_ SG_ 532 IntBrkAssPreFilReq "IntelligentBrakeAssistPreFillRequest";
BA_DEF_ SG_  "VNSigSLHSSharedDiagnostic" ENUM  "No","Yes","DLCLS","DLCHS","DLCCE","DLCFO";
BA_DEF_ SG_  "SignalType" STRING ;
BA_DEF_ SG_  "PacketOrder" INT 0 65535;
BA_DEF_ SG_  "SignalLongName" STRING ;
BA_DEF_ SG_  "GenSigStartValue" INT 0 65535;
BA_DEF_ SG_  "VNSigAllNodes" ENUM  "No","Yes","DLCLS","DLCHS","DLCCE","DLCFO";
BA_DEF_ SG_  "GenSigSendType" ENUM  "not used","not used","not used","not used","not used","not used","not used","NoSigSendType","not used","not used","OnAnyChange","OnChangeIfActive","OnDelta","DLCLS","DLCHS","DLCCE","DLCFO";
BA_DEF_ SG_  "GenSigSendOnInit" ENUM  "Not Initialized","Application","Handler","DLCLS","DLCHS","DLCCE","DLCFO";
BA_DEF_ BO_  "AppGenMsgCycleTime" INT 0 0;
BA_DEF_ BO_  "GenMsgILSupport" ENUM  "No","Yes","DLCLS","DLCHS","DLCCE","DLCFO";
BA_DEF_ BO_  "TpApplType" STRING ;
BA_DEF_ BO_  "Prio" INT 0 7;
BA_DEF_ BO_  "MessageSubnet" ENUM  "LS","MS","HS","CE","PE","HV","FO","S1","HE","LE","HE2","DLCLS","DLCHS","DLCCE","DLCFO";
BA_DEF_ BO_  "DiagState" ENUM  "No","Yes","DLCLS","DLCHS","DLCCE","DLCFO";
BA_DEF_ BO_  "GenMsgStartDelayTime" INT 0 100000;
BA_DEF_ BO_  "GenMsgDelayTime" INT 0 100000;
BA_DEF_ BO_  "GenMsgCycleTime" INT 0 100000;
BA_DEF_ BO_  "GenMsgSendType" ENUM  "cyclicX","spontanX","cyclicIfActiveX","spontanWithDelay","cyclicAndSpontanX","cyclicAndSpontanWithDelay","spontanWithRepitition","cyclicIfActiveAndSpontanWD","DLCLS","DLCHS","DLCCE","DLCFO";
BA_DEF_ BO_  "DiagResponse" ENUM  "No","Yes","DLCLS","DLCHS","DLCCE","DLCFO";
BA_DEF_ BO_  "DiagRequest" ENUM  "No","Yes","DLCLS","DLCHS","DLCCE","DLCFO";
BA_DEF_ BO_  "NmMessage" ENUM  "No","Yes","DLCLS","DLCHS","DLCCE","DLCFO";
BA_DEF_DEF_  "VNSigSLHSSharedDiagnostic" "No";
BA_DEF_DEF_  "SignalType" "";
BA_DEF_DEF_  "PacketOrder" 0;
BA_DEF_DEF_  "SignalLongName" "";
BA_DEF_DEF_  "GenSigStartValue" 0;
BA_DEF_DEF_  "VNSigAllNodes" "No";
BA_DEF_DEF_  "GenSigSendType" "NoSigSendType";
BA_DEF_DEF_  "GenSigSendOnInit" "Not Initialized";
BA_DEF_DEF_  "AppGenMsgCycleTime" 0;
BA_DEF_DEF_  "GenMsgILSupport" "Yes";
BA_DEF_DEF_  "TpApplType" "";
BA_DEF_DEF_  "Prio" 4;
BA_DEF_DEF_  "MessageSubnet" "FO";
BA_DEF_DEF_  "DiagState" "No";
BA_DEF_DEF_  "GenMsgStartDelayTime" 0;
BA_DEF_DEF_  "GenMsgDelayTime" 0;
BA_DEF_DEF_  "GenMsgCycleTime" 0;
BA_DEF_DEF_  "GenMsgSendType" "spontanX";
BA_DEF_DEF_  "DiagResponse" "No";
BA_DEF_DEF_  "DiagRequest" "No";
BA_DEF_DEF_  "NmMessage" "No";
BA_ "GenMsgSendType" BO_ 1323 0;
BA_ "GenMsgCycleTime" BO_ 1323 1000;
BA_ "GenMsgStartDelayTime" BO_ 1323 50;
BA_ "MessageSubnet" BO_ 1323 2;
BA_ "Prio" BO_ 1323 0;
BA_ "GenMsgSendType" BO_ 1247 0;
BA_ "GenMsgCycleTime" BO_ 1247 500;
BA_ "MessageSubnet" BO_ 1247 2;
BA_ "Prio" BO_ 1247 0;
BA_ "GenMsgSendType" BO_ 723 0;
BA_ "GenMsgCycleTime" BO_ 723 50;
BA_ "MessageSubnet" BO_ 723 2;
BA_ "Prio" BO_ 723 0;
BA_ "GenMsgSendType" BO_ 405 0;
BA_ "GenMsgCycleTime" BO_ 405 12;
BA_ "MessageSubnet" BO_ 405 2;
BA_ "Prio" BO_ 405 0;
BA_ "GenMsgSendType" BO_ 419 0;
BA_ "GenMsgCycleTime" BO_ 419 25;
BA_ "MessageSubnet" BO_ 419 2;
BA_ "Prio" BO_ 419 0;
BA_ "GenMsgSendType" BO_ 289 0;
BA_ "GenMsgCycleTime" BO_ 289 20;
BA_ "MessageSubnet" BO_ 289 2;
BA_ "Prio" BO_ 289 0;
BA_ "GenMsgSendType" BO_ 1268 0;
BA_ "GenMsgCycleTime" BO_ 1268 1000;
BA_ "MessageSubnet" BO_ 1268 2;
BA_ "Prio" BO_ 1268 0;
BA_ "GenMsgSendType" BO_ 800 0;
BA_ "GenMsgCycleTime" BO_ 800 100;
BA_ "GenMsgDelayTime" BO_ 800 10;
BA_ "MessageSubnet" BO_ 800 2;
BA_ "Prio" BO_ 800 0;
BA_ "GenMsgSendType" BO_ 388 0;
BA_ "GenMsgCycleTime" BO_ 388 100;
BA_ "MessageSubnet" BO_ 388 2;
BA_ "Prio" BO_ 388 0;
BA_ "GenMsgSendType" BO_ 384 0;
BA_ "GenMsgCycleTime" BO_ 384 100;
BA_ "GenMsgDelayTime" BO_ 384 10;
BA_ "MessageSubnet" BO_ 384 2;
BA_ "Prio" BO_ 384 0;
BA_ "GenMsgSendType" BO_ 866 0;
BA_ "GenMsgCycleTime" BO_ 866 50;
BA_ "MessageSubnet" BO_ 866 2;
BA_ "Prio" BO_ 866 0;
BA_ "GenMsgSendType" BO_ 951 0;
BA_ "GenMsgCycleTime" BO_ 951 100;
BA_ "MessageSubnet" BO_ 951 2;
BA_ "Prio" BO_ 951 0;
BA_ "GenMsgSendType" BO_ 949 0;
BA_ "GenMsgCycleTime" BO_ 949 100;
BA_ "MessageSubnet" BO_ 949 2;
BA_ "Prio" BO_ 949 0;
BA_ "GenMsgSendType" BO_ 1223 0;
BA_ "GenMsgCycleTime" BO_ 1223 500;
BA_ "MessageSubnet" BO_ 1223 2;
BA_ "Prio" BO_ 1223 0;
BA_ "GenMsgSendType" BO_ 1227 0;
BA_ "GenMsgCycleTime" BO_ 1227 500;
BA_ "MessageSubnet" BO_ 1227 2;
BA_ "Prio" BO_ 1227 0;
BA_ "GenMsgSendType" BO_ 543 0;
BA_ "GenMsgCycleTime" BO_ 543 100;
BA_ "GenMsgStartDelayTime" BO_ 543 110;
BA_ "MessageSubnet" BO_ 543 2;
BA_ "Prio" BO_ 543 0;
BA_ "GenMsgSendType" BO_ 544 0;
BA_ "GenMsgCycleTime" BO_ 544 250;
BA_ "MessageSubnet" BO_ 544 2;
BA_ "Prio" BO_ 544 0;
BA_ "GenMsgSendType" BO_ 901 0;
BA_ "GenMsgCycleTime" BO_ 901 100;
BA_ "MessageSubnet" BO_ 901 2;
BA_ "Prio" BO_ 901 0;
BA_ "GenMsgSendType" BO_ 1032 0;
BA_ "GenMsgCycleTime" BO_ 1032 100;
BA_ "MessageSubnet" BO_ 1032 2;
BA_ "Prio" BO_ 1032 0;
BA_ "GenMsgSendType" BO_ 1031 0;
BA_ "GenMsgCycleTime" BO_ 1031 100;
BA_ "MessageSubnet" BO_ 1031 2;
BA_ "Prio" BO_ 1031 0;
BA_ "GenMsgSendType" BO_ 1030 0;
BA_ "GenMsgCycleTime" BO_ 1030 100;
BA_ "MessageSubnet" BO_ 1030 2;
BA_ "Prio" BO_ 1030 0;
BA_ "GenMsgSendType" BO_ 479 0;
BA_ "GenMsgCycleTime" BO_ 479 25;
BA_ "MessageSubnet" BO_ 479 2;
BA_ "Prio" BO_ 479 0;
BA_ "GenMsgSendType" BO_ 211 0;
BA_ "GenMsgCycleTime" BO_ 211 12;
BA_ "MessageSubnet" BO_ 211 2;
BA_ "Prio" BO_ 211 0;
BA_ "GenMsgSendType" BO_ 1020 0;
BA_ "GenMsgCycleTime" BO_ 1020 250;
BA_ "MessageSubnet" BO_ 1020 2;
BA_ "Prio" BO_ 1020 0;
BA_ "GenMsgSendType" BO_ 567 0;
BA_ "GenMsgCycleTime" BO_ 567 250;
BA_ "MessageSubnet" BO_ 567 2;
BA_ "Prio" BO_ 567 0;
BA_ "GenMsgSendType" BO_ 1219 0;
BA_ "GenMsgCycleTime" BO_ 1219 1000;
BA_ "MessageSubnet" BO_ 1219 2;
BA_ "Prio" BO_ 1219 0;
BA_ "GenMsgSendType" BO_ 372 0;
BA_ "GenMsgCycleTime" BO_ 372 100;
BA_ "MessageSubnet" BO_ 372 2;
BA_ "Prio" BO_ 372 0;
BA_ "GenMsgSendType" BO_ 528 0;
BA_ "GenMsgCycleTime" BO_ 528 50;
BA_ "MessageSubnet" BO_ 528 2;
BA_ "Prio" BO_ 528 0;
BA_ "GenMsgSendType" BO_ 442 0;
BA_ "GenMsgCycleTime" BO_ 442 25;
BA_ "MessageSubnet" BO_ 442 2;
BA_ "Prio" BO_ 442 0;
BA_ "GenMsgSendType" BO_ 753 0;
BA_ "GenMsgCycleTime" BO_ 753 100;
BA_ "MessageSubnet" BO_ 753 2;
BA_ "Prio" BO_ 753 0;
BA_ "GenMsgSendType" BO_ 989 0;
BA_ "GenMsgCycleTime" BO_ 989 100;
BA_ "MessageSubnet" BO_ 989 2;
BA_ "Prio" BO_ 989 0;
BA_ "GenMsgSendType" BO_ 550 0;
BA_ "GenMsgCycleTime" BO_ 550 500;
BA_ "MessageSubnet" BO_ 550 2;
BA_ "Prio" BO_ 550 0;
BA_ "GenMsgSendType" BO_ 988 0;
BA_ "GenMsgCycleTime" BO_ 988 100;
BA_ "MessageSubnet" BO_ 988 2;
BA_ "Prio" BO_ 988 0;
BA_ "GenMsgSendType" BO_ 565 0;
BA_ "GenMsgCycleTime" BO_ 565 2000;
BA_ "MessageSubnet" BO_ 565 2;
BA_ "Prio" BO_ 565 0;
BA_ "GenMsgSendType" BO_ 1029 0;
BA_ "GenMsgCycleTime" BO_ 1029 100;
BA_ "MessageSubnet" BO_ 1029 2;
BA_ "Prio" BO_ 1029 0;
BA_ "GenMsgSendType" BO_ 1028 0;
BA_ "GenMsgCycleTime" BO_ 1028 100;
BA_ "MessageSubnet" BO_ 1028 2;
BA_ "Prio" BO_ 1028 0;
BA_ "GenMsgSendType" BO_ 500 0;
BA_ "GenMsgCycleTime" BO_ 500 25;
BA_ "MessageSubnet" BO_ 500 2;
BA_ "Prio" BO_ 500 0;
BA_ "GenMsgSendType" BO_ 1417 0;
BA_ "GenMsgCycleTime" BO_ 1417 500;
BA_ "MessageSubnet" BO_ 1417 2;
BA_ "Prio" BO_ 1417 0;
BA_ "GenMsgSendType" BO_ 407 0;
BA_ "GenMsgCycleTime" BO_ 407 25;
BA_ "MessageSubnet" BO_ 407 2;
BA_ "Prio" BO_ 407 0;
BA_ "GenMsgSendType" BO_ 189 0;
BA_ "GenMsgCycleTime" BO_ 189 25;
BA_ "MessageSubnet" BO_ 189 2;
BA_ "Prio" BO_ 189 0;
BA_ "GenMsgSendType" BO_ 187 0;
BA_ "GenMsgCycleTime" BO_ 187 25;
BA_ "MessageSubnet" BO_ 187 2;
BA_ "Prio" BO_ 187 0;
BA_ "GenMsgSendType" BO_ 185 0;
BA_ "GenMsgCycleTime" BO_ 185 25;
BA_ "MessageSubnet" BO_ 185 2;
BA_ "Prio" BO_ 185 0;
BA_ "GenMsgSendType" BO_ 186 0;
BA_ "GenMsgCycleTime" BO_ 186 25;
BA_ "MessageSubnet" BO_ 186 2;
BA_ "Prio" BO_ 186 0;
BA_ "GenMsgSendType" BO_ 188 0;
BA_ "GenMsgCycleTime" BO_ 188 12;
BA_ "MessageSubnet" BO_ 188 2;
BA_ "Prio" BO_ 188 0;
BA_ "GenMsgSendType" BO_ 170 0;
BA_ "GenMsgCycleTime" BO_ 170 12;
BA_ "MessageSubnet" BO_ 170 2;
BA_ "Prio" BO_ 170 0;
BA_ "GenMsgSendType" BO_ 1221 0;
BA_ "GenMsgCycleTime" BO_ 1221 500;
BA_ "GenMsgStartDelayTime" BO_ 1221 10;
BA_ "MessageSubnet" BO_ 1221 2;
BA_ "Prio" BO_ 1221 0;
BA_ "GenMsgSendType" BO_ 1243 0;
BA_ "GenMsgCycleTime" BO_ 1243 500;
BA_ "MessageSubnet" BO_ 1243 2;
BA_ "Prio" BO_ 1243 0;
BA_ "GenMsgSendType" BO_ 979 0;
BA_ "GenMsgCycleTime" BO_ 979 100;
BA_ "MessageSubnet" BO_ 979 2;
BA_ "Prio" BO_ 979 0;
BA_ "GenMsgSendType" BO_ 546 0;
BA_ "GenMsgCycleTime" BO_ 546 100;
BA_ "MessageSubnet" BO_ 546 2;
BA_ "Prio" BO_ 546 0;
BA_ "GenMsgSendType" BO_ 530 0;
BA_ "GenMsgCycleTime" BO_ 530 1000;
BA_ "MessageSubnet" BO_ 530 2;
BA_ "Prio" BO_ 530 0;
BA_ "GenMsgSendType" BO_ 1239 0;
BA_ "GenMsgCycleTime" BO_ 1239 500;
BA_ "GenMsgStartDelayTime" BO_ 1239 20;
BA_ "MessageSubnet" BO_ 1239 2;
BA_ "Prio" BO_ 1239 0;
BA_ "DiagResponse" BO_ 1610 1;
BA_ "MessageSubnet" BO_ 1610 2;
BA_ "Prio" BO_ 1610 0;
BA_ "GenMsgSendType" BO_ 1022 0;
BA_ "GenMsgCycleTime" BO_ 1022 250;
BA_ "MessageSubnet" BO_ 1022 2;
BA_ "Prio" BO_ 1022 0;
BA_ "GenMsgSendType" BO_ 967 0;
BA_ "GenMsgCycleTime" BO_ 967 100;
BA_ "MessageSubnet" BO_ 967 2;
BA_ "Prio" BO_ 967 0;
BA_ "GenMsgSendType" BO_ 1027 0;
BA_ "GenMsgCycleTime" BO_ 1027 100;
BA_ "MessageSubnet" BO_ 1027 2;
BA_ "Prio" BO_ 1027 0;
BA_ "GenMsgSendType" BO_ 1026 0;
BA_ "GenMsgCycleTime" BO_ 1026 100;
BA_ "MessageSubnet" BO_ 1026 2;
BA_ "Prio" BO_ 1026 0;
BA_ "GenMsgSendType" BO_ 1025 0;
BA_ "GenMsgCycleTime" BO_ 1025 100;
BA_ "MessageSubnet" BO_ 1025 2;
BA_ "Prio" BO_ 1025 0;
BA_ "GenMsgSendType" BO_ 1024 0;
BA_ "GenMsgCycleTime" BO_ 1024 100;
BA_ "MessageSubnet" BO_ 1024 2;
BA_ "Prio" BO_ 1024 0;
BA_ "GenMsgSendType" BO_ 508 0;
BA_ "GenMsgCycleTime" BO_ 508 50;
BA_ "MessageSubnet" BO_ 508 2;
BA_ "Prio" BO_ 508 0;
BA_ "GenMsgSendType" BO_ 422 0;
BA_ "GenMsgCycleTime" BO_ 422 25;
BA_ "MessageSubnet" BO_ 422 2;
BA_ "Prio" BO_ 422 0;
BA_ "GenMsgSendType" BO_ 647 0;
BA_ "GenMsgCycleTime" BO_ 647 25;
BA_ "MessageSubnet" BO_ 647 2;
BA_ "Prio" BO_ 647 0;
BA_ "GenMsgSendType" BO_ 368 0;
BA_ "GenMsgCycleTime" BO_ 368 100;
BA_ "MessageSubnet" BO_ 368 2;
BA_ "Prio" BO_ 368 0;
BA_ "GenMsgSendType" BO_ 995 0;
BA_ "GenMsgCycleTime" BO_ 995 100;
BA_ "MessageSubnet" BO_ 995 2;
BA_ "Prio" BO_ 995 0;
BA_ "GenMsgSendType" BO_ 971 0;
BA_ "GenMsgCycleTime" BO_ 971 100;
BA_ "GenMsgStartDelayTime" BO_ 971 90;
BA_ "MessageSubnet" BO_ 971 2;
BA_ "Prio" BO_ 971 0;
BA_ "GenMsgSendType" BO_ 209 0;
BA_ "GenMsgCycleTime" BO_ 209 10;
BA_ "MessageSubnet" BO_ 209 2;
BA_ "Prio" BO_ 209 0;
BA_ "GenMsgSendType" BO_ 454 0;
BA_ "GenMsgCycleTime" BO_ 454 25;
BA_ "MessageSubnet" BO_ 454 2;
BA_ "Prio" BO_ 454 0;
BA_ "GenMsgSendType" BO_ 1189 0;
BA_ "GenMsgCycleTime" BO_ 1189 500;
BA_ "MessageSubnet" BO_ 1189 2;
BA_ "Prio" BO_ 1189 0;
BA_ "GenMsgSendType" BO_ 1187 0;
BA_ "GenMsgCycleTime" BO_ 1187 1000;
BA_ "MessageSubnet" BO_ 1187 2;
BA_ "Prio" BO_ 1187 0;
BA_ "GenMsgSendType" BO_ 554 0;
BA_ "GenMsgCycleTime" BO_ 554 100;
BA_ "MessageSubnet" BO_ 554 2;
BA_ "Prio" BO_ 554 0;
BA_ "GenMsgSendType" BO_ 487 0;
BA_ "GenMsgCycleTime" BO_ 487 12;
BA_ "MessageSubnet" BO_ 487 2;
BA_ "Prio" BO_ 487 0;
BA_ "GenMsgSendType" BO_ 566 0;
BA_ "GenMsgCycleTime" BO_ 566 100;
BA_ "MessageSubnet" BO_ 566 2;
BA_ "Prio" BO_ 566 0;
BA_ "GenMsgSendType" BO_ 421 0;
BA_ "GenMsgCycleTime" BO_ 421 25;
BA_ "MessageSubnet" BO_ 421 2;
BA_ "Prio" BO_ 421 0;
BA_ "GenMsgSendType" BO_ 456 0;
BA_ "GenMsgCycleTime" BO_ 456 10;
BA_ "MessageSubnet" BO_ 456 2;
BA_ "Prio" BO_ 456 0;
BA_ "GenMsgSendType" BO_ 884 0;
BA_ "GenMsgCycleTime" BO_ 884 40;
BA_ "MessageSubnet" BO_ 884 2;
BA_ "Prio" BO_ 884 0;
BA_ "GenMsgSendType" BO_ 882 0;
BA_ "GenMsgCycleTime" BO_ 882 40;
BA_ "MessageSubnet" BO_ 882 2;
BA_ "Prio" BO_ 882 0;
BA_ "GenMsgSendType" BO_ 393 0;
BA_ "GenMsgCycleTime" BO_ 393 25;
BA_ "MessageSubnet" BO_ 393 2;
BA_ "Prio" BO_ 393 0;
BA_ "GenMsgSendType" BO_ 199 0;
BA_ "GenMsgCycleTime" BO_ 199 12;
BA_ "MessageSubnet" BO_ 199 2;
BA_ "Prio" BO_ 199 0;
BA_ "GenMsgSendType" BO_ 398 0;
BA_ "GenMsgCycleTime" BO_ 398 12;
BA_ "MessageSubnet" BO_ 398 2;
BA_ "Prio" BO_ 398 0;
BA_ "GenMsgSendType" BO_ 464 0;
BA_ "GenMsgCycleTime" BO_ 464 20;
BA_ "MessageSubnet" BO_ 464 2;
BA_ "Prio" BO_ 464 0;
BA_ "GenMsgSendType" BO_ 390 0;
BA_ "GenMsgCycleTime" BO_ 390 12;
BA_ "MessageSubnet" BO_ 390 2;
BA_ "Prio" BO_ 390 0;
BA_ "GenMsgSendType" BO_ 817 0;
BA_ "GenMsgCycleTime" BO_ 817 100;
BA_ "MessageSubnet" BO_ 817 2;
BA_ "Prio" BO_ 817 0;
BA_ "GenMsgSendType" BO_ 465 0;
BA_ "GenMsgCycleTime" BO_ 465 20;
BA_ "MessageSubnet" BO_ 465 2;
BA_ "Prio" BO_ 465 0;
BA_ "GenMsgSendType" BO_ 460 0;
BA_ "GenMsgCycleTime" BO_ 460 20;
BA_ "MessageSubnet" BO_ 460 2;
BA_ "Prio" BO_ 460 0;
BA_ "GenMsgSendType" BO_ 462 0;
BA_ "GenMsgCycleTime" BO_ 462 20;
BA_ "MessageSubnet" BO_ 462 2;
BA_ "Prio" BO_ 462 0;
BA_ "GenMsgSendType" BO_ 463 0;
BA_ "GenMsgCycleTime" BO_ 463 100;
BA_ "MessageSubnet" BO_ 463 2;
BA_ "Prio" BO_ 463 0;
BA_ "MessageSubnet" BO_ 719 2;
BA_ "Prio" BO_ 719 0;
BA_ "AppGenMsgCycleTime" BO_ 719 40;
BA_ "GenMsgSendType" BO_ 853 0;
BA_ "GenMsgCycleTime" BO_ 853 100;
BA_ "MessageSubnet" BO_ 853 2;
BA_ "Prio" BO_ 853 0;
BA_ "MessageSubnet" BO_ 869 2;
BA_ "Prio" BO_ 869 0;
BA_ "AppGenMsgCycleTime" BO_ 869 40;
BA_ "MessageSubnet" BO_ 717 2;
BA_ "Prio" BO_ 717 0;
BA_ "AppGenMsgCycleTime" BO_ 717 40;
BA_ "GenMsgSendType" BO_ 568 0;
BA_ "GenMsgCycleTime" BO_ 568 10;
BA_ "MessageSubnet" BO_ 568 2;
BA_ "Prio" BO_ 568 0;
BA_ "GenMsgSendType" BO_ 564 0;
BA_ "GenMsgCycleTime" BO_ 564 100;
BA_ "MessageSubnet" BO_ 564 2;
BA_ "Prio" BO_ 564 0;
BA_ "GenMsgSendType" BO_ 313 0;
BA_ "GenMsgCycleTime" BO_ 313 100;
BA_ "GenMsgStartDelayTime" BO_ 313 70;
BA_ "MessageSubnet" BO_ 313 2;
BA_ "Prio" BO_ 313 0;
BA_ "GenMsgSendType" BO_ 1328 0;
BA_ "GenMsgCycleTime" BO_ 1328 1000;
BA_ "GenMsgStartDelayTime" BO_ 1328 80;
BA_ "MessageSubnet" BO_ 1328 2;
BA_ "Prio" BO_ 1328 0;
BA_ "GenMsgSendType" BO_ 1296 0;
BA_ "GenMsgCycleTime" BO_ 1296 100;
BA_ "MessageSubnet" BO_ 1296 2;
BA_ "Prio" BO_ 1296 0;
BA_ "GenMsgSendType" BO_ 311 0;
BA_ "GenMsgCycleTime" BO_ 311 100;
BA_ "GenMsgStartDelayTime" BO_ 311 60;
BA_ "MessageSubnet" BO_ 311 2;
BA_ "Prio" BO_ 311 0;
BA_ "GenMsgSendType" BO_ 536 0;
BA_ "GenMsgCycleTime" BO_ 536 200;
BA_ "MessageSubnet" BO_ 536 2;
BA_ "Prio" BO_ 536 0;
BA_ "GenMsgSendType" BO_ 570 0;
BA_ "GenMsgCycleTime" BO_ 570 200;
BA_ "MessageSubnet" BO_ 570 2;
BA_ "Prio" BO_ 570 0;
BA_ "GenMsgSendType" BO_ 810 0;
BA_ "GenMsgCycleTime" BO_ 810 100;
BA_ "GenMsgStartDelayTime" BO_ 810 80;
BA_ "MessageSubnet" BO_ 810 2;
BA_ "Prio" BO_ 810 0;
BA_ "GenMsgSendType" BO_ 848 0;
BA_ "GenMsgCycleTime" BO_ 848 50;
BA_ "MessageSubnet" BO_ 848 2;
BA_ "Prio" BO_ 848 0;
BA_ "GenMsgSendType" BO_ 953 0;
BA_ "GenMsgCycleTime" BO_ 953 100;
BA_ "MessageSubnet" BO_ 953 2;
BA_ "Prio" BO_ 953 0;
BA_ "GenMsgSendType" BO_ 510 0;
BA_ "GenMsgCycleTime" BO_ 510 50;
BA_ "MessageSubnet" BO_ 510 2;
BA_ "Prio" BO_ 510 0;
BA_ "GenMsgSendType" BO_ 711 0;
BA_ "GenMsgCycleTime" BO_ 711 25;
BA_ "MessageSubnet" BO_ 711 2;
BA_ "Prio" BO_ 711 0;
BA_ "GenMsgSendType" BO_ 1011 0;
BA_ "GenMsgCycleTime" BO_ 1011 250;
BA_ "MessageSubnet" BO_ 1011 2;
BA_ "Prio" BO_ 1011 0;
BA_ "GenMsgSendType" BO_ 304 0;
BA_ "GenMsgCycleTime" BO_ 304 1000;
BA_ "GenMsgStartDelayTime" BO_ 304 20;
BA_ "MessageSubnet" BO_ 304 2;
BA_ "Prio" BO_ 304 0;
BA_ "GenMsgSendType" BO_ 1105 0;
BA_ "GenMsgCycleTime" BO_ 1105 100;
BA_ "GenMsgStartDelayTime" BO_ 1105 10;
BA_ "MessageSubnet" BO_ 1105 2;
BA_ "Prio" BO_ 1105 0;
BA_ "GenMsgSendType" BO_ 1005 0;
BA_ "GenMsgCycleTime" BO_ 1005 250;
BA_ "MessageSubnet" BO_ 1005 2;
BA_ "Prio" BO_ 1005 0;
BA_ "GenMsgSendType" BO_ 688 0;
BA_ "GenMsgCycleTime" BO_ 688 20;
BA_ "MessageSubnet" BO_ 688 2;
BA_ "Prio" BO_ 688 0;
BA_ "GenMsgSendType" BO_ 993 0;
BA_ "GenMsgCycleTime" BO_ 993 100;
BA_ "MessageSubnet" BO_ 993 2;
BA_ "Prio" BO_ 993 0;
BA_ "GenMsgSendType" BO_ 490 0;
BA_ "GenMsgCycleTime" BO_ 490 12;
BA_ "MessageSubnet" BO_ 490 2;
BA_ "Prio" BO_ 490 0;
BA_ "GenMsgSendType" BO_ 431 0;
BA_ "GenMsgCycleTime" BO_ 431 25;
BA_ "MessageSubnet" BO_ 431 2;
BA_ "Prio" BO_ 431 0;
BA_ "MessageSubnet" BO_ 715 2;
BA_ "Prio" BO_ 715 0;
BA_ "AppGenMsgCycleTime" BO_ 715 40;
BA_ "GenMsgSendType" BO_ 1267 0;
BA_ "GenMsgCycleTime" BO_ 1267 1000;
BA_ "MessageSubnet" BO_ 1267 2;
BA_ "Prio" BO_ 1267 0;
BA_ "GenMsgSendType" BO_ 453 0;
BA_ "GenMsgCycleTime" BO_ 453 25;
BA_ "MessageSubnet" BO_ 453 2;
BA_ "Prio" BO_ 453 0;
BA_ "GenMsgSendType" BO_ 452 0;
BA_ "GenMsgCycleTime" BO_ 452 25;
BA_ "MessageSubnet" BO_ 452 2;
BA_ "Prio" BO_ 452 0;
BA_ "GenMsgSendType" BO_ 1905 0;
BA_ "GenMsgCycleTime" BO_ 1905 1000;
BA_ "MessageSubnet" BO_ 1905 2;
BA_ "Prio" BO_ 1905 6;
BA_ "GenMsgSendType" BO_ 1935 0;
BA_ "GenMsgCycleTime" BO_ 1935 1000;
BA_ "MessageSubnet" BO_ 1935 2;
BA_ "Prio" BO_ 1935 0;
BA_ "GenMsgSendType" BO_ 1934 0;
BA_ "GenMsgCycleTime" BO_ 1934 1000;
BA_ "MessageSubnet" BO_ 1934 2;
BA_ "Prio" BO_ 1934 0;
BA_ "GenMsgSendType" BO_ 1933 0;
BA_ "GenMsgCycleTime" BO_ 1933 1000;
BA_ "MessageSubnet" BO_ 1933 2;
BA_ "Prio" BO_ 1933 0;
BA_ "GenMsgSendType" BO_ 1932 0;
BA_ "GenMsgCycleTime" BO_ 1932 1000;
BA_ "MessageSubnet" BO_ 1932 2;
BA_ "Prio" BO_ 1932 0;
BA_ "GenMsgSendType" BO_ 1931 0;
BA_ "GenMsgCycleTime" BO_ 1931 1000;
BA_ "MessageSubnet" BO_ 1931 2;
BA_ "Prio" BO_ 1931 0;
BA_ "GenMsgSendType" BO_ 1930 0;
BA_ "GenMsgCycleTime" BO_ 1930 1000;
BA_ "MessageSubnet" BO_ 1930 2;
BA_ "Prio" BO_ 1930 0;
BA_ "GenMsgSendType" BO_ 1929 0;
BA_ "GenMsgCycleTime" BO_ 1929 1000;
BA_ "MessageSubnet" BO_ 1929 2;
BA_ "Prio" BO_ 1929 0;
BA_ "GenMsgSendType" BO_ 1928 0;
BA_ "GenMsgCycleTime" BO_ 1928 1000;
BA_ "MessageSubnet" BO_ 1928 2;
BA_ "Prio" BO_ 1928 0;
BA_ "GenMsgSendType" BO_ 1927 0;
BA_ "GenMsgCycleTime" BO_ 1927 1000;
BA_ "MessageSubnet" BO_ 1927 2;
BA_ "Prio" BO_ 1927 0;
BA_ "GenMsgSendType" BO_ 1926 0;
BA_ "GenMsgCycleTime" BO_ 1926 1000;
BA_ "MessageSubnet" BO_ 1926 2;
BA_ "Prio" BO_ 1926 0;
BA_ "GenMsgSendType" BO_ 1925 0;
BA_ "GenMsgCycleTime" BO_ 1925 1000;
BA_ "MessageSubnet" BO_ 1925 2;
BA_ "Prio" BO_ 1925 0;
BA_ "GenMsgSendType" BO_ 1924 0;
BA_ "GenMsgCycleTime" BO_ 1924 1000;
BA_ "MessageSubnet" BO_ 1924 2;
BA_ "Prio" BO_ 1924 0;
BA_ "GenMsgSendType" BO_ 1923 0;
BA_ "GenMsgCycleTime" BO_ 1923 1000;
BA_ "MessageSubnet" BO_ 1923 2;
BA_ "Prio" BO_ 1923 0;
BA_ "MessageSubnet" BO_ 1363 2;
BA_ "Prio" BO_ 1363 0;
BA_ "TpApplType" BO_ 1363 "DiagUUDTResponse";
BA_ "GenMsgILSupport" BO_ 1363 0;
BA_ "DiagRequest" BO_ 607 1;
BA_ "MessageSubnet" BO_ 607 2;
BA_ "Prio" BO_ 607 0;
BA_ "DiagResponse" BO_ 1630 1;
BA_ "MessageSubnet" BO_ 1630 2;
BA_ "Prio" BO_ 1630 0;
BA_ "GenMsgILSupport" BO_ 1630 0;
BA_ "DiagResponse" BO_ 1629 1;
BA_ "MessageSubnet" BO_ 1629 2;
BA_ "Prio" BO_ 1629 0;
BA_ "GenMsgILSupport" BO_ 1629 0;
BA_ "DiagRequest" BO_ 606 1;
BA_ "MessageSubnet" BO_ 606 2;
BA_ "Prio" BO_ 606 0;
BA_ "GenMsgILSupport" BO_ 606 0;
BA_ "DiagRequest" BO_ 605 1;
BA_ "MessageSubnet" BO_ 605 2;
BA_ "Prio" BO_ 605 0;
BA_ "GenMsgILSupport" BO_ 605 0;
BA_ "DiagRequest" BO_ 604 1;
BA_ "MessageSubnet" BO_ 604 2;
BA_ "Prio" BO_ 604 0;
BA_ "DiagRequest" BO_ 603 1;
BA_ "MessageSubnet" BO_ 603 2;
BA_ "Prio" BO_ 603 0;
BA_ "DiagRequest" BO_ 602 1;
BA_ "MessageSubnet" BO_ 602 2;
BA_ "Prio" BO_ 602 0;
BA_ "DiagResponse" BO_ 1631 1;
BA_ "MessageSubnet" BO_ 1631 2;
BA_ "Prio" BO_ 1631 0;
BA_ "MessageSubnet" BO_ 1375 2;
BA_ "Prio" BO_ 1375 0;
BA_ "TpApplType" BO_ 1375 "DiagUUDTResponse";
BA_ "GenMsgILSupport" BO_ 1375 0;
BA_ "MessageSubnet" BO_ 1374 2;
BA_ "Prio" BO_ 1374 0;
BA_ "TpApplType" BO_ 1374 "DiagUUDTResponse";
BA_ "GenMsgILSupport" BO_ 1374 0;
BA_ "MessageSubnet" BO_ 1373 2;
BA_ "Prio" BO_ 1373 0;
BA_ "TpApplType" BO_ 1373 "DiagUUDTResponse";
BA_ "GenMsgILSupport" BO_ 1373 0;
BA_ "MessageSubnet" BO_ 1372 2;
BA_ "Prio" BO_ 1372 0;
BA_ "TpApplType" BO_ 1372 "DiagUUDTResponse";
BA_ "GenMsgILSupport" BO_ 1372 0;
BA_ "MessageSubnet" BO_ 1371 2;
BA_ "Prio" BO_ 1371 0;
BA_ "TpApplType" BO_ 1371 "DiagUUDTResponse";
BA_ "GenMsgILSupport" BO_ 1371 0;
BA_ "MessageSubnet" BO_ 1370 2;
BA_ "Prio" BO_ 1370 0;
BA_ "TpApplType" BO_ 1370 "DiagUUDTResponse";
BA_ "GenMsgILSupport" BO_ 1370 0;
BA_ "MessageSubnet" BO_ 1368 2;
BA_ "Prio" BO_ 1368 0;
BA_ "TpApplType" BO_ 1368 "DiagUUDTResponse";
BA_ "GenMsgILSupport" BO_ 1368 0;
BA_ "MessageSubnet" BO_ 1367 2;
BA_ "Prio" BO_ 1367 0;
BA_ "TpApplType" BO_ 1367 "DiagUUDTResponse";
BA_ "GenMsgILSupport" BO_ 1367 0;
BA_ "MessageSubnet" BO_ 1366 2;
BA_ "Prio" BO_ 1366 0;
BA_ "TpApplType" BO_ 1366 "DiagUUDTResponse";
BA_ "GenMsgILSupport" BO_ 1366 0;
BA_ "MessageSubnet" BO_ 1362 2;
BA_ "Prio" BO_ 1362 0;
BA_ "TpApplType" BO_ 1362 "DiagUUDTResponse";
BA_ "GenMsgILSupport" BO_ 1362 0;
BA_ "DiagResponse" BO_ 1628 1;
BA_ "MessageSubnet" BO_ 1628 2;
BA_ "Prio" BO_ 1628 0;
BA_ "DiagResponse" BO_ 1627 1;
BA_ "MessageSubnet" BO_ 1627 2;
BA_ "Prio" BO_ 1627 0;
BA_ "DiagResponse" BO_ 1626 1;
BA_ "MessageSubnet" BO_ 1626 2;
BA_ "Prio" BO_ 1626 0;
BA_ "DiagResponse" BO_ 1624 1;
BA_ "MessageSubnet" BO_ 1624 2;
BA_ "Prio" BO_ 1624 0;
BA_ "DiagResponse" BO_ 1623 1;
BA_ "MessageSubnet" BO_ 1623 2;
BA_ "Prio" BO_ 1623 0;
BA_ "DiagResponse" BO_ 1622 1;
BA_ "MessageSubnet" BO_ 1622 2;
BA_ "Prio" BO_ 1622 0;
BA_ "DiagResponse" BO_ 1619 1;
BA_ "MessageSubnet" BO_ 1619 2;
BA_ "Prio" BO_ 1619 0;
BA_ "DiagResponse" BO_ 1618 1;
BA_ "MessageSubnet" BO_ 1618 2;
BA_ "Prio" BO_ 1618 0;
BA_ "DiagResponse" BO_ 1617 1;
BA_ "MessageSubnet" BO_ 1617 2;
BA_ "Prio" BO_ 1617 0;
BA_ "DiagRequest" BO_ 600 1;
BA_ "MessageSubnet" BO_ 600 2;
BA_ "Prio" BO_ 600 0;
BA_ "DiagRequest" BO_ 599 1;
BA_ "MessageSubnet" BO_ 599 2;
BA_ "Prio" BO_ 599 0;
BA_ "DiagRequest" BO_ 598 1;
BA_ "MessageSubnet" BO_ 598 2;
BA_ "Prio" BO_ 598 0;
BA_ "DiagRequest" BO_ 595 1;
BA_ "MessageSubnet" BO_ 595 2;
BA_ "Prio" BO_ 595 0;
BA_ "DiagRequest" BO_ 594 1;
BA_ "MessageSubnet" BO_ 594 2;
BA_ "Prio" BO_ 594 0;
BA_ "DiagRequest" BO_ 593 1;
BA_ "MessageSubnet" BO_ 593 2;
BA_ "Prio" BO_ 593 0;
BA_ "GenMsgSendType" BO_ 1280 0;
BA_ "GenMsgCycleTime" BO_ 1280 1000;
BA_ "MessageSubnet" BO_ 1280 2;
BA_ "Prio" BO_ 1280 0;
BA_ "GenMsgSendType" BO_ 190 0;
BA_ "GenMsgCycleTime" BO_ 190 12;
BA_ "MessageSubnet" BO_ 190 2;
BA_ "Prio" BO_ 190 0;
BA_ "MessageSubnet" BO_ 1361 2;
BA_ "Prio" BO_ 1361 0;
BA_ "TpApplType" BO_ 1361 "DiagUUDTResponse";
BA_ "GenMsgILSupport" BO_ 1361 0;
BA_ "MessageSubnet" BO_ 1345 2;
BA_ "Prio" BO_ 1345 0;
BA_ "TpApplType" BO_ 1345 "DiagUUDTResponse";
BA_ "GenMsgILSupport" BO_ 1345 0;
BA_ "GenMsgSendType" BO_ 322 0;
BA_ "GenMsgCycleTime" BO_ 322 100;
BA_ "GenMsgStartDelayTime" BO_ 322 90;
BA_ "MessageSubnet" BO_ 322 2;
BA_ "Prio" BO_ 322 0;
BA_ "DiagResponse" BO_ 1608 1;
BA_ "MessageSubnet" BO_ 1608 2;
BA_ "Prio" BO_ 1608 0;
BA_ "GenMsgSendType" BO_ 534 0;
BA_ "GenMsgCycleTime" BO_ 534 100;
BA_ "MessageSubnet" BO_ 534 2;
BA_ "Prio" BO_ 534 0;
BA_ "GenMsgSendType" BO_ 309 0;
BA_ "GenMsgCycleTime" BO_ 309 100;
BA_ "GenMsgStartDelayTime" BO_ 309 50;
BA_ "MessageSubnet" BO_ 309 2;
BA_ "Prio" BO_ 309 0;
BA_ "GenMsgSendType" BO_ 1922 0;
BA_ "GenMsgCycleTime" BO_ 1922 1000;
BA_ "MessageSubnet" BO_ 1922 2;
BA_ "Prio" BO_ 1922 0;
BA_ "GenMsgSendType" BO_ 352 0;
BA_ "GenMsgCycleTime" BO_ 352 100;
BA_ "GenMsgStartDelayTime" BO_ 352 30;
BA_ "MessageSubnet" BO_ 352 2;
BA_ "Prio" BO_ 352 0;
BA_ "GenMsgSendType" BO_ 562 0;
BA_ "GenMsgCycleTime" BO_ 562 50;
BA_ "MessageSubnet" BO_ 562 2;
BA_ "Prio" BO_ 562 0;
BA_ "GenMsgSendType" BO_ 893 0;
BA_ "GenMsgCycleTime" BO_ 893 100;
BA_ "MessageSubnet" BO_ 893 2;
BA_ "Prio" BO_ 893 0;
BA_ "GenMsgSendType" BO_ 892 0;
BA_ "GenMsgCycleTime" BO_ 892 100;
BA_ "MessageSubnet" BO_ 892 2;
BA_ "Prio" BO_ 892 0;
BA_ "GenMsgSendType" BO_ 386 0;
BA_ "GenMsgCycleTime" BO_ 386 100;
BA_ "MessageSubnet" BO_ 386 2;
BA_ "Prio" BO_ 386 0;
BA_ "DiagRequest" BO_ 597 1;
BA_ "MessageSubnet" BO_ 597 2;
BA_ "Prio" BO_ 597 0;
BA_ "GenMsgILSupport" BO_ 597 0;
BA_ "DiagResponse" BO_ 1621 1;
BA_ "MessageSubnet" BO_ 1621 2;
BA_ "Prio" BO_ 1621 0;
BA_ "GenMsgILSupport" BO_ 1621 0;
BA_ "GenMsgSendType" BO_ 532 0;
BA_ "GenMsgCycleTime" BO_ 532 50;
BA_ "MessageSubnet" BO_ 532 2;
BA_ "Prio" BO_ 532 0;
BA_ "GenMsgSendType" BO_ 890 0;
BA_ "GenMsgCycleTime" BO_ 890 100;
BA_ "MessageSubnet" BO_ 890 2;
BA_ "Prio" BO_ 890 0;
BA_ "DiagRequest" BO_ 592 1;
BA_ "MessageSubnet" BO_ 592 2;
BA_ "Prio" BO_ 592 0;
BA_ "MessageSubnet" BO_ 1365 2;
BA_ "Prio" BO_ 1365 0;
BA_ "TpApplType" BO_ 1365 "DiagUUDTResponse";
BA_ "GenMsgILSupport" BO_ 1365 0;
BA_ "GenMsgSendType" BO_ 328 0;
BA_ "GenMsgCycleTime" BO_ 328 1000;
BA_ "GenMsgDelayTime" BO_ 328 100;
BA_ "MessageSubnet" BO_ 328 2;
BA_ "Prio" BO_ 328 0;
